VERSION ""

NS_ :

BS_:

BU_: PFAF_HS LVMPC_HS DCDC_HS AMP_HS VICM2_HS FICM_HS ARS_HS MCP_B_HS MCP_A_HS ICCM_OBD_HS SAS_HS ACCM_HS VLBS_HS EBCM_OBD_HS EDI_HS HPCC_HS VITM_OBD_HS PTAM_HS OBCM_HS VICM_HS HCP_HS FDCM_HS APPS_HS ICCM_HS EOCM_F_HS GPCM_HS FSCM_ITBC_HS SCM_HS ITBC_HS VCM_HS HMIM_HS FCP_HS VES_HS Dummy_HS MCP_C_HS RWS_HS ONSTAR_HS EPS_HS TestTool_HS MCP_HS BCP_HS ALC_HS AHL_AFL_HS SADS_HS EPB_HS FSCM_HS AFS_HS FCM_HS TCCM_HS RDCM_HS PTO_HS PCM_HS EBCM_HS ACC_HS BCM_HS TCM_HS ECM_HS

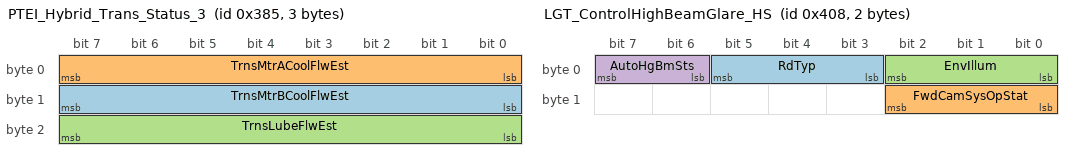
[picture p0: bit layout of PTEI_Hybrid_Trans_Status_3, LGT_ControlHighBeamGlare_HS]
BO_ 901 PTEI_Hybrid_Trans_Status_3: 3 TCM_HS
 SG_ TrnsMtrBCoolFlwEst : 15|8@0+ (0.05,0) [0|12.75] "l/min"  HCP_HS
 SG_ TrnsMtrACoolFlwEst : 7|8@0+ (0.05,0) [0|12.75] "l/min"  HCP_HS
 SG_ TrnsLubeFlwEst : 23|8@0+ (0.0625,0) [0|15.9375] "l/min"  HCP_HS

BO_ 1032 LGT_ControlHighBeamGlare_HS: 2 FCM_HS
 SG_ RdTyp : 5|3@0+ (1,0) [0|7] ""  AHL_AFL_HS
 SG_ FwdCamSysOpStat : 10|3@0+ (1,0) [0|7] ""  AHL_AFL_HS
 SG_ EnvIllum : 2|3@0+ (1,0) [0|7] ""  AHL_AFL_HS
 SG_ AutoHgBmSts : 7|2@0+ (1,0) [0|3] ""  AHL_AFL_HS

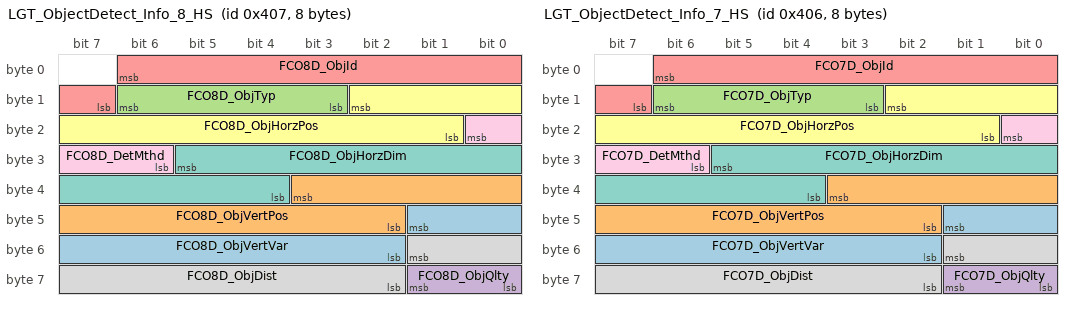
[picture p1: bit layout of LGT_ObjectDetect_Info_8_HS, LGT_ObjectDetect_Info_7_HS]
BO_ 1031 LGT_ObjectDetect_Info_8_HS: 8 FCM_HS
 SG_ FCO8D_ObjVertVar : 41|8@0- (0.05,0) [-6.4|6.35] "deg"  AHL_AFL_HS
 SG_ FCO8D_ObjVertPos : 35|10@0- (0.05,0) [-25.6|25.55] "deg"  AHL_AFL_HS
 SG_ FCO8D_ObjTyp : 14|4@0+ (1,0) [0|15] ""  AHL_AFL_HS
 SG_ FCO8D_ObjQlty : 57|2@0+ (1,0) [0|3] ""  AHL_AFL_HS
 SG_ FCO8D_ObjId : 6|8@0+ (1,0) [0|255] ""  AHL_AFL_HS
 SG_ FCO8D_ObjHorzPos : 10|10@0- (0.05,0) [-25.6|25.55] "deg"  AHL_AFL_HS
 SG_ FCO8D_ObjHorzDim : 29|10@0+ (0.01,0) [0|10.23] "deg"  AHL_AFL_HS
 SG_ FCO8D_ObjDist : 49|8@0+ (2,0) [0|510] "m"  AHL_AFL_HS
 SG_ FCO8D_DetMthd : 16|3@0+ (1,0) [0|7] ""  AHL_AFL_HS

BO_ 1030 LGT_ObjectDetect_Info_7_HS: 8 FCM_HS
 SG_ FCO7D_ObjVertVar : 41|8@0- (0.05,0) [-6.4|6.35] "deg"  AHL_AFL_HS
 SG_ FCO7D_ObjVertPos : 35|10@0- (0.05,0) [-25.6|25.55] "deg"  AHL_AFL_HS
 SG_ FCO7D_ObjTyp : 14|4@0+ (1,0) [0|15] ""  AHL_AFL_HS
 SG_ FCO7D_ObjQlty : 57|2@0+ (1,0) [0|3] ""  AHL_AFL_HS
 SG_ FCO7D_ObjId : 6|8@0+ (1,0) [0|255] ""  AHL_AFL_HS
 SG_ FCO7D_ObjHorzPos : 10|10@0- (0.05,0) [-25.6|25.55] "deg"  AHL_AFL_HS
 SG_ FCO7D_ObjHorzDim : 29|10@0+ (0.01,0) [0|10.23] "deg"  AHL_AFL_HS
 SG_ FCO7D_ObjDist : 49|8@0+ (2,0) [0|510] "m"  AHL_AFL_HS
 SG_ FCO7D_DetMthd : 16|3@0+ (1,0) [0|7] ""  AHL_AFL_HS

BO_ 479 PPEI_Propulsion_Gen_Stat_1_HS: 4 HCP_HS
 SG_ ASIRI_Indication16 : 24|1@0+ (1,0) [0|1] ""  BCM_HS
 SG_ ASIRI_Indication15 : 25|1@0+ (1,0) [0|1] ""  BCM_HS
 SG_ ASIRI_Indication14 : 26|1@0+ (1,0) [0|1] ""  BCM_HS
 SG_ ASIRI_Indication13 : 27|1@0+ (1,0) [0|1] ""  BCM_HS
 SG_ ASIRI_Indication12 : 28|1@0+ (1,0) [0|1] ""  BCM_HS
 SG_ ASIRI_Indication11 : 29|1@0+ (1,0) [0|1] ""  BCM_HS
 SG_ ASIRI_Indication10 : 30|1@0+ (1,0) [0|1] ""  BCM_HS
 SG_ ASIRI_Indication09 : 31|1@0+ (1,0) [0|1] ""  BCM_HS
 SG_ ASIRI_Indication08 : 16|1@0+ (1,0) [0|1] ""  BCM_HS
 SG_ ASIRI_Indication07 : 17|1@0+ (1,0) [0|1] ""  BCM_HS
 SG_ ASIRI_Indication06 : 18|1@0+ (1,0) [0|1] ""  BCM_HS
 SG_ ASIRI_Indication05 : 19|1@0+ (1,0) [0|1] ""  BCM_HS
 SG_ ASIRI_Indication04 : 20|1@0+ (1,0) [0|1] ""  BCM_HS
 SG_ ASIRI_Indication03 : 21|1@0+ (1,0) [0|1] ""  BCM_HS
 SG_ ASIRI_Indication02 : 22|1@0+ (1,0) [0|1] ""  BCM_HS
 SG_ ASIRI_Indication01 : 23|1@0+ (1,0) [0|1] ""  BCM_HS
 SG_ PTWrmgWtToShftIO : 5|1@0+ (1,0) [0|1] ""  BCM_HS
 SG_ PrplsnSysAtv : 7|1@0+ (1,0) [0|1] ""  EPB_HS,TCM_HS,ECM_HS,TCCM_HS,VICM_HS,ICCM_OBD_HS,ICCM_HS,FSCM_HS,ACCM_HS,EBCM_OBD_HS,EBCM_HS,OBCM_HS,VICM2_HS,VITM_OBD_HS
 SG_ PTShftLvrLckRqd : 6|1@0+ (1,0) [0|1] ""  BCM_HS

BO_ 211 PPEI_Hybrid_General_Status_3_HS: 2 HCP_HS
 SG_ ActAxleTrqV : 7|1@0+ (1,0) [0|1] ""  SADS_HS,ICCM_OBD_HS,ICCM_HS,TCM_HS,PCM_HS,ECM_HS,EBCM_OBD_HS,EBCM_HS,BCP_HS,EOCM_F_HS,VICM_HS,TCCM_HS,ACC_HS
 SG_ ActAxleTrq : 6|15@0+ (2,-22534) [-22534|43000] "Nm"  SADS_HS,ICCM_OBD_HS,ICCM_HS,EBCM_OBD_HS,EBCM_HS,TCM_HS,PCM_HS,ECM_HS,BCP_HS,EOCM_F_HS,TCCM_HS,VICM_HS,ACC_HS

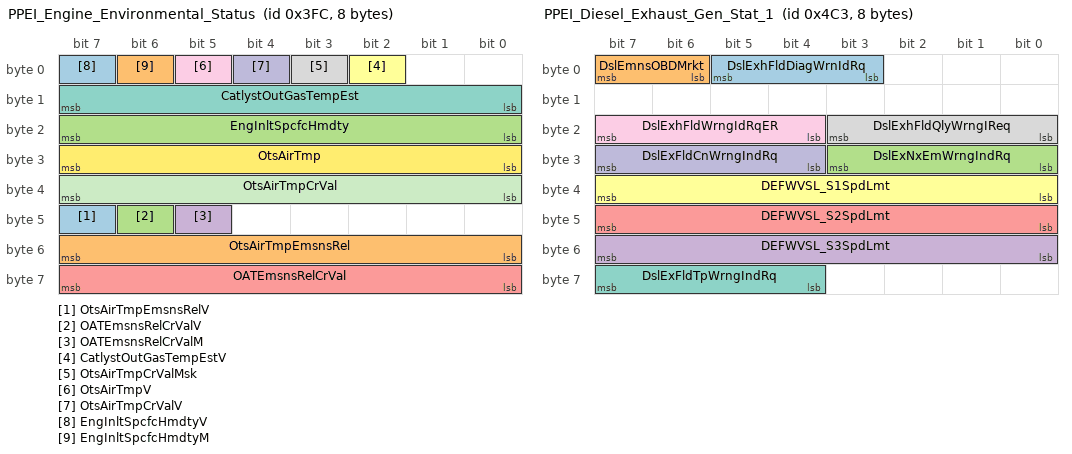
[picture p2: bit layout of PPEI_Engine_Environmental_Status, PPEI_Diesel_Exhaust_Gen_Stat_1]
BO_ 1020 PPEI_Engine_Environmental_Status: 8 ECM_HS
 SG_ OtsAirTmpEmsnsRelV : 47|1@0+ (1,0) [0|1] ""  VICM_HS
 SG_ OtsAirTmpEmsnsRel : 55|8@0+ (0.5,-40) [-40|87.5] "deg C"  VICM_HS
 SG_ OATEmsnsRelCrValV : 46|1@0+ (1,0) [0|1] ""  VICM_HS
 SG_ OATEmsnsRelCrValM : 45|1@0+ (1,0) [0|1] ""  VICM_HS
 SG_ OATEmsnsRelCrVal : 63|8@0+ (0.5,-40) [-40|87.5] "deg C"  VICM_HS
 SG_ CatlystOutGasTempEstV : 2|1@0+ (1,0) [0|1] ""  VICM_HS
 SG_ CatlystOutGasTempEst : 15|8@0+ (5,-40) [-40|1235] "deg C"  VICM_HS
 SG_ OtsAirTmpCrValMsk : 3|1@0+ (1,0) [0|1] ""  VICM_HS,BCM_HS
 SG_ OtsAirTmpV : 5|1@0+ (1,0) [0|1] ""  VICM_HS,BCM_HS
 SG_ OtsAirTmpCrValV : 4|1@0+ (1,0) [0|1] ""  VICM_HS,BCM_HS
 SG_ OtsAirTmpCrVal : 39|8@0+ (0.5,-40) [-40|87.5] "deg C"  VICM_HS,BCM_HS
 SG_ OtsAirTmp : 31|8@0+ (0.5,-40) [-40|87.5] "deg C"  VICM_HS,BCM_HS
 SG_ EngInltSpcfcHmdtyV : 7|1@0+ (1,0) [0|1] ""  VICM_HS,BCM_HS,EBCM_OBD_HS,EBCM_HS
 SG_ EngInltSpcfcHmdtyM : 6|1@0+ (1,0) [0|1] ""  VICM_HS,BCM_HS,EBCM_OBD_HS,EBCM_HS
 SG_ EngInltSpcfcHmdty : 23|8@0+ (0.0196078,0) [0|4.999989] "% water"  VICM_HS,BCM_HS,EBCM_OBD_HS,EBCM_HS

BO_ 1219 PPEI_Diesel_Exhaust_Gen_Stat_1: 8 ECM_HS
 SG_ DslExhFldDiagWrnIdRq : 5|3@0+ (1,0) [0|7] ""  BCM_HS
 SG_ DslEmnsOBDMrkt : 7|2@0+ (1,0) [0|3] ""  BCM_HS
 SG_ DslExNxEmWrngIndRq : 27|4@0+ (1,0) [0|15] ""  BCM_HS
 SG_ DEFWVSL_S3SpdLmt : 55|8@0+ (1,0) [0|255] "km / h"  BCM_HS
 SG_ DEFWVSL_S2SpdLmt : 47|8@0+ (1,0) [0|255] "km / h"  BCM_HS
 SG_ DEFWVSL_S1SpdLmt : 39|8@0+ (1,0) [0|255] "km / h"  BCM_HS
 SG_ DslExFldTpWrngIndRq : 63|4@0+ (1,0) [0|15] ""  BCM_HS
 SG_ DslExhFldQlyWrngIReq : 19|4@0+ (1,0) [0|15] ""  BCM_HS
 SG_ DslExhFldWrngIdRqER : 23|4@0+ (1,0) [0|15] ""  BCM_HS,FCP_HS,ONSTAR_HS
 SG_ DslExFldCnWrngIndRq : 31|4@0+ (1,0) [0|15] ""  BCM_HS

BO_ 372 Active_Rear_Steer_Fail_Indctn_HS: 1 ARS_HS
 SG_ ARSFlrIO : 0|1@0+ (1,0) [0|1] ""  BCM_HS

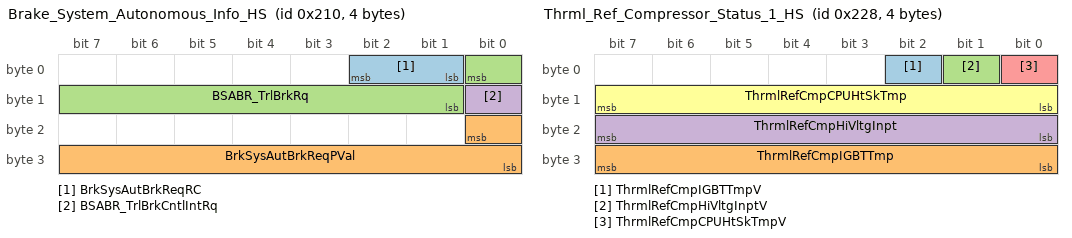
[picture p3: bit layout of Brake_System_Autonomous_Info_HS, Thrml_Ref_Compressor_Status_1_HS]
BO_ 528 Brake_System_Autonomous_Info_HS: 4 EBCM_HS
 SG_ BrkSysAutBrkReqRC : 2|2@0+ (1,0) [0|3] ""  FSCM_ITBC_HS
 SG_ BrkSysAutBrkReqPVal : 16|9@0+ (1,0) [0|511] ""  FSCM_ITBC_HS
 SG_ BSABR_TrlBrkRq : 0|8@0+ (0.392157,0) [0|100.000035] "%"  FSCM_ITBC_HS
 SG_ BSABR_TrlBrkCntlIntRq : 8|1@0+ (1,0) [0|1] ""  FSCM_ITBC_HS

BO_ 552 Thrml_Ref_Compressor_Status_1_HS: 4 ACCM_HS
 SG_ ThrmlRefCmpIGBTTmpV : 2|1@0+ (1,0) [0|1] ""  VICM_HS
 SG_ ThrmlRefCmpIGBTTmp : 31|8@0+ (1,-40) [-40|215] "deg C"  VICM_HS
 SG_ ThrmlRefCmpHiVltgInptV : 1|1@0+ (1,0) [0|1] ""  VICM_HS
 SG_ ThrmlRefCmpHiVltgInpt : 23|8@0+ (4,0) [0|1020] "V"  VICM_HS
 SG_ ThrmlRefCmpCPUHtSkTmpV : 0|1@0+ (1,0) [0|1] ""  VICM_HS
 SG_ ThrmlRefCmpCPUHtSkTmp : 15|8@0+ (1,-40) [-40|215] "deg C"  VICM_HS

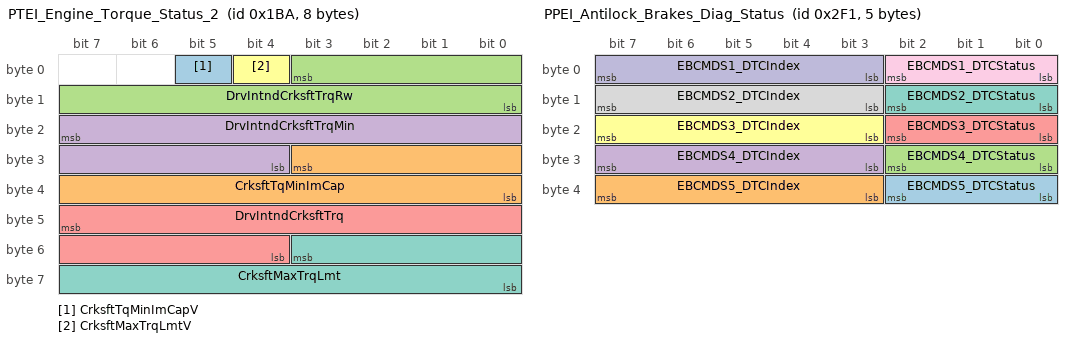
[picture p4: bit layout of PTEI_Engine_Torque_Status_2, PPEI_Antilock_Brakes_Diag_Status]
BO_ 442 PTEI_Engine_Torque_Status_2: 8 ECM_HS
 SG_ CrksftTqMinImCapV : 5|1@0+ (1,0) [0|1] ""  TCM_HS
 SG_ CrksftTqMinImCap : 27|12@0+ (0.5,-848) [-848|1199.5] "Nm"  TCM_HS
 SG_ DrvIntndCrksftTrqRw : 3|12@0+ (0.5,-848) [-848|1199.5] "Nm"  TCM_HS
 SG_ DrvIntndCrksftTrqMin : 23|12@0+ (0.5,-848) [-848|1199.5] "Nm"  TCM_HS
 SG_ DrvIntndCrksftTrq : 47|12@0+ (0.5,-848) [-848|1199.5] "Nm"  TCM_HS
 SG_ CrksftMaxTrqLmtV : 4|1@0+ (1,0) [0|1] ""  TCM_HS
 SG_ CrksftMaxTrqLmt : 51|12@0+ (0.5,-848) [-848|1199.5] "Nm"  TCM_HS

BO_ 753 PPEI_Antilock_Brakes_Diag_Status: 5 EBCM_HS
 SG_ EBCMDS5_DTCStatus : 34|3@0+ (1,0) [0|7] ""  ECM_HS
 SG_ EBCMDS5_DTCIndex : 39|5@0+ (1,0) [0|31] ""  ECM_HS
 SG_ EBCMDS4_DTCStatus : 26|3@0+ (1,0) [0|7] ""  ECM_HS
 SG_ EBCMDS4_DTCIndex : 31|5@0+ (1,0) [0|31] ""  ECM_HS
 SG_ EBCMDS3_DTCStatus : 18|3@0+ (1,0) [0|7] ""  ECM_HS
 SG_ EBCMDS3_DTCIndex : 23|5@0+ (1,0) [0|31] ""  ECM_HS
 SG_ EBCMDS2_DTCStatus : 10|3@0+ (1,0) [0|7] ""  ECM_HS
 SG_ EBCMDS2_DTCIndex : 15|5@0+ (1,0) [0|31] ""  ECM_HS
 SG_ EBCMDS1_DTCStatus : 2|3@0+ (1,0) [0|7] ""  ECM_HS
 SG_ EBCMDS1_DTCIndex : 7|5@0+ (1,0) [0|31] ""  ECM_HS

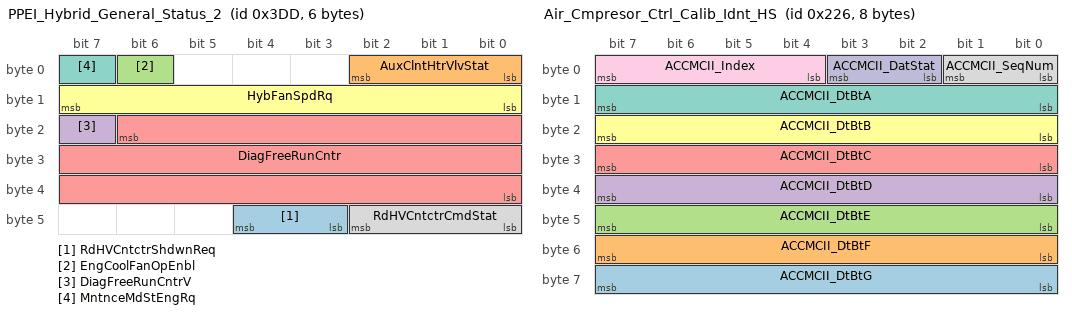
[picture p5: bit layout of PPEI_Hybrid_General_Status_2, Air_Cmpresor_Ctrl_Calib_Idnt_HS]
BO_ 989 PPEI_Hybrid_General_Status_2: 6 VICM_HS
 SG_ RdHVCntctrShdwnReq : 44|2@0+ (1,0) [0|3] ""  HCP_HS
 SG_ AuxClntHtrVlvStat : 2|3@0+ (1,0) [0|7] ""  PCM_HS,ECM_HS
 SG_ EngCoolFanOpEnbl : 6|1@0+ (1,0) [0|1] ""  PCM_HS,ECM_HS
 SG_ DiagFreeRunCntrV : 23|1@0+ (1,0) [0|1] ""  ECM_HS
 SG_ DiagFreeRunCntr : 22|23@0+ (1,0) [0|8388607] "min"  ECM_HS
 SG_ HybFanSpdRq : 15|8@0+ (0.392157,0) [0|100.000035] "%"  PCM_HS,ECM_HS
 SG_ MntnceMdStEngRq : 7|1@0+ (1,0) [0|1] ""  ECM_HS
 SG_ RdHVCntctrCmdStat : 42|3@0+ (1,0) [0|7] ""  HCP_HS

BO_ 550 Air_Cmpresor_Ctrl_Calib_Idnt_HS: 8 ACCM_HS
 SG_ ACCMCII_DtBtG : 63|8@0+ (1,0) [0|0] ""  VICM_HS
 SG_ ACCMCII_DtBtF : 55|8@0+ (1,0) [0|0] ""  VICM_HS
 SG_ ACCMCII_DtBtE : 47|8@0+ (1,0) [0|0] ""  VICM_HS
 SG_ ACCMCII_DtBtD : 39|8@0+ (1,0) [0|0] ""  VICM_HS
 SG_ ACCMCII_DtBtC : 31|8@0+ (1,0) [0|0] ""  VICM_HS
 SG_ ACCMCII_DtBtB : 23|8@0+ (1,0) [0|0] ""  VICM_HS
 SG_ ACCMCII_DtBtA : 15|8@0+ (1,0) [0|0] ""  VICM_HS
 SG_ ACCMCII_SeqNum : 1|2@0+ (1,0) [0|3] ""  VICM_HS
 SG_ ACCMCII_Index : 7|4@0+ (1,0) [0|15] ""  VICM_HS
 SG_ ACCMCII_DatStat : 3|2@0+ (1,0) [0|3] ""  VICM_HS

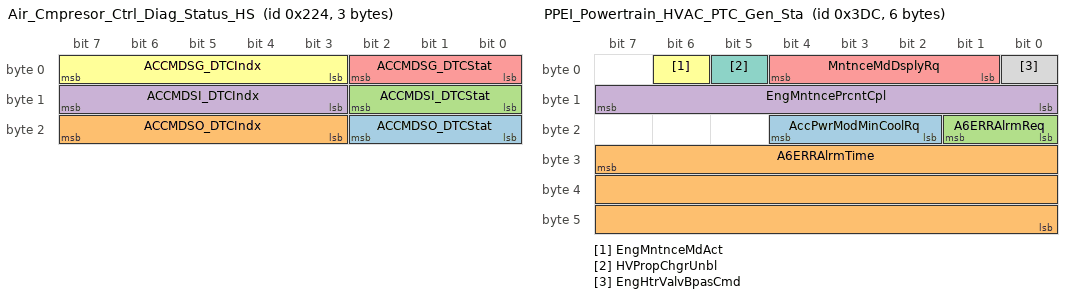
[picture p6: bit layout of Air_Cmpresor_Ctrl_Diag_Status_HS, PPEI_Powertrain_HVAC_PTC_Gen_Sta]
BO_ 548 Air_Cmpresor_Ctrl_Diag_Status_HS: 3 ACCM_HS
 SG_ ACCMDSO_DTCStat : 18|3@0+ (1,0) [0|7] ""  VICM_HS
 SG_ ACCMDSO_DTCIndx : 23|5@0+ (1,0) [0|31] ""  VICM_HS
 SG_ ACCMDSI_DTCStat : 10|3@0+ (1,0) [0|7] ""  VICM_HS
 SG_ ACCMDSI_DTCIndx : 15|5@0+ (1,0) [0|31] ""  VICM_HS
 SG_ ACCMDSG_DTCStat : 2|3@0+ (1,0) [0|7] ""  VICM_HS
 SG_ ACCMDSG_DTCIndx : 7|5@0+ (1,0) [0|31] ""  VICM_HS

BO_ 988 PPEI_Powertrain_HVAC_PTC_Gen_Sta: 6 ECM_HS
 SG_ AccPwrModMinCoolRq : 20|3@0+ (1,0) [0|7] ""  VICM_HS
 SG_ A6ERRAlrmTime : 31|24@0+ (1,0) [0|16777215] "min"  VICM_HS
 SG_ A6ERRAlrmReq : 17|2@0+ (1,0) [0|3] ""  VICM_HS
 SG_ EngMntncePrcntCpl : 15|8@0+ (0.392157,0) [0|100.000035] "%"  VICM_HS
 SG_ MntnceMdDsplyRq : 4|4@0+ (1,0) [0|15] ""  VICM_HS
 SG_ EngMntnceMdAct : 6|1@0+ (1,0) [0|1] ""  VICM_HS
 SG_ HVPropChgrUnbl : 5|1@0+ (1,0) [0|1] ""  HCP_HS,VICM_HS
 SG_ EngHtrValvBpasCmd : 0|1@0+ (1,0) [0|1] ""  VICM_HS

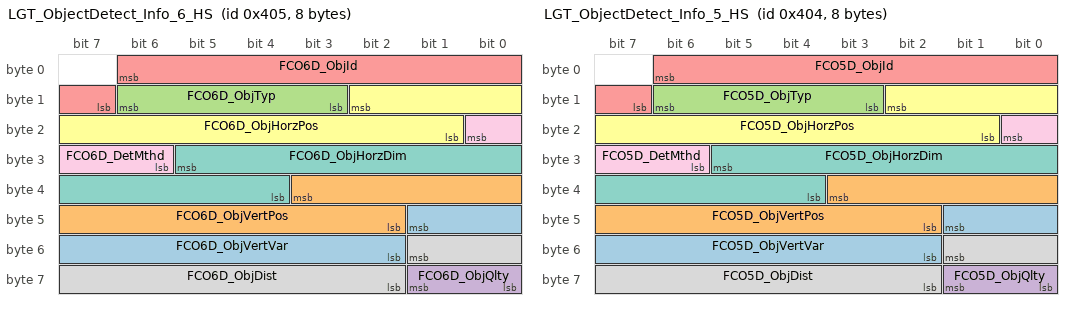
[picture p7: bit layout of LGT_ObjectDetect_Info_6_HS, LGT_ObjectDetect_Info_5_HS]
BO_ 1029 LGT_ObjectDetect_Info_6_HS: 8 FCM_HS
 SG_ FCO6D_ObjVertVar : 41|8@0- (0.05,0) [-6.4|6.35] "deg"  AHL_AFL_HS
 SG_ FCO6D_ObjVertPos : 35|10@0- (0.05,0) [-25.6|25.55] "deg"  AHL_AFL_HS
 SG_ FCO6D_ObjTyp : 14|4@0+ (1,0) [0|15] ""  AHL_AFL_HS
 SG_ FCO6D_ObjQlty : 57|2@0+ (1,0) [0|3] ""  AHL_AFL_HS
 SG_ FCO6D_ObjId : 6|8@0+ (1,0) [0|255] ""  AHL_AFL_HS
 SG_ FCO6D_ObjHorzPos : 10|10@0- (0.05,0) [-25.6|25.55] "deg"  AHL_AFL_HS
 SG_ FCO6D_ObjHorzDim : 29|10@0+ (0.01,0) [0|10.23] "deg"  AHL_AFL_HS
 SG_ FCO6D_ObjDist : 49|8@0+ (2,0) [0|510] "m"  AHL_AFL_HS
 SG_ FCO6D_DetMthd : 16|3@0+ (1,0) [0|7] ""  AHL_AFL_HS

BO_ 1028 LGT_ObjectDetect_Info_5_HS: 8 FCM_HS
 SG_ FCO5D_ObjVertVar : 41|8@0- (0.05,0) [-6.4|6.35] "deg"  AHL_AFL_HS
 SG_ FCO5D_ObjVertPos : 35|10@0- (0.05,0) [-25.6|25.55] "deg"  AHL_AFL_HS
 SG_ FCO5D_ObjTyp : 14|4@0+ (1,0) [0|15] ""  AHL_AFL_HS
 SG_ FCO5D_ObjQlty : 57|2@0+ (1,0) [0|3] ""  AHL_AFL_HS
 SG_ FCO5D_ObjId : 6|8@0+ (1,0) [0|255] ""  AHL_AFL_HS
 SG_ FCO5D_ObjHorzPos : 10|10@0- (0.05,0) [-25.6|25.55] "deg"  AHL_AFL_HS
 SG_ FCO5D_ObjHorzDim : 29|10@0+ (0.01,0) [0|10.23] ""  AHL_AFL_HS
 SG_ FCO5D_ObjDist : 49|8@0+ (2,0) [0|510] "m"  AHL_AFL_HS
 SG_ FCO5D_DetMthd : 16|3@0+ (1,0) [0|7] ""  AHL_AFL_HS

BO_ 500 PPEI_Drv_Pref_Mode_Switch_Status: 6 ECM_HS
 SG_ EnhDrvMdSwChUseAct : 40|1@0+ (1,0) [0|1] ""  EBCM_OBD_HS,EBCM_HS
 SG_ EnhDrvSelMdSwStat : 42|2@0+ (1,0) [0|3] ""  EBCM_OBD_HS,EBCM_HS
 SG_ DrvSelMd8Stat : 17|1@0+ (1,0) [0|1] ""  EBCM_OBD_HS,EBCM_HS,BCM_HS
 SG_ DrvSelMd8ReqDnd : 16|1@0+ (1,0) [0|1] ""  BCM_HS
 SG_ DrvSelMd7Stat : 19|1@0+ (1,0) [0|1] ""  EBCM_OBD_HS,EBCM_HS,BCM_HS
 SG_ DrvSelMd7ReqDnd : 18|1@0+ (1,0) [0|1] ""  BCM_HS
 SG_ DrvSelMd6Stat : 21|1@0+ (1,0) [0|1] ""  EBCM_OBD_HS,EBCM_HS,BCM_HS
 SG_ DrvSelMd6ReqDnd : 20|1@0+ (1,0) [0|1] ""  BCM_HS
 SG_ DrvSelMd5Stat : 23|1@0+ (1,0) [0|1] ""  EBCM_OBD_HS,EBCM_HS,BCM_HS
 SG_ DrvSelMd5ReqDnd : 22|1@0+ (1,0) [0|1] ""  BCM_HS
 SG_ DrvSelMd4Stat : 9|1@0+ (1,0) [0|1] ""  EBCM_OBD_HS,EBCM_HS,BCM_HS
 SG_ DrvSelMd4ReqDnd : 8|1@0+ (1,0) [0|1] ""  BCM_HS
 SG_ DrvSelMd3Stat : 11|1@0+ (1,0) [0|1] ""  EBCM_OBD_HS,EBCM_HS,BCM_HS
 SG_ DrvSelMd3ReqDnd : 10|1@0+ (1,0) [0|1] ""  BCM_HS
 SG_ DrvSelMd2Stat : 13|1@0+ (1,0) [0|1] ""  EBCM_OBD_HS,EBCM_HS,BCM_HS
 SG_ DrvSelMd2ReqDnd : 12|1@0+ (1,0) [0|1] ""  BCM_HS
 SG_ DSMSS_DrvSelMd0Pn : 47|1@0+ (1,0) [0|1] ""  EBCM_OBD_HS,EBCM_HS,BCM_HS
 SG_ DSMSS_DrvSelMd8Pn : 32|1@0+ (1,0) [0|1] ""  EBCM_OBD_HS,EBCM_HS,BCM_HS
 SG_ DSMSS_DrvSelMd7Pn : 33|1@0+ (1,0) [0|1] ""  EBCM_OBD_HS,EBCM_HS,BCM_HS
 SG_ DSMSS_DrvSelMd6Pn : 34|1@0+ (1,0) [0|1] ""  EBCM_OBD_HS,EBCM_HS,BCM_HS
 SG_ DSMSS_DrvSelMd5Pn : 35|1@0+ (1,0) [0|1] ""  EBCM_OBD_HS,EBCM_HS,BCM_HS
 SG_ DSMSS_DrvSelMd4Pn : 36|1@0+ (1,0) [0|1] ""  EBCM_OBD_HS,EBCM_HS,BCM_HS
 SG_ DSMSS_DrvSelMd3Pn : 37|1@0+ (1,0) [0|1] ""  EBCM_OBD_HS,EBCM_HS,BCM_HS
 SG_ DSMSS_DrvSelMd2Pn : 38|1@0+ (1,0) [0|1] ""  EBCM_OBD_HS,EBCM_HS,BCM_HS
 SG_ DSMSS_DrvSelMd1Pn : 39|1@0+ (1,0) [0|1] ""  EBCM_OBD_HS,EBCM_HS,BCM_HS
 SG_ DSMSS_DrvSelMd8Un : 24|1@0+ (1,0) [0|1] ""  EBCM_OBD_HS,EBCM_HS,BCM_HS
 SG_ DSMSS_DrvSelMd7Un : 25|1@0+ (1,0) [0|1] ""  EBCM_OBD_HS,EBCM_HS,BCM_HS
 SG_ DSMSS_DrvSelMd6Un : 26|1@0+ (1,0) [0|1] ""  EBCM_OBD_HS,EBCM_HS,BCM_HS
 SG_ DSMSS_DrvSelMd5Un : 27|1@0+ (1,0) [0|1] ""  EBCM_OBD_HS,EBCM_HS,BCM_HS
 SG_ DSMSS_DrvSelMd4Un : 28|1@0+ (1,0) [0|1] ""  EBCM_OBD_HS,EBCM_HS,BCM_HS
 SG_ DSMSS_DrvSelMd3Un : 29|1@0+ (1,0) [0|1] ""  EBCM_OBD_HS,EBCM_HS,BCM_HS
 SG_ DSMSS_DrvSelMd2Un : 30|1@0+ (1,0) [0|1] ""  EBCM_OBD_HS,EBCM_HS,BCM_HS
 SG_ DSMSS_DrvSelMd1Un : 31|1@0+ (1,0) [0|1] ""  EBCM_OBD_HS,EBCM_HS,BCM_HS
 SG_ DrvSelMd1ReqDnd : 14|1@0+ (1,0) [0|1] ""  VICM_HS,BCM_HS
 SG_ DrvSelMd1Stat : 15|1@0+ (1,0) [0|1] ""  EBCM_OBD_HS,EBCM_HS,BCM_HS

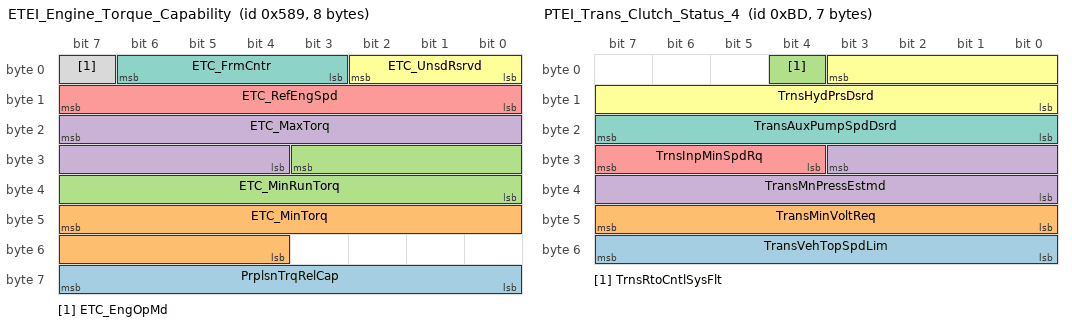
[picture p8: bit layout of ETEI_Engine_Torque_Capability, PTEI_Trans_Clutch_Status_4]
BO_ 1417 ETEI_Engine_Torque_Capability: 8 ECM_HS
 SG_ PrplsnTrqRelCap : 63|8@0+ (0.5,0) [0|127.5] "%"  TCM_HS
 SG_ ETC_MinTorq : 47|12@0+ (0.5,-848) [-848|1199.5] "Nm"  TCM_HS,HCP_HS,BCP_HS
 SG_ ETC_MinRunTorq : 27|12@0+ (0.5,-848) [-848|1199.5] "Nm"  TCM_HS,HCP_HS,BCP_HS
 SG_ ETC_MaxTorq : 23|12@0+ (0.5,-848) [-848|1199.5] "Nm"  TCM_HS,HCP_HS,BCP_HS
 SG_ ETC_RefEngSpd : 15|8@0+ (32,0) [0|8160] "rpm"  TCM_HS,HCP_HS,BCP_HS
 SG_ ETC_UnsdRsrvd : 2|3@0+ (1,0) [0|7] ""  TCM_HS,HCP_HS,BCP_HS
 SG_ ETC_FrmCntr : 6|4@0+ (1,0) [0|15] ""  TCM_HS,HCP_HS,BCP_HS
 SG_ ETC_EngOpMd : 7|1@0+ (1,0) [0|1] ""  TCM_HS,HCP_HS,BCP_HS

BO_ 407 PTEI_Trans_Ratio_Status: 2 TCM_HS
 SG_ TrnsOvrallActTorqRatioV : 7|1@0+ (1,0) [0|1] ""  PCM_HS,ECM_HS
 SG_ TrnsOvrallActTorqRatio : 6|15@0- (0.00390625,0) [-64|63.99609375] ""  PCM_HS,ECM_HS

BO_ 189 PTEI_Trans_Clutch_Status_4: 7 TCM_HS
 SG_ TransVehTopSpdLim : 55|8@0+ (2,0) [0|510] "km / h"  PCM_HS,ECM_HS
 SG_ TransMinVoltReq : 47|8@0+ (0.07843,0) [0|19.99965] "volts"  PCM_HS,ECM_HS
 SG_ TrnsRtoCntlSysFlt : 4|1@0+ (1,0) [0|1] "" Vector__XXX
 SG_ TransMnPressEstmd : 27|12@0+ (0.5,0) [0|2047.5] "kPa"  HCP_HS
 SG_ TrnsInpMinSpdRq : 31|4@0+ (1,0) [0|15] ""  HCP_HS
 SG_ TrnsHydPrsDsrd : 3|12@0+ (0.5,0) [0|2047.5] "kPa"  HCP_HS
 SG_ TransAuxPumpSpdDsrd : 23|8@0+ (0.392157,0) [0|100.000035] "%"  HCP_HS

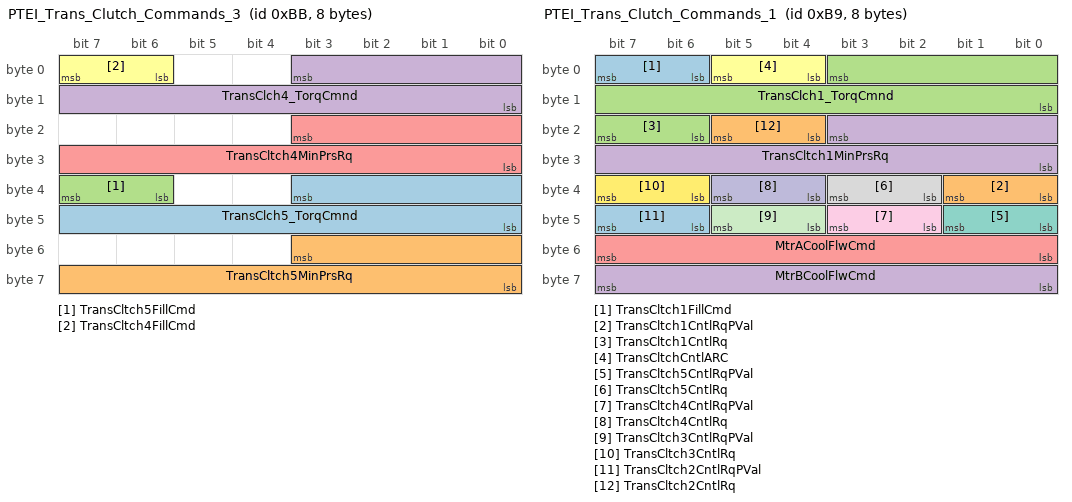
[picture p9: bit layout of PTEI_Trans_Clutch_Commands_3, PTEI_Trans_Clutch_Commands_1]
BO_ 187 PTEI_Trans_Clutch_Commands_3: 8 HCP_HS
 SG_ TransClch5_TorqCmnd : 35|12@0+ (0.5,-5) [-5|2042.5] "Nm"  TCM_HS
 SG_ TransCltch5MinPrsRq : 51|12@0+ (0.5,0) [0|2047.5] "kPa"  TCM_HS
 SG_ TransCltch5FillCmd : 39|2@0+ (1,0) [0|3] ""  TCM_HS
 SG_ TransClch4_TorqCmnd : 3|12@0+ (0.5,-5) [-5|2042.5] "Nm"  TCM_HS
 SG_ TransCltch4MinPrsRq : 19|12@0+ (0.5,0) [0|2047.5] "kPa"  TCM_HS
 SG_ TransCltch4FillCmd : 7|2@0+ (1,0) [0|3] ""  TCM_HS

BO_ 185 PTEI_Trans_Clutch_Commands_1: 8 HCP_HS
 SG_ TransCltch1FillCmd : 7|2@0+ (1,0) [0|3] ""  TCM_HS
 SG_ TransCltch1CntlRqPVal : 33|2@0+ (1,0) [0|3] ""  TCM_HS
 SG_ TransCltch1CntlRq : 23|2@0+ (1,0) [0|3] ""  TCM_HS
 SG_ MtrBCoolFlwCmd : 63|8@0+ (0.05,0) [0|12.75] "l/min"  TCM_HS
 SG_ MtrACoolFlwCmd : 55|8@0+ (0.05,0) [0|12.75] "l/min"  TCM_HS
 SG_ TransCltchCntlARC : 5|2@0+ (1,0) [0|3] ""  TCM_HS
 SG_ TransCltch5CntlRqPVal : 41|2@0+ (1,0) [0|3] ""  TCM_HS
 SG_ TransCltch5CntlRq : 35|2@0+ (1,0) [0|3] ""  TCM_HS
 SG_ TransCltch4CntlRqPVal : 43|2@0+ (1,0) [0|3] ""  TCM_HS
 SG_ TransCltch4CntlRq : 37|2@0+ (1,0) [0|3] ""  TCM_HS
 SG_ TransCltch3CntlRqPVal : 45|2@0+ (1,0) [0|3] ""  TCM_HS
 SG_ TransCltch3CntlRq : 39|2@0+ (1,0) [0|3] ""  TCM_HS
 SG_ TransCltch2CntlRqPVal : 47|2@0+ (1,0) [0|3] ""  TCM_HS
 SG_ TransCltch2CntlRq : 21|2@0+ (1,0) [0|3] ""  TCM_HS
 SG_ TransClch1_TorqCmnd : 3|12@0+ (0.5,-5) [-5|2042.5] "Nm"  TCM_HS
 SG_ TransCltch1MinPrsRq : 19|12@0+ (0.5,0) [0|2047.5] "kPa"  TCM_HS

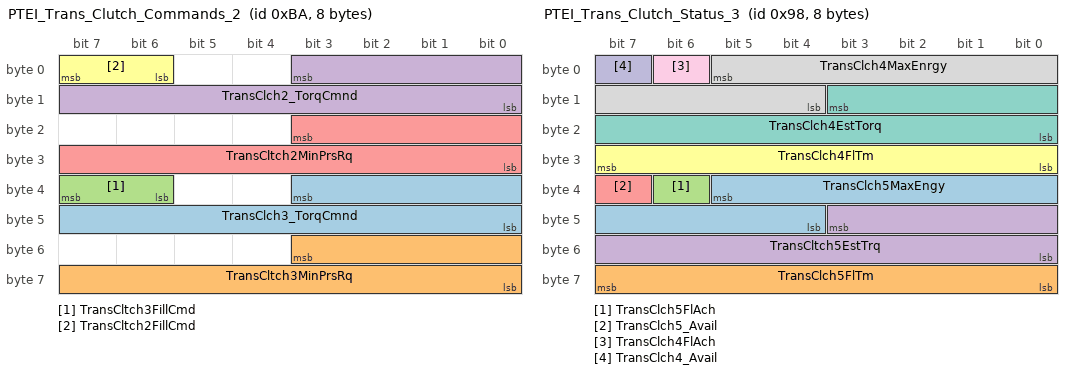
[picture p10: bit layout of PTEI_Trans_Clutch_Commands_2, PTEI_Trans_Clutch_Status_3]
BO_ 186 PTEI_Trans_Clutch_Commands_2: 8 HCP_HS
 SG_ TransClch3_TorqCmnd : 35|12@0+ (0.5,-5) [-5|2042.5] "Nm"  TCM_HS
 SG_ TransCltch3MinPrsRq : 51|12@0+ (0.5,0) [0|2047.5] "kPa"  TCM_HS
 SG_ TransCltch3FillCmd : 39|2@0+ (1,0) [0|3] ""  TCM_HS
 SG_ TransClch2_TorqCmnd : 3|12@0+ (0.5,-5) [-5|2042.5] "Nm"  TCM_HS
 SG_ TransCltch2MinPrsRq : 19|12@0+ (0.5,0) [0|2047.5] "kPa"  TCM_HS
 SG_ TransCltch2FillCmd : 7|2@0+ (1,0) [0|3] ""  TCM_HS

BO_ 152 PTEI_Trans_Clutch_Status_3: 8 TCM_HS
 SG_ TransClch5MaxEngy : 37|10@0+ (50,0) [0|51150] "J"  HCP_HS
 SG_ TransClch5FlTm : 63|8@0+ (0.0125,0) [0|3.1875] "s"  HCP_HS
 SG_ TransClch5FlAch : 38|1@0+ (1,0) [0|1] ""  HCP_HS
 SG_ TransCltch5EstTrq : 43|12@0+ (0.5,-5) [-5|2042.5] "Nm"  HCP_HS
 SG_ TransClch5_Avail : 39|1@0+ (1,0) [0|1] ""  HCP_HS
 SG_ TransClch4FlTm : 31|8@0+ (0.0125,0) [0|3.1875] "s"  HCP_HS
 SG_ TransClch4EstTorq : 11|12@0+ (0.5,-5) [-5|2042.5] "Nm"  HCP_HS
 SG_ TransClch4MaxEnrgy : 5|10@0+ (50,0) [0|51150] "J"  HCP_HS
 SG_ TransClch4FlAch : 6|1@0+ (1,0) [0|1] ""  HCP_HS
 SG_ TransClch4_Avail : 7|1@0+ (1,0) [0|1] ""  HCP_HS

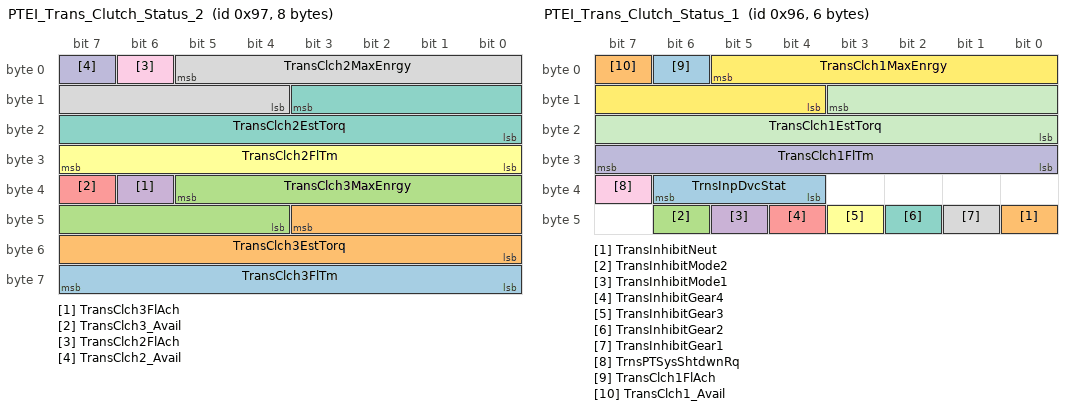
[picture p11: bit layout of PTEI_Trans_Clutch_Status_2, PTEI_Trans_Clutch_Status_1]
BO_ 151 PTEI_Trans_Clutch_Status_2: 8 TCM_HS
 SG_ TransClch3FlTm : 63|8@0+ (0.0125,0) [0|3.1875] "s"  HCP_HS
 SG_ TransClch3EstTorq : 43|12@0+ (0.5,-5) [-5|2042.5] "Nm"  HCP_HS
 SG_ TransClch3MaxEnrgy : 37|10@0+ (50,0) [0|51150] "J"  HCP_HS
 SG_ TransClch3FlAch : 38|1@0+ (1,0) [0|1] ""  HCP_HS
 SG_ TransClch3_Avail : 39|1@0+ (1,0) [0|1] ""  HCP_HS
 SG_ TransClch2FlTm : 31|8@0+ (0.0125,0) [0|3.1875] "s"  HCP_HS
 SG_ TransClch2EstTorq : 11|12@0+ (0.5,-5) [-5|2042.5] "Nm"  HCP_HS
 SG_ TransClch2MaxEnrgy : 5|10@0+ (50,0) [0|51150] "J"  HCP_HS
 SG_ TransClch2FlAch : 6|1@0+ (1,0) [0|1] ""  HCP_HS
 SG_ TransClch2_Avail : 7|1@0+ (1,0) [0|1] ""  HCP_HS

BO_ 150 PTEI_Trans_Clutch_Status_1: 6 TCM_HS
 SG_ TrnsInpDvcStat : 38|3@0+ (1,0) [0|7] ""  HCP_HS
 SG_ TransInhibitNeut : 40|1@0+ (1,0) [0|1] ""  HCP_HS
 SG_ TransInhibitMode2 : 46|1@0+ (1,0) [0|1] ""  HCP_HS
 SG_ TransInhibitMode1 : 45|1@0+ (1,0) [0|1] ""  HCP_HS
 SG_ TransInhibitGear4 : 44|1@0+ (1,0) [0|1] ""  HCP_HS
 SG_ TransInhibitGear3 : 43|1@0+ (1,0) [0|1] ""  HCP_HS
 SG_ TransInhibitGear2 : 42|1@0+ (1,0) [0|1] ""  HCP_HS
 SG_ TransInhibitGear1 : 41|1@0+ (1,0) [0|1] ""  HCP_HS
 SG_ TrnsPTSysShtdwnRq : 39|1@0+ (1,0) [0|1] ""  HCP_HS
 SG_ TransClch1FlTm : 31|8@0+ (0.0125,0) [0|3.1875] "s"  HCP_HS
 SG_ TransClch1EstTorq : 11|12@0+ (0.5,-5) [-5|2042.5] "Nm"  HCP_HS
 SG_ TransClch1MaxEnrgy : 5|10@0+ (50,0) [0|51150] "J"  HCP_HS
 SG_ TransClch1FlAch : 6|1@0+ (1,0) [0|1] ""  HCP_HS
 SG_ TransClch1_Avail : 7|1@0+ (1,0) [0|1] ""  HCP_HS

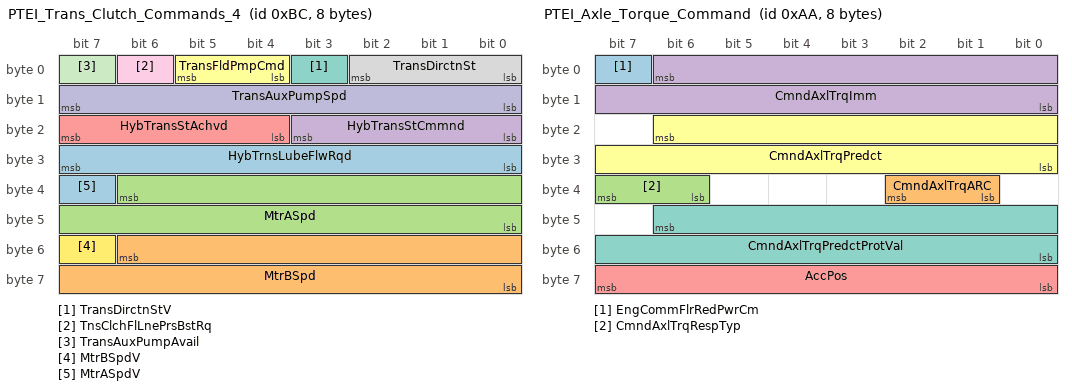
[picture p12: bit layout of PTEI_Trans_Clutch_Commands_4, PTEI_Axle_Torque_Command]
BO_ 188 PTEI_Trans_Clutch_Commands_4: 8 HCP_HS
 SG_ HybTrnsLubeFlwRqd : 31|8@0+ (0.0625,0) [0|15.9375] "l/min"  TCM_HS
 SG_ MtrBSpd : 54|15@0- (1,0) [-16384|16383] "rpm"  PFAF_HS,TCM_HS
 SG_ MtrASpd : 38|15@0- (1,0) [-16384|16383] "rpm"  TCM_HS
 SG_ HybTransStCmmnd : 19|4@0+ (1,0) [0|15] ""  TCM_HS
 SG_ HybTransStAchvd : 23|4@0+ (1,0) [0|15] ""  TCM_HS
 SG_ TransFldPmpCmd : 5|2@0+ (1,0) [0|3] ""  TCM_HS
 SG_ TransDirctnStV : 3|1@0+ (1,0) [0|1] ""  TCM_HS
 SG_ TransDirctnSt : 2|3@0+ (1,0) [0|7] ""  TCM_HS
 SG_ TnsClchFlLnePrsBstRq : 6|1@0+ (1,0) [0|1] ""  TCM_HS
 SG_ TransAuxPumpSpd : 15|8@0+ (0.392157,0) [0|100.000035] "%"  TCM_HS
 SG_ TransAuxPumpAvail : 7|1@0+ (1,0) [0|1] ""  TCM_HS
 SG_ MtrBSpdV : 55|1@0+ (1,0) [0|1] ""  PFAF_HS,TCM_HS
 SG_ MtrASpdV : 39|1@0+ (1,0) [0|1] ""  TCM_HS

BO_ 170 PTEI_Axle_Torque_Command: 8 ECM_HS
 SG_ EngCommFlrRedPwrCm : 7|1@0+ (1,0) [0|1] ""  HCP_HS
 SG_ CmndAxlTrqARC : 34|2@0+ (1,0) [0|3] ""  HCP_HS,EBCM_OBD_HS,EBCM_HS
 SG_ CmndAxlTrqRespTyp : 39|2@0+ (1,0) [0|3] ""  HCP_HS
 SG_ CmndAxlTrqImm : 6|15@0+ (2,-22534) [-22534|43000] "Nm"  HCP_HS
 SG_ AccPos : 63|8@0+ (0.392157,0) [0|100.000035] "%"  HCP_HS,TCM_HS
 SG_ CmndAxlTrqPredct : 22|15@0+ (2,-22534) [-22534|43000] "Nm"  EBCM_OBD_HS,EBCM_HS,HCP_HS
 SG_ CmndAxlTrqPredctProtVal : 46|15@0+ (1,0) [0|32767] ""  EBCM_OBD_HS,EBCM_HS,HCP_HS

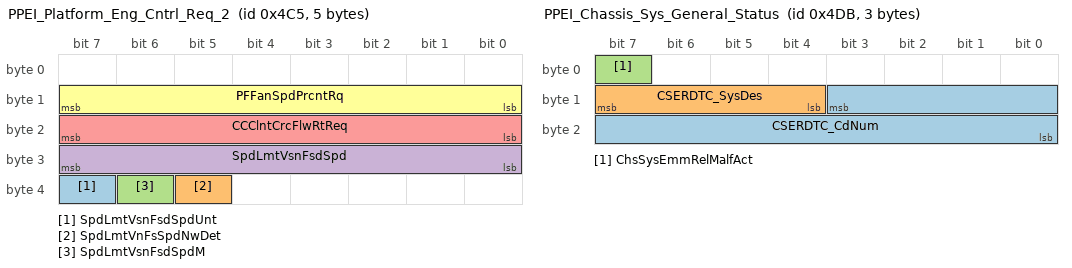
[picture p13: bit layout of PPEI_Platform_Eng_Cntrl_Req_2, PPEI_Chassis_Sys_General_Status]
BO_ 1221 PPEI_Platform_Eng_Cntrl_Req_2: 5 BCM_HS
 SG_ SpdLmtVsnFsdSpdUnt : 39|1@0+ (1,0) [0|1] ""  ECM_HS
 SG_ SpdLmtVnFsSpdNwDet : 37|1@0+ (1,0) [0|1] ""  ECM_HS
 SG_ SpdLmtVsnFsdSpdM : 38|1@0+ (1,0) [0|1] ""  ECM_HS
 SG_ SpdLmtVsnFsdSpd : 31|8@0+ (1,0) [0|255] ""  ECM_HS
 SG_ CCClntCrcFlwRtReq : 23|8@0+ (0.392157,0) [0|100.000035] "%"  VICM2_HS,PCM_HS,ECM_HS
 SG_ PFFanSpdPrcntRq : 15|8@0+ (0.392157,0) [0|100.000035] "%"  PCM_HS,ECM_HS

BO_ 1243 PPEI_Chassis_Sys_General_Status: 3 FSCM_HS
 SG_ CSERDTC_CdNum : 11|12@0+ (1,0) [0|4095] ""  ECM_HS
 SG_ CSERDTC_SysDes : 15|4@0+ (1,0) [0|15] ""  ECM_HS
 SG_ ChsSysEmmRelMalfAct : 7|1@0+ (1,0) [0|1] ""  ECM_HS

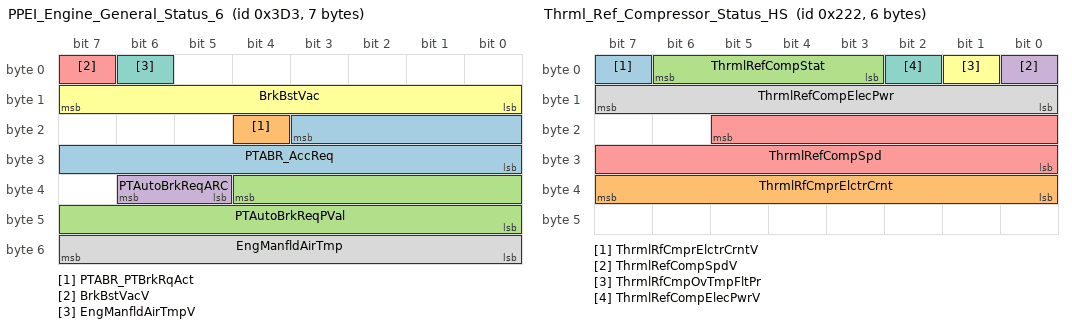
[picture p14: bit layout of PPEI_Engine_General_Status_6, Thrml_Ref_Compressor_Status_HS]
BO_ 979 PPEI_Engine_General_Status_6: 7 ECM_HS
 SG_ PTABR_AccReq : 19|12@0- (0.01,0) [-20.48|20.47] "m/s^2"  TCM_HS,EBCM_OBD_HS,EBCM_HS
 SG_ PTABR_PTBrkRqAct : 20|1@0+ (1,0) [0|1] ""  TCM_HS,EBCM_OBD_HS,EBCM_HS
 SG_ PTAutoBrkReqPVal : 36|13@0+ (1,0) [0|8191] ""  EBCM_OBD_HS,EBCM_HS
 SG_ PTAutoBrkReqARC : 38|2@0+ (1,0) [0|3] ""  EBCM_OBD_HS,EBCM_HS
 SG_ BrkBstVacV : 7|1@0+ (1,0) [0|1] ""  EBCM_OBD_HS,EBCM_HS
 SG_ BrkBstVac : 15|8@0+ (0.5,0) [0|127.5] "kPa"  EBCM_OBD_HS,EBCM_HS
 SG_ EngManfldAirTmpV : 6|1@0+ (1,0) [0|1] ""  BCM_HS
 SG_ EngManfldAirTmp : 55|8@0+ (1,-40) [-40|215] "deg C"  BCM_HS

BO_ 546 Thrml_Ref_Compressor_Status_HS: 6 ACCM_HS
 SG_ ThrmlRfCmprElctrCrntV : 7|1@0+ (1,0) [0|1] ""  VICM_HS
 SG_ ThrmlRfCmprElctrCrnt : 39|8@0+ (0.2,0) [0|51] "A"  VICM_HS
 SG_ ThrmlRefCompStat : 6|4@0+ (1,0) [0|15] ""  VICM_HS
 SG_ ThrmlRefCompSpdV : 0|1@0+ (1,0) [0|1] ""  ECM_HS,VICM_HS
 SG_ ThrmlRefCompSpd : 21|14@0+ (1,0) [0|16383] "rpm"  ECM_HS,VICM_HS
 SG_ ThrmlRfCmpOvTmpFltPr : 1|1@0+ (1,0) [0|1] ""  VICM_HS
 SG_ ThrmlRefCompElecPwrV : 2|1@0+ (1,0) [0|1] ""  VICM_HS
 SG_ ThrmlRefCompElecPwr : 15|8@0+ (0.04,0) [0|10.2] "kW"  VICM_HS

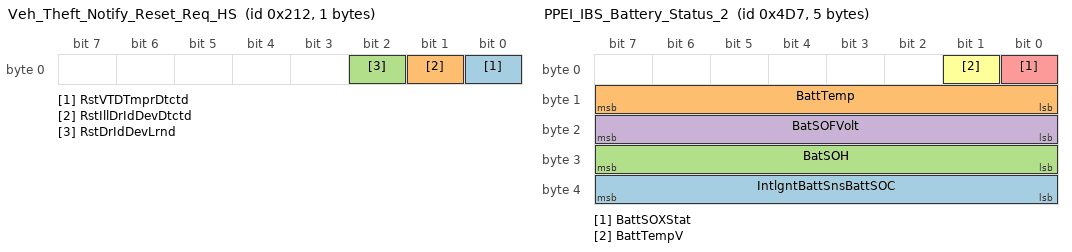
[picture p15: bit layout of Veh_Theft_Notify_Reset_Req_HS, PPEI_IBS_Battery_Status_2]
BO_ 530 Veh_Theft_Notify_Reset_Req_HS: 1 VLBS_HS
 SG_ RstVTDTmprDtctd : 0|1@0+ (1,0) [0|1] ""  BCM_HS
 SG_ RstIllDrIdDevDtctd : 1|1@0+ (1,0) [0|1] ""  BCM_HS
 SG_ RstDrIdDevLrnd : 2|1@0+ (1,0) [0|1] ""  BCM_HS

BO_ 1239 PPEI_IBS_Battery_Status_2: 5 BCM_HS
 SG_ IntlgntBattSnsBattSOC : 39|8@0+ (0.392157,0) [0|100.000035] "%"  ECM_HS
 SG_ BattTemp : 15|8@0+ (1,-40) [-40|215] "deg C"  ECM_HS
 SG_ BatSOH : 31|8@0+ (0.392157,0) [0|100.000035] "%"  ECM_HS
 SG_ BatSOFVolt : 23|8@0+ (0.05,0) [0|12.75] "volts"  ECM_HS
 SG_ BattSOXStat : 0|1@0+ (1,0) [0|1] ""  ECM_HS
 SG_ BattTempV : 1|1@0+ (1,0) [0|1] ""  ECM_HS

BO_ 1610 USDT_Resp_From_SAS_HS: 8 SAS_HS
 SG_ DgnInf : 7|64@0+ (1,0) [0|1.844674407371E+019] ""  FCP_HS,ONSTAR_HS,TestTool_HS

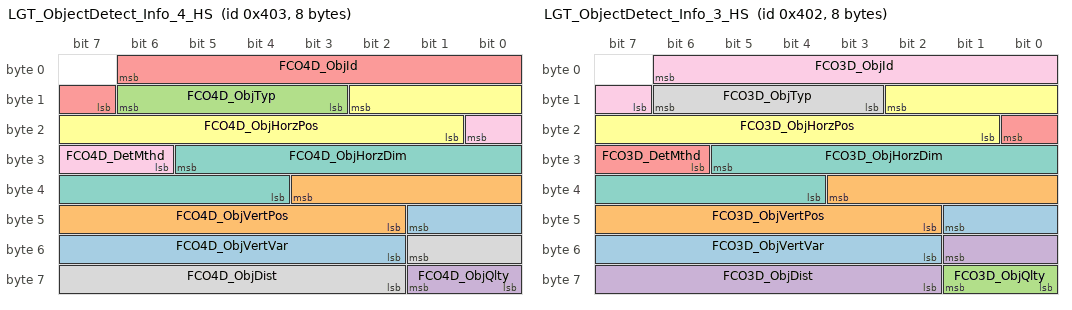
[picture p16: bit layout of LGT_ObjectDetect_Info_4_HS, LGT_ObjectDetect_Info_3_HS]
BO_ 1027 LGT_ObjectDetect_Info_4_HS: 8 FCM_HS
 SG_ FCO4D_ObjVertVar : 41|8@0- (0.05,0) [-6.4|6.35] "deg"  AHL_AFL_HS
 SG_ FCO4D_ObjVertPos : 35|10@0- (0.05,0) [-25.6|25.55] ""  AHL_AFL_HS
 SG_ FCO4D_ObjTyp : 14|4@0+ (1,0) [0|15] ""  AHL_AFL_HS
 SG_ FCO4D_ObjQlty : 57|2@0+ (1,0) [0|3] ""  AHL_AFL_HS
 SG_ FCO4D_ObjId : 6|8@0+ (1,0) [0|255] ""  AHL_AFL_HS
 SG_ FCO4D_ObjHorzPos : 10|10@0- (0.05,0) [-25.6|25.55] ""  AHL_AFL_HS
 SG_ FCO4D_ObjHorzDim : 29|10@0+ (0.01,0) [0|10.23] "deg"  AHL_AFL_HS
 SG_ FCO4D_ObjDist : 49|8@0+ (2,0) [0|510] "m"  AHL_AFL_HS
 SG_ FCO4D_DetMthd : 16|3@0+ (1,0) [0|7] ""  AHL_AFL_HS

BO_ 1026 LGT_ObjectDetect_Info_3_HS: 8 FCM_HS
 SG_ FCO3D_ObjVertVar : 41|8@0- (0.05,0) [-6.4|6.35] "deg"  AHL_AFL_HS
 SG_ FCO3D_ObjVertPos : 35|10@0- (0.05,0) [-25.6|25.55] "deg"  AHL_AFL_HS
 SG_ FCO3D_ObjQlty : 57|2@0+ (1,0) [0|3] ""  AHL_AFL_HS
 SG_ FCO3D_ObjDist : 49|8@0+ (2,0) [0|510] "m"  AHL_AFL_HS
 SG_ FCO3D_DetMthd : 16|3@0+ (1,0) [0|7] ""  AHL_AFL_HS
 SG_ FCO3D_ObjHorzPos : 10|10@0- (0.05,0) [-25.6|25.55] "deg"  AHL_AFL_HS
 SG_ FCO3D_ObjHorzDim : 29|10@0+ (0.01,0) [0|10.23] "deg"  AHL_AFL_HS
 SG_ FCO3D_ObjTyp : 14|4@0+ (1,0) [0|15] ""  AHL_AFL_HS
 SG_ FCO3D_ObjId : 6|8@0+ (1,0) [0|255] ""  AHL_AFL_HS

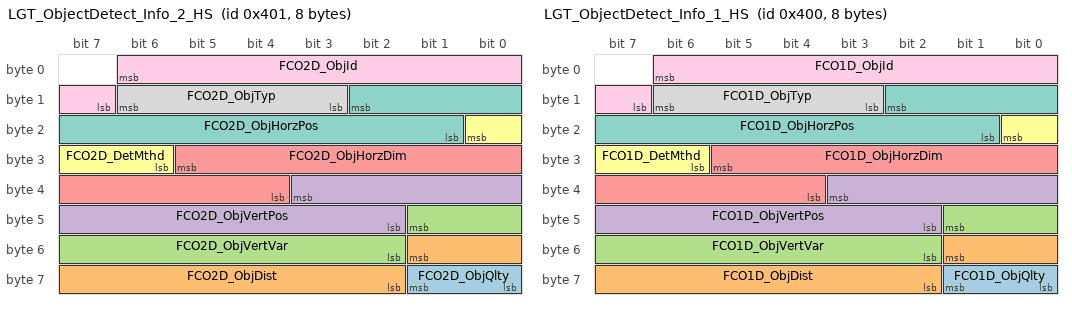
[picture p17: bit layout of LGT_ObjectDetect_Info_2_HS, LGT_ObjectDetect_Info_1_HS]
BO_ 1025 LGT_ObjectDetect_Info_2_HS: 8 FCM_HS
 SG_ FCO2D_ObjQlty : 57|2@0+ (1,0) [0|3] ""  AHL_AFL_HS
 SG_ FCO2D_ObjDist : 49|8@0+ (2,0) [0|510] "m"  AHL_AFL_HS
 SG_ FCO2D_ObjVertVar : 41|8@0- (0.05,0) [-6.4|6.35] "deg"  AHL_AFL_HS
 SG_ FCO2D_ObjVertPos : 35|10@0- (0.05,0) [-25.6|25.55] "deg"  AHL_AFL_HS
 SG_ FCO2D_ObjHorzDim : 29|10@0+ (0.01,0) [0|10.23] "deg"  AHL_AFL_HS
 SG_ FCO2D_DetMthd : 16|3@0+ (1,0) [0|7] ""  AHL_AFL_HS
 SG_ FCO2D_ObjHorzPos : 10|10@0- (0.05,0) [-25.6|25.55] "deg"  AHL_AFL_HS
 SG_ FCO2D_ObjTyp : 14|4@0+ (1,0) [0|15] ""  AHL_AFL_HS
 SG_ FCO2D_ObjId : 6|8@0+ (1,0) [0|255] ""  AHL_AFL_HS

BO_ 1024 LGT_ObjectDetect_Info_1_HS: 8 FCM_HS
 SG_ FCO1D_ObjQlty : 57|2@0+ (1,0) [0|3] ""  AHL_AFL_HS
 SG_ FCO1D_ObjDist : 49|8@0+ (2,0) [0|510] "m"  AHL_AFL_HS
 SG_ FCO1D_ObjVertVar : 41|8@0- (0.05,0) [-6.4|6.35] "deg"  AHL_AFL_HS
 SG_ FCO1D_ObjVertPos : 35|10@0- (0.05,0) [-25.6|25.55] "deg"  AHL_AFL_HS
 SG_ FCO1D_ObjHorzDim : 29|10@0+ (0.01,0) [0|10.23] "deg"  AHL_AFL_HS
 SG_ FCO1D_DetMthd : 16|3@0+ (1,0) [0|7] ""  AHL_AFL_HS
 SG_ FCO1D_ObjHorzPos : 10|10@0- (0.05,0) [-25.6|25.55] "deg"  AHL_AFL_HS
 SG_ FCO1D_ObjTyp : 14|4@0+ (1,0) [0|15] ""  AHL_AFL_HS
 SG_ FCO1D_ObjId : 6|8@0+ (1,0) [0|255] ""  AHL_AFL_HS

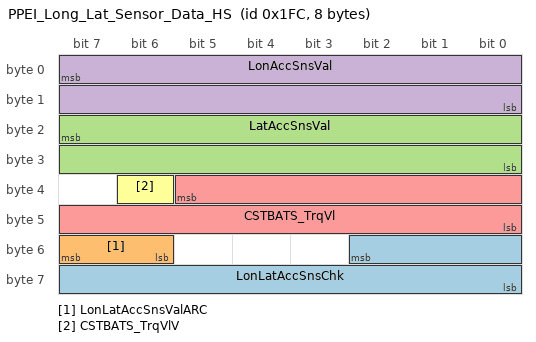
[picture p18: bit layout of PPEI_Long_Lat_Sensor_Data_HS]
BO_ 508 PPEI_Long_Lat_Sensor_Data_HS: 8 EBCM_HS
 SG_ LonLatAccSnsChk : 50|11@0+ (1,0) [0|2047] ""  ICCM_OBD_HS,ICCM_HS,TCM_HS
 SG_ LonLatAccSnsValARC : 55|2@0+ (1,0) [0|3] ""  ICCM_OBD_HS,ICCM_HS,TCM_HS
 SG_ LatAccSnsVal : 23|16@0- (0.00012207,0) [-3.99998976|3.99986769] "g's"  ICCM_OBD_HS,ICCM_HS,TCM_HS
 SG_ LonAccSnsVal : 7|16@0- (0.00012207,0) [-3.99998976|3.99986769] "g's"  ICCM_OBD_HS,ICCM_HS,TCM_HS
 SG_ CSTBATS_TrqVl : 37|14@0+ (2,0) [0|32766] "Nm"  ICCM_OBD_HS,ICCM_HS,TCM_HS
 SG_ CSTBATS_TrqVlV : 38|1@0+ (1,0) [0|1] ""  ICCM_OBD_HS,ICCM_HS,TCM_HS

BO_ 422 PTEI_Hybrid_Trans_Status_2: 1 TCM_HS
 SG_ TrStPTGrdBrkDsMdOvr : 5|2@0+ (1,0) [0|3] ""  PCM_HS,ECM_HS
 SG_ TrnsHybEngSrtStpOvrd : 7|2@0+ (1,0) [0|3] ""  BCP_HS

BO_TX_BU_ 479 : BCP_HS,ECM_HS,HCP_HS;
BO_TX_BU_ 211 : HCP_HS,PCM_HS,ECM_HS;
BO_TX_BU_ 1020 : PCM_HS,ECM_HS;
BO_TX_BU_ 528 : EBCM_OBD_HS,EBCM_HS;
BO_TX_BU_ 442 : PCM_HS,ECM_HS;
BO_TX_BU_ 753 : EBCM_OBD_HS,EBCM_HS;
BO_TX_BU_ 988 : PCM_HS,ECM_HS;
BO_TX_BU_ 500 : PCM_HS,ECM_HS;
BO_TX_BU_ 1417 : PCM_HS,ECM_HS;
BO_TX_BU_ 170 : PCM_HS,ECM_HS;
BO_TX_BU_ 1243 : ICCM_OBD_HS,ICCM_HS,FSCM_ITBC_HS,FSCM_HS;
BO_TX_BU_ 508 : EBCM_OBD_HS,EBCM_HS;
CM_ SG_ 979 BrkBstVac "0 kPA represents the sensor reading atmospheric pressure";
CM_ SG_ 1239 BatSOH "State of Health = the aging state of the Battery";
BA_DEF_ SG_  "VNSigSLHS_VNReq" ENUM  "No","Yes";
BA_DEF_ SG_  "VNSigSLHSSharedDiagnostic" ENUM  "No","Yes";
BA_DEF_ SG_  "SignalType" STRING ;
BA_DEF_ SG_  "PacketOrder" INT 0 65535;
BA_DEF_ SG_  "SignalLongName" STRING ;
BA_DEF_ SG_  "GenSigStartValue" INT 0 65535;
BA_DEF_ SG_  "VNSigAllNodes" ENUM  "No","Yes";
BA_DEF_ SG_  "GenSigDeltaValue" INT 0 0;
BA_DEF_ SG_  "GenSigSendType" ENUM  "not used","not used","not used","not used","not used","not used","not used","NoSigSendType","not used","not used","OnAnyChange","OnChangeIfActive","OnDelta";
BA_DEF_ SG_  "GenSigSendOnInit" ENUM  "Not Initialized","Application","Handler";
BA_DEF_ BO_  "AppGenMsgCycleTime" INT 0 0;
BA_DEF_ BO_  "GenMsgILSupport" ENUM  "No","Yes";
BA_DEF_ BO_  "TpApplType" STRING ;
BA_DEF_ BO_  "Prio" INT 0 7;
BA_DEF_ BO_  "MessageSubnet" ENUM  "LS","MS","HS","CE","PE","HV","FO";
BA_DEF_ BO_  "DiagState" ENUM  "No","Yes";
BA_DEF_ BO_  "GenMsgDelayTime" INT 0 100000;
BA_DEF_ BO_  "GenMsgCycleTime" INT 0 100000;
BA_DEF_ BO_  "GenMsgSendType" ENUM  "cyclicX","spontanX","cyclicIfActiveX","spontanWithDelay","cyclicAndSpontanX","cyclicAndSpontanWithDelay","spontanWithRepitition","cyclicIfActiveAndSpontanWD";
BA_DEF_ BO_  "DiagResponse" ENUM  "No","Yes";
BA_DEF_ BO_  "DiagRequest" ENUM  "No","Yes";
BA_DEF_ BO_  "NmMessage" ENUM  "No","Yes";
BA_DEF_REL_ BU_SG_REL_  "GenSigSuprvRespComment" STRING ;
BA_DEF_REL_ BU_SG_REL_  "GenSigVBitResp" ENUM  "No","Yes";
BA_DEF_REL_ BU_SG_REL_  "GenSigVBitRespComment" STRING ;
BA_DEF_REL_ BU_SG_REL_  "GenSigVDAFailComment" STRING ;
BA_DEF_REL_ BU_SG_REL_  "GenSigVDAFailResp" ENUM  "No","Yes";
BA_DEF_REL_ BU_SG_REL_  "GenSigRxStartValue" STRING ;
BA_DEF_REL_ BU_SG_REL_  "GenSigSuprvRespSubValue" INT 0 65535;
BA_DEF_REL_ BU_SG_REL_  "GenSigSuprvResp" ENUM  "None","Notify App","Substitute Default";
BA_DEF_REL_ BU_SG_REL_  "GenSigTimeoutMsg" HEX -2147483648 268435455;
BA_DEF_REL_ BU_SG_REL_  "GenSigTimeoutTime" INT 0 15000;
BA_DEF_DEF_  "VNSigSLHS_VNReq" "No";
BA_DEF_DEF_  "VNSigSLHSSharedDiagnostic" "No";
BA_DEF_DEF_  "SignalType" "";
BA_DEF_DEF_  "PacketOrder" 0;
BA_DEF_DEF_  "SignalLongName" "";
BA_DEF_DEF_  "GenSigStartValue" 0;
BA_DEF_DEF_  "VNSigAllNodes" "No";
BA_DEF_DEF_  "GenSigDeltaValue" 0;
BA_DEF_DEF_  "GenSigSendType" "NoSigSendType";
BA_DEF_DEF_  "GenSigSendOnInit" "Not Initialized";
BA_DEF_DEF_  "AppGenMsgCycleTime" 0;
BA_DEF_DEF_  "GenMsgILSupport" "Yes";
BA_DEF_DEF_  "TpApplType" "";
BA_DEF_DEF_  "Prio" 4;
BA_DEF_DEF_  "MessageSubnet" "FO";
BA_DEF_DEF_  "DiagState" "No";
BA_DEF_DEF_  "GenMsgDelayTime" 0;
BA_DEF_DEF_  "GenMsgCycleTime" 0;
BA_DEF_DEF_  "GenMsgSendType" "spontanX";
BA_DEF_DEF_  "DiagResponse" "No";
BA_DEF_DEF_  "DiagRequest" "No";
BA_DEF_DEF_  "NmMessage" "No";
BA_DEF_DEF_REL_ "GenSigSuprvRespComment" "";
BA_DEF_DEF_REL_ "GenSigVBitResp" "No";
BA_DEF_DEF_REL_ "GenSigVBitRespComment" "";
BA_DEF_DEF_REL_ "GenSigVDAFailComment" "";
BA_DEF_DEF_REL_ "GenSigVDAFailResp" "No";
BA_DEF_DEF_REL_ "GenSigRxStartValue" "";
BA_DEF_DEF_REL_ "GenSigSuprvRespSubValue" 0;
BA_DEF_DEF_REL_ "GenSigSuprvResp" "None";
BA_DEF_DEF_REL_ "GenSigTimeoutMsg" 0;
BA_DEF_DEF_REL_ "GenSigTimeoutTime" 0;
BA_ "Prio" BO_ 901 0;
BA_ "MessageSubnet" BO_ 901 2;
BA_ "GenMsgCycleTime" BO_ 901 100;
BA_ "GenMsgSendType" BO_ 901 0;
BA_ "Prio" BO_ 1032 0;
BA_ "MessageSubnet" BO_ 1032 2;
BA_ "GenMsgCycleTime" BO_ 1032 100;
BA_ "GenMsgSendType" BO_ 1032 0;
BA_ "Prio" BO_ 1031 0;
BA_ "MessageSubnet" BO_ 1031 2;
BA_ "GenMsgCycleTime" BO_ 1031 100;
BA_ "GenMsgSendType" BO_ 1031 0;
BA_ "Prio" BO_ 1030 0;
BA_ "MessageSubnet" BO_ 1030 2;
BA_ "GenMsgCycleTime" BO_ 1030 100;
BA_ "GenMsgSendType" BO_ 1030 0;
BA_ "Prio" BO_ 479 0;
BA_ "MessageSubnet" BO_ 479 2;
BA_ "GenMsgCycleTime" BO_ 479 25;
BA_ "GenMsgSendType" BO_ 479 0;
BA_ "Prio" BO_ 211 0;
BA_ "MessageSubnet" BO_ 211 2;
BA_ "GenMsgCycleTime" BO_ 211 12;
BA_ "GenMsgSendType" BO_ 211 0;
BA_ "Prio" BO_ 1020 0;
BA_ "MessageSubnet" BO_ 1020 2;
BA_ "GenMsgCycleTime" BO_ 1020 250;
BA_ "GenMsgSendType" BO_ 1020 0;
BA_ "Prio" BO_ 1219 0;
BA_ "MessageSubnet" BO_ 1219 2;
BA_ "GenMsgCycleTime" BO_ 1219 1000;
BA_ "GenMsgSendType" BO_ 1219 0;
BA_ "Prio" BO_ 372 0;
BA_ "MessageSubnet" BO_ 372 2;
BA_ "GenMsgCycleTime" BO_ 372 100;
BA_ "GenMsgSendType" BO_ 372 0;
BA_ "Prio" BO_ 528 0;
BA_ "MessageSubnet" BO_ 528 2;
BA_ "GenMsgCycleTime" BO_ 528 50;
BA_ "GenMsgSendType" BO_ 528 0;
BA_ "Prio" BO_ 552 0;
BA_ "MessageSubnet" BO_ 552 2;
BA_ "GenMsgCycleTime" BO_ 552 100;
BA_ "GenMsgSendType" BO_ 552 0;
BA_ "Prio" BO_ 442 0;
BA_ "MessageSubnet" BO_ 442 2;
BA_ "GenMsgCycleTime" BO_ 442 25;
BA_ "GenMsgSendType" BO_ 442 0;
BA_ "Prio" BO_ 753 0;
BA_ "MessageSubnet" BO_ 753 2;
BA_ "GenMsgCycleTime" BO_ 753 100;
BA_ "GenMsgSendType" BO_ 753 0;
BA_ "Prio" BO_ 989 0;
BA_ "MessageSubnet" BO_ 989 2;
BA_ "GenMsgCycleTime" BO_ 989 100;
BA_ "GenMsgSendType" BO_ 989 0;
BA_ "Prio" BO_ 550 0;
BA_ "MessageSubnet" BO_ 550 2;
BA_ "GenMsgCycleTime" BO_ 550 500;
BA_ "GenMsgSendType" BO_ 550 0;
BA_ "Prio" BO_ 548 0;
BA_ "MessageSubnet" BO_ 548 2;
BA_ "GenMsgCycleTime" BO_ 548 100;
BA_ "GenMsgSendType" BO_ 548 0;
BA_ "Prio" BO_ 988 0;
BA_ "MessageSubnet" BO_ 988 2;
BA_ "GenMsgCycleTime" BO_ 988 100;
BA_ "GenMsgSendType" BO_ 988 0;
BA_ "Prio" BO_ 1029 0;
BA_ "MessageSubnet" BO_ 1029 2;
BA_ "GenMsgCycleTime" BO_ 1029 100;
BA_ "GenMsgSendType" BO_ 1029 0;
BA_ "Prio" BO_ 1028 0;
BA_ "MessageSubnet" BO_ 1028 2;
BA_ "GenMsgCycleTime" BO_ 1028 100;
BA_ "GenMsgSendType" BO_ 1028 0;
BA_ "Prio" BO_ 500 0;
BA_ "MessageSubnet" BO_ 500 2;
BA_ "GenMsgCycleTime" BO_ 500 25;
BA_ "GenMsgSendType" BO_ 500 0;
BA_ "Prio" BO_ 1417 0;
BA_ "MessageSubnet" BO_ 1417 2;
BA_ "GenMsgCycleTime" BO_ 1417 500;
BA_ "GenMsgSendType" BO_ 1417 0;
BA_ "Prio" BO_ 407 0;
BA_ "MessageSubnet" BO_ 407 2;
BA_ "GenMsgCycleTime" BO_ 407 25;
BA_ "GenMsgSendType" BO_ 407 0;
BA_ "Prio" BO_ 189 0;
BA_ "MessageSubnet" BO_ 189 2;
BA_ "GenMsgCycleTime" BO_ 189 25;
BA_ "GenMsgSendType" BO_ 189 0;
BA_ "Prio" BO_ 187 0;
BA_ "MessageSubnet" BO_ 187 2;
BA_ "GenMsgCycleTime" BO_ 187 25;
BA_ "GenMsgSendType" BO_ 187 0;
BA_ "Prio" BO_ 185 0;
BA_ "MessageSubnet" BO_ 185 2;
BA_ "GenMsgCycleTime" BO_ 185 25;
BA_ "GenMsgSendType" BO_ 185 0;
BA_ "Prio" BO_ 186 0;
BA_ "MessageSubnet" BO_ 186 2;
BA_ "GenMsgCycleTime" BO_ 186 25;
BA_ "GenMsgSendType" BO_ 186 0;
BA_ "Prio" BO_ 152 0;
BA_ "MessageSubnet" BO_ 152 2;
BA_ "GenMsgCycleTime" BO_ 152 12;
BA_ "GenMsgSendType" BO_ 152 0;
BA_ "Prio" BO_ 151 0;
BA_ "MessageSubnet" BO_ 151 2;
BA_ "GenMsgCycleTime" BO_ 151 12;
BA_ "GenMsgSendType" BO_ 151 0;
BA_ "Prio" BO_ 150 0;
BA_ "MessageSubnet" BO_ 150 2;
BA_ "GenMsgCycleTime" BO_ 150 12;
BA_ "GenMsgSendType" BO_ 150 0;
BA_ "Prio" BO_ 188 0;
BA_ "MessageSubnet" BO_ 188 2;
BA_ "GenMsgCycleTime" BO_ 188 12;
BA_ "GenMsgSendType" BO_ 188 0;
BA_ "Prio" BO_ 170 0;
BA_ "MessageSubnet" BO_ 170 2;
BA_ "GenMsgCycleTime" BO_ 170 12;
BA_ "GenMsgSendType" BO_ 170 0;
BA_ "Prio" BO_ 1221 0;
BA_ "MessageSubnet" BO_ 1221 2;
BA_ "GenMsgCycleTime" BO_ 1221 500;
BA_ "GenMsgSendType" BO_ 1221 0;
BA_ "Prio" BO_ 1243 0;
BA_ "MessageSubnet" BO_ 1243 2;
BA_ "GenMsgCycleTime" BO_ 1243 500;
BA_ "GenMsgSendType" BO_ 1243 0;
BA_ "Prio" BO_ 979 0;
BA_ "MessageSubnet" BO_ 979 2;
BA_ "GenMsgCycleTime" BO_ 979 100;
BA_ "GenMsgSendType" BO_ 979 0;
BA_ "Prio" BO_ 546 0;
BA_ "MessageSubnet" BO_ 546 2;
BA_ "GenMsgCycleTime" BO_ 546 100;
BA_ "GenMsgSendType" BO_ 546 0;
BA_ "Prio" BO_ 530 0;
BA_ "MessageSubnet" BO_ 530 2;
BA_ "GenMsgCycleTime" BO_ 530 1000;
BA_ "GenMsgSendType" BO_ 530 0;
BA_ "Prio" BO_ 1239 0;
BA_ "MessageSubnet" BO_ 1239 2;
BA_ "GenMsgCycleTime" BO_ 1239 500;
BA_ "GenMsgSendType" BO_ 1239 0;
BA_ "Prio" BO_ 1610 0;
BA_ "MessageSubnet" BO_ 1610 2;
BA_ "DiagResponse" BO_ 1610 1;
BA_ "Prio" BO_ 1027 0;
BA_ "MessageSubnet" BO_ 1027 2;
BA_ "GenMsgCycleTime" BO_ 1027 100;
BA_ "GenMsgSendType" BO_ 1027 0;
BA_ "Prio" BO_ 1026 0;
BA_ "MessageSubnet" BO_ 1026 2;
BA_ "GenMsgCycleTime" BO_ 1026 100;
BA_ "GenMsgSendType" BO_ 1026 0;
BA_ "Prio" BO_ 1025 0;
BA_ "MessageSubnet" BO_ 1025 2;
BA_ "GenMsgCycleTime" BO_ 1025 100;
BA_ "GenMsgSendType" BO_ 1025 0;
BA_ "Prio" BO_ 1024 0;
BA_ "MessageSubnet" BO_ 1024 2;
BA_ "GenMsgCycleTime" BO_ 1024 100;
BA_ "GenMsgSendType" BO_ 1024 0;
BA_ "Prio" BO_ 508 0;
BA_ "MessageSubnet" BO_ 508 2;
BA_ "GenMsgCycleTime" BO_ 508 50;
BA_ "GenMsgSendType" BO_ 508 0;
BA_ "Prio" BO_ 422 0;
BA_ "MessageSubnet" BO_ 422 2;
BA_ "GenMsgCycleTime" BO_ 422 25;
BA_ "GenMsgSendType" BO_ 422 0;
BA_ "SignalType" SG_ 901 TrnsMtrBCoolFlwEst "UNM";
BA_ "SignalLongName" SG_ 901 TrnsMtrBCoolFlwEst "Transmission Motor B Cooling Flow Estimated";
BA_ "VNSigAllNodes" SG_ 901 TrnsMtrBCoolFlwEst 1;
BA_ "SignalType" SG_ 901 TrnsMtrACoolFlwEst "UNM";
BA_ "SignalLongName" SG_ 901 TrnsMtrACoolFlwEst "Transmission Motor A Cooling Flow Estimated";
BA_ "VNSigAllNodes" SG_ 901 TrnsMtrACoolFlwEst 1;
BA_ "SignalType" SG_ 901 TrnsLubeFlwEst "UNM";
BA_ "SignalLongName" SG_ 901 TrnsLubeFlwEst "Transmission Lube Flow Estimated";
BA_ "VNSigAllNodes" SG_ 901 TrnsLubeFlwEst 1;
BA_ "SignalType" SG_ 1032 RdTyp "ENM";
BA_ "SignalLongName" SG_ 1032 RdTyp "Road Type";
BA_ "VNSigAllNodes" SG_ 1032 RdTyp 1;
BA_ "SignalType" SG_ 1032 FwdCamSysOpStat "ENM";
BA_ "SignalLongName" SG_ 1032 FwdCamSysOpStat "Forward Camera System Operating Status";
BA_ "VNSigAllNodes" SG_ 1032 FwdCamSysOpStat 1;
BA_ "SignalType" SG_ 1032 EnvIllum "ENM";
BA_ "SignalLongName" SG_ 1032 EnvIllum "Environment Illumination";
BA_ "VNSigAllNodes" SG_ 1032 EnvIllum 1;
BA_ "SignalType" SG_ 1032 AutoHgBmSts "ENM";
BA_ "SignalLongName" SG_ 1032 AutoHgBmSts "Automatic High Beam Status";
BA_ "VNSigAllNodes" SG_ 1032 AutoHgBmSts 1;
BA_ "SignalType" SG_ 1031 FCO8D_ObjVertVar "SNM";
BA_ "PacketOrder" SG_ 1031 FCO8D_ObjVertVar 8;
BA_ "SignalLongName" SG_ 1031 FCO8D_ObjVertVar "Forward Camera Object 8 Detected : Object Vertical Variance";
BA_ "VNSigAllNodes" SG_ 1031 FCO8D_ObjVertVar 1;
BA_ "SignalType" SG_ 1031 FCO8D_ObjVertPos "SNM";
BA_ "PacketOrder" SG_ 1031 FCO8D_ObjVertPos 7;
BA_ "SignalLongName" SG_ 1031 FCO8D_ObjVertPos "Forward Camera Object 8 Detected : Object Vertical Position";
BA_ "VNSigAllNodes" SG_ 1031 FCO8D_ObjVertPos 1;
BA_ "SignalType" SG_ 1031 FCO8D_ObjTyp "ENM";
BA_ "PacketOrder" SG_ 1031 FCO8D_ObjTyp 3;
BA_ "SignalLongName" SG_ 1031 FCO8D_ObjTyp "Forward Camera Object 8 Detected : Object Type";
BA_ "VNSigAllNodes" SG_ 1031 FCO8D_ObjTyp 1;
BA_ "PacketOrder" SG_ 1031 FCO8D_ObjQlty 1;
BA_ "SignalType" SG_ 1031 FCO8D_ObjQlty "ENM";
BA_ "SignalLongName" SG_ 1031 FCO8D_ObjQlty "Forward Camera Object 8 Detected : Object Quality";
BA_ "VNSigAllNodes" SG_ 1031 FCO8D_ObjQlty 1;
BA_ "SignalType" SG_ 1031 FCO8D_ObjId "UNM";
BA_ "PacketOrder" SG_ 1031 FCO8D_ObjId 2;
BA_ "SignalLongName" SG_ 1031 FCO8D_ObjId "Forward Camera Object 8 Detected : Object ID";
BA_ "VNSigAllNodes" SG_ 1031 FCO8D_ObjId 1;
BA_ "SignalType" SG_ 1031 FCO8D_ObjHorzPos "SNM";
BA_ "PacketOrder" SG_ 1031 FCO8D_ObjHorzPos 4;
BA_ "SignalLongName" SG_ 1031 FCO8D_ObjHorzPos "Forward Camera Object 8 Detected : Object Horizontal Position";
BA_ "VNSigAllNodes" SG_ 1031 FCO8D_ObjHorzPos 1;
BA_ "SignalType" SG_ 1031 FCO8D_ObjHorzDim "UNM";
BA_ "PacketOrder" SG_ 1031 FCO8D_ObjHorzDim 6;
BA_ "SignalLongName" SG_ 1031 FCO8D_ObjHorzDim "Forward Camera Object 8 Detected : Object Horizontal Dimension";
BA_ "VNSigAllNodes" SG_ 1031 FCO8D_ObjHorzDim 1;
BA_ "SignalType" SG_ 1031 FCO8D_ObjDist "UNM";
BA_ "PacketOrder" SG_ 1031 FCO8D_ObjDist 9;
BA_ "SignalLongName" SG_ 1031 FCO8D_ObjDist "Forward Camera Object 8 Detected : Object Distance";
BA_ "VNSigAllNodes" SG_ 1031 FCO8D_ObjDist 1;
BA_ "SignalType" SG_ 1031 FCO8D_DetMthd "ENM";
BA_ "PacketOrder" SG_ 1031 FCO8D_DetMthd 5;
BA_ "SignalLongName" SG_ 1031 FCO8D_DetMthd "Forward Camera Object 8 Detected : Detection Method";
BA_ "VNSigAllNodes" SG_ 1031 FCO8D_DetMthd 1;
BA_ "SignalType" SG_ 1030 FCO7D_ObjVertVar "SNM";
BA_ "PacketOrder" SG_ 1030 FCO7D_ObjVertVar 8;
BA_ "SignalLongName" SG_ 1030 FCO7D_ObjVertVar "Forward Camera Object 7 Detected : Object Vertical Variance";
BA_ "VNSigAllNodes" SG_ 1030 FCO7D_ObjVertVar 1;
BA_ "SignalType" SG_ 1030 FCO7D_ObjVertPos "SNM";
BA_ "PacketOrder" SG_ 1030 FCO7D_ObjVertPos 7;
BA_ "SignalLongName" SG_ 1030 FCO7D_ObjVertPos "Forward Camera Object 7 Detected : Object Vertical Position";
BA_ "VNSigAllNodes" SG_ 1030 FCO7D_ObjVertPos 1;
BA_ "SignalType" SG_ 1030 FCO7D_ObjTyp "ENM";
BA_ "PacketOrder" SG_ 1030 FCO7D_ObjTyp 3;
BA_ "SignalLongName" SG_ 1030 FCO7D_ObjTyp "Forward Camera Object 7 Detected : Object Type";
BA_ "VNSigAllNodes" SG_ 1030 FCO7D_ObjTyp 1;
BA_ "PacketOrder" SG_ 1030 FCO7D_ObjQlty 1;
BA_ "SignalType" SG_ 1030 FCO7D_ObjQlty "ENM";
BA_ "SignalLongName" SG_ 1030 FCO7D_ObjQlty "Forward Camera Object 7 Detected : Object Quality";
BA_ "VNSigAllNodes" SG_ 1030 FCO7D_ObjQlty 1;
BA_ "SignalType" SG_ 1030 FCO7D_ObjId "UNM";
BA_ "PacketOrder" SG_ 1030 FCO7D_ObjId 2;
BA_ "SignalLongName" SG_ 1030 FCO7D_ObjId "Forward Camera Object 7 Detected : Object ID";
BA_ "VNSigAllNodes" SG_ 1030 FCO7D_ObjId 1;
BA_ "SignalType" SG_ 1030 FCO7D_ObjHorzPos "SNM";
BA_ "PacketOrder" SG_ 1030 FCO7D_ObjHorzPos 4;
BA_ "SignalLongName" SG_ 1030 FCO7D_ObjHorzPos "Forward Camera Object 7 Detected : Object Horizontal Position";
BA_ "VNSigAllNodes" SG_ 1030 FCO7D_ObjHorzPos 1;
BA_ "SignalType" SG_ 1030 FCO7D_ObjHorzDim "UNM";
BA_ "PacketOrder" SG_ 1030 FCO7D_ObjHorzDim 6;
BA_ "SignalLongName" SG_ 1030 FCO7D_ObjHorzDim "Forward Camera Object 7 Detected : Object Horizontal Dimension";
BA_ "VNSigAllNodes" SG_ 1030 FCO7D_ObjHorzDim 1;
BA_ "SignalType" SG_ 1030 FCO7D_ObjDist "UNM";
BA_ "PacketOrder" SG_ 1030 FCO7D_ObjDist 9;
BA_ "SignalLongName" SG_ 1030 FCO7D_ObjDist "Forward Camera Object 7 Detected : Object Distance";
BA_ "VNSigAllNodes" SG_ 1030 FCO7D_ObjDist 1;
BA_ "SignalType" SG_ 1030 FCO7D_DetMthd "ENM";
BA_ "PacketOrder" SG_ 1030 FCO7D_DetMthd 5;
BA_ "SignalLongName" SG_ 1030 FCO7D_DetMthd "Forward Camera Object 7 Detected : Detection Method";
BA_ "VNSigAllNodes" SG_ 1030 FCO7D_DetMthd 1;
BA_ "SignalType" SG_ 479 ASIRI_Indication16 "BLN";
BA_ "PacketOrder" SG_ 479 ASIRI_Indication16 16;
BA_ "SignalLongName" SG_ 479 ASIRI_Indication16 "Auto Stop Inhibit Reason Indication : Indication 16";
BA_ "VNSigAllNodes" SG_ 479 ASIRI_Indication16 1;
BA_ "SignalType" SG_ 479 ASIRI_Indication15 "BLN";
BA_ "PacketOrder" SG_ 479 ASIRI_Indication15 15;
BA_ "SignalLongName" SG_ 479 ASIRI_Indication15 "Auto Stop Inhibit Reason Indication : Indication 15";
BA_ "VNSigAllNodes" SG_ 479 ASIRI_Indication15 1;
BA_ "SignalType" SG_ 479 ASIRI_Indication14 "BLN";
BA_ "PacketOrder" SG_ 479 ASIRI_Indication14 14;
BA_ "SignalLongName" SG_ 479 ASIRI_Indication14 "Auto Stop Inhibit Reason Indication : Indication 14";
BA_ "VNSigAllNodes" SG_ 479 ASIRI_Indication14 1;
BA_ "SignalType" SG_ 479 ASIRI_Indication13 "BLN";
BA_ "PacketOrder" SG_ 479 ASIRI_Indication13 13;
BA_ "SignalLongName" SG_ 479 ASIRI_Indication13 "Auto Stop Inhibit Reason Indication : Indication 13";
BA_ "VNSigAllNodes" SG_ 479 ASIRI_Indication13 1;
BA_ "SignalType" SG_ 479 ASIRI_Indication12 "BLN";
BA_ "PacketOrder" SG_ 479 ASIRI_Indication12 12;
BA_ "SignalLongName" SG_ 479 ASIRI_Indication12 "Auto Stop Inhibit Reason Indication : Indication 12";
BA_ "VNSigAllNodes" SG_ 479 ASIRI_Indication12 1;
BA_ "SignalType" SG_ 479 ASIRI_Indication11 "BLN";
BA_ "PacketOrder" SG_ 479 ASIRI_Indication11 11;
BA_ "SignalLongName" SG_ 479 ASIRI_Indication11 "Auto Stop Inhibit Reason Indication : Indication 11";
BA_ "VNSigAllNodes" SG_ 479 ASIRI_Indication11 1;
BA_ "SignalType" SG_ 479 ASIRI_Indication10 "BLN";
BA_ "PacketOrder" SG_ 479 ASIRI_Indication10 10;
BA_ "SignalLongName" SG_ 479 ASIRI_Indication10 "Auto Stop Inhibit Reason Indication : Indication 10";
BA_ "VNSigAllNodes" SG_ 479 ASIRI_Indication10 1;
BA_ "SignalType" SG_ 479 ASIRI_Indication09 "BLN";
BA_ "PacketOrder" SG_ 479 ASIRI_Indication09 9;
BA_ "SignalLongName" SG_ 479 ASIRI_Indication09 "Auto Stop Inhibit Reason Indication : Indication 9";
BA_ "VNSigAllNodes" SG_ 479 ASIRI_Indication09 1;
BA_ "SignalType" SG_ 479 ASIRI_Indication08 "BLN";
BA_ "PacketOrder" SG_ 479 ASIRI_Indication08 8;
BA_ "SignalLongName" SG_ 479 ASIRI_Indication08 "Auto Stop Inhibit Reason Indication : Indication 8";
BA_ "VNSigAllNodes" SG_ 479 ASIRI_Indication08 1;
BA_ "SignalType" SG_ 479 ASIRI_Indication07 "BLN";
BA_ "PacketOrder" SG_ 479 ASIRI_Indication07 7;
BA_ "SignalLongName" SG_ 479 ASIRI_Indication07 "Auto Stop Inhibit Reason Indication : Indication 7";
BA_ "VNSigAllNodes" SG_ 479 ASIRI_Indication07 1;
BA_ "SignalType" SG_ 479 ASIRI_Indication06 "BLN";
BA_ "SignalLongName" SG_ 479 ASIRI_Indication06 "Auto Stop Inhibit Reason Indication : Indication 6";
BA_ "VNSigAllNodes" SG_ 479 ASIRI_Indication06 1;
BA_ "SignalType" SG_ 479 ASIRI_Indication05 "BLN";
BA_ "PacketOrder" SG_ 479 ASIRI_Indication05 5;
BA_ "SignalLongName" SG_ 479 ASIRI_Indication05 "Auto Stop Inhibit Reason Indication : Indication 5";
BA_ "VNSigAllNodes" SG_ 479 ASIRI_Indication05 1;
BA_ "SignalType" SG_ 479 ASIRI_Indication04 "BLN";
BA_ "PacketOrder" SG_ 479 ASIRI_Indication04 4;
BA_ "SignalLongName" SG_ 479 ASIRI_Indication04 "Auto Stop Inhibit Reason Indication : Indication 4";
BA_ "VNSigAllNodes" SG_ 479 ASIRI_Indication04 1;
BA_ "SignalType" SG_ 479 ASIRI_Indication03 "BLN";
BA_ "PacketOrder" SG_ 479 ASIRI_Indication03 3;
BA_ "SignalLongName" SG_ 479 ASIRI_Indication03 "Auto Stop Inhibit Reason Indication : Indication 3";
BA_ "VNSigAllNodes" SG_ 479 ASIRI_Indication03 1;
BA_ "SignalType" SG_ 479 ASIRI_Indication02 "BLN";
BA_ "PacketOrder" SG_ 479 ASIRI_Indication02 2;
BA_ "SignalLongName" SG_ 479 ASIRI_Indication02 "Auto Stop Inhibit Reason Indication : Indication 2";
BA_ "VNSigAllNodes" SG_ 479 ASIRI_Indication02 1;
BA_ "SignalType" SG_ 479 ASIRI_Indication01 "BLN";
BA_ "PacketOrder" SG_ 479 ASIRI_Indication01 1;
BA_ "SignalLongName" SG_ 479 ASIRI_Indication01 "Auto Stop Inhibit Reason Indication : Indication 1";
BA_ "VNSigAllNodes" SG_ 479 ASIRI_Indication01 1;
BA_ "SignalType" SG_ 479 PTWrmgWtToShftIO "BLN";
BA_ "SignalLongName" SG_ 479 PTWrmgWtToShftIO "Powertrain Warming Wait To Shift Indication On";
BA_ "VNSigAllNodes" SG_ 479 PTWrmgWtToShftIO 1;
BA_ "SignalType" SG_ 479 PrplsnSysAtv "BLN";
BA_ "SignalLongName" SG_ 479 PrplsnSysAtv "Propulsion System Active";
BA_ "VNSigAllNodes" SG_ 479 PrplsnSysAtv 1;
BA_ "SignalType" SG_ 479 PTShftLvrLckRqd "BLN";
BA_ "SignalLongName" SG_ 479 PTShftLvrLckRqd "Powertrain Shift Lever Lock Requested";
BA_ "VNSigAllNodes" SG_ 479 PTShftLvrLckRqd 1;
BA_ "SignalType" SG_ 211 ActAxleTrqV "ENM";
BA_ "SignalLongName" SG_ 211 ActAxleTrqV "Actual Axle Torque Validity";
BA_ "VNSigAllNodes" SG_ 211 ActAxleTrqV 1;
BA_ "SignalType" SG_ 211 ActAxleTrq "UNM";
BA_ "SignalLongName" SG_ 211 ActAxleTrq "Actual Axle Torque";
BA_ "VNSigAllNodes" SG_ 211 ActAxleTrq 1;
BA_ "SignalType" SG_ 1020 OtsAirTmpEmsnsRelV "ENM";
BA_ "SignalLongName" SG_ 1020 OtsAirTmpEmsnsRelV "Outside Air Temperature Emissions Related Validity";
BA_ "VNSigAllNodes" SG_ 1020 OtsAirTmpEmsnsRelV 1;
BA_ "SignalType" SG_ 1020 OtsAirTmpEmsnsRel "UNM";
BA_ "SignalLongName" SG_ 1020 OtsAirTmpEmsnsRel "Outside Air Temperature Emissions Related";
BA_ "VNSigAllNodes" SG_ 1020 OtsAirTmpEmsnsRel 1;
BA_ "SignalType" SG_ 1020 OATEmsnsRelCrValV "ENM";
BA_ "SignalLongName" SG_ 1020 OATEmsnsRelCrValV "Outside Air Temperature Emissions Related Corrected Value Validity";
BA_ "VNSigAllNodes" SG_ 1020 OATEmsnsRelCrValV 1;
BA_ "SignalType" SG_ 1020 OATEmsnsRelCrValM "ENM";
BA_ "SignalLongName" SG_ 1020 OATEmsnsRelCrValM "Outside Air Temperature Emissions Related Corrected Value Mask";
BA_ "VNSigAllNodes" SG_ 1020 OATEmsnsRelCrValM 1;
BA_ "SignalType" SG_ 1020 OATEmsnsRelCrVal "UNM";
BA_ "SignalLongName" SG_ 1020 OATEmsnsRelCrVal "Outside Air Temperature Emissions Related Corrected Value";
BA_ "VNSigAllNodes" SG_ 1020 OATEmsnsRelCrVal 1;
BA_ "SignalType" SG_ 1020 CatlystOutGasTempEstV "ENM";
BA_ "SignalLongName" SG_ 1020 CatlystOutGasTempEstV "Catalyst Outlet Gas Temperature Estimate Validity";
BA_ "VNSigAllNodes" SG_ 1020 CatlystOutGasTempEstV 1;
BA_ "SignalType" SG_ 1020 CatlystOutGasTempEst "UNM";
BA_ "SignalLongName" SG_ 1020 CatlystOutGasTempEst "Catalyst Outlet Gas Temperature Estimate";
BA_ "VNSigAllNodes" SG_ 1020 CatlystOutGasTempEst 1;
BA_ "SignalType" SG_ 1020 OtsAirTmpCrValMsk "ENM";
BA_ "SignalLongName" SG_ 1020 OtsAirTmpCrValMsk "Outside Air Temperature Corrected Value Mask";
BA_ "VNSigAllNodes" SG_ 1020 OtsAirTmpCrValMsk 1;
BA_ "SignalType" SG_ 1020 OtsAirTmpV "ENM";
BA_ "SignalLongName" SG_ 1020 OtsAirTmpV "Outside Air Temperature Validity";
BA_ "VNSigAllNodes" SG_ 1020 OtsAirTmpV 1;
BA_ "SignalType" SG_ 1020 OtsAirTmpCrValV "ENM";
BA_ "SignalLongName" SG_ 1020 OtsAirTmpCrValV "Outside Air Temperature Corrected Value Validity";
BA_ "VNSigAllNodes" SG_ 1020 OtsAirTmpCrValV 1;
BA_ "SignalType" SG_ 1020 OtsAirTmpCrVal "UNM";
BA_ "SignalLongName" SG_ 1020 OtsAirTmpCrVal "Outside Air Temperature Corrected Value";
BA_ "VNSigAllNodes" SG_ 1020 OtsAirTmpCrVal 1;
BA_ "SignalType" SG_ 1020 OtsAirTmp "UNM";
BA_ "SignalLongName" SG_ 1020 OtsAirTmp "Outside Air Temperature";
BA_ "VNSigAllNodes" SG_ 1020 OtsAirTmp 1;
BA_ "SignalType" SG_ 1020 EngInltSpcfcHmdtyV "ENM";
BA_ "SignalLongName" SG_ 1020 EngInltSpcfcHmdtyV "Engine Inlet Specific Humidity Validity";
BA_ "VNSigAllNodes" SG_ 1020 EngInltSpcfcHmdtyV 1;
BA_ "SignalType" SG_ 1020 EngInltSpcfcHmdtyM "ENM";
BA_ "SignalLongName" SG_ 1020 EngInltSpcfcHmdtyM "Engine Inlet Specific Humidity Mask";
BA_ "VNSigAllNodes" SG_ 1020 EngInltSpcfcHmdtyM 1;
BA_ "SignalType" SG_ 1020 EngInltSpcfcHmdty "UNM";
BA_ "SignalLongName" SG_ 1020 EngInltSpcfcHmdty "Engine Inlet Specific Humidity";
BA_ "VNSigAllNodes" SG_ 1020 EngInltSpcfcHmdty 1;
BA_ "SignalType" SG_ 1219 DslExhFldDiagWrnIdRq "ENM";
BA_ "SignalLongName" SG_ 1219 DslExhFldDiagWrnIdRq "Diesel Exhaust Fluid System Diagnostic Warning Indication Request";
BA_ "VNSigAllNodes" SG_ 1219 DslExhFldDiagWrnIdRq 1;
BA_ "SignalType" SG_ 1219 DslEmnsOBDMrkt "ENM";
BA_ "SignalLongName" SG_ 1219 DslEmnsOBDMrkt "Diesel Emissions OBD Market";
BA_ "VNSigAllNodes" SG_ 1219 DslEmnsOBDMrkt 1;
BA_ "SignalType" SG_ 1219 DslExNxEmWrngIndRq "ENM";
BA_ "SignalLongName" SG_ 1219 DslExNxEmWrngIndRq "Diesel Exhaust NOx Emissions Too High Warning Indication Request";
BA_ "VNSigAllNodes" SG_ 1219 DslExNxEmWrngIndRq 1;
BA_ "SignalType" SG_ 1219 DEFWVSL_S3SpdLmt "UNM";
BA_ "PacketOrder" SG_ 1219 DEFWVSL_S3SpdLmt 3;
BA_ "SignalLongName" SG_ 1219 DEFWVSL_S3SpdLmt "Diesel Exhaust Fluid Warning Vehicle Speed Limit : Stage 3 Vehicle Speed Limit";
BA_ "VNSigAllNodes" SG_ 1219 DEFWVSL_S3SpdLmt 1;
BA_ "SignalType" SG_ 1219 DEFWVSL_S2SpdLmt "UNM";
BA_ "PacketOrder" SG_ 1219 DEFWVSL_S2SpdLmt 2;
BA_ "SignalLongName" SG_ 1219 DEFWVSL_S2SpdLmt "Diesel Exhaust Fluid Warning Vehicle Speed Limit : Stage 2 Vehicle Speed Limit";
BA_ "VNSigAllNodes" SG_ 1219 DEFWVSL_S2SpdLmt 1;
BA_ "SignalType" SG_ 1219 DEFWVSL_S1SpdLmt "UNM";
BA_ "PacketOrder" SG_ 1219 DEFWVSL_S1SpdLmt 1;
BA_ "SignalLongName" SG_ 1219 DEFWVSL_S1SpdLmt "Diesel Exhaust Fluid Warning Vehicle Speed Limit : Stage 1 Vehicle Speed Limit";
BA_ "VNSigAllNodes" SG_ 1219 DEFWVSL_S1SpdLmt 1;
BA_ "SignalType" SG_ 1219 DslExFldTpWrngIndRq "ENM";
BA_ "SignalLongName" SG_ 1219 DslExFldTpWrngIndRq "Diesel Exhaust Fluid Tampering Warning Indication Request";
BA_ "VNSigAllNodes" SG_ 1219 DslExFldTpWrngIndRq 1;
BA_ "SignalType" SG_ 1219 DslExhFldQlyWrngIReq "ENM";
BA_ "SignalLongName" SG_ 1219 DslExhFldQlyWrngIReq "Diesel Exhaust Fluid Quality Warning Indication Request";
BA_ "VNSigAllNodes" SG_ 1219 DslExhFldQlyWrngIReq 1;
BA_ "SignalType" SG_ 1219 DslExhFldWrngIdRqER "ENM";
BA_ "SignalLongName" SG_ 1219 DslExhFldWrngIdRqER "Diesel Exhaust Fluid Level Warning Indication Request Extended Range";
BA_ "VNSigAllNodes" SG_ 1219 DslExhFldWrngIdRqER 1;
BA_ "SignalType" SG_ 1219 DslExFldCnWrngIndRq "ENM";
BA_ "SignalLongName" SG_ 1219 DslExFldCnWrngIndRq "Diesel Exhaust Fluid Consumption Monitoring Warning Indication Request";
BA_ "VNSigAllNodes" SG_ 1219 DslExFldCnWrngIndRq 1;
BA_ "SignalType" SG_ 372 ARSFlrIO "BLN";
BA_ "SignalLongName" SG_ 372 ARSFlrIO "Active Rear Steer Failure Indication On";
BA_ "VNSigAllNodes" SG_ 372 ARSFlrIO 1;
BA_ "SignalType" SG_ 528 BrkSysAutBrkReqRC "UNM";
BA_ "SignalLongName" SG_ 528 BrkSysAutBrkReqRC "Brake System Autonomous Braking Request Rolling Count";
BA_ "VNSigAllNodes" SG_ 528 BrkSysAutBrkReqRC 1;
BA_ "SignalType" SG_ 528 BrkSysAutBrkReqPVal "UNM";
BA_ "SignalLongName" SG_ 528 BrkSysAutBrkReqPVal "Brake System Autonomous Braking Request Protection Value";
BA_ "VNSigAllNodes" SG_ 528 BrkSysAutBrkReqPVal 1;
BA_ "PacketOrder" SG_ 528 BSABR_TrlBrkRq 2;
BA_ "SignalType" SG_ 528 BSABR_TrlBrkRq "UNM";
BA_ "SignalLongName" SG_ 528 BSABR_TrlBrkRq "Brake System Autonomous Braking Request : Trailer Brake Request";
BA_ "VNSigAllNodes" SG_ 528 BSABR_TrlBrkRq 1;
BA_ "SignalType" SG_ 528 BSABR_TrlBrkCntlIntRq "BLN";
BA_ "SignalLongName" SG_ 528 BSABR_TrlBrkCntlIntRq "Brake System Autonomous Braking Request : Trailer Brake Control Interactive Request";
BA_ "VNSigAllNodes" SG_ 528 BSABR_TrlBrkCntlIntRq 1;
BA_ "SignalType" SG_ 552 ThrmlRefCmpIGBTTmpV "ENM";
BA_ "SignalLongName" SG_ 552 ThrmlRefCmpIGBTTmpV "Thermal Refrigerant Compressor Insulated Gate Bipolar Transistor Temperature Validity";
BA_ "VNSigAllNodes" SG_ 552 ThrmlRefCmpIGBTTmpV 1;
BA_ "SignalType" SG_ 552 ThrmlRefCmpIGBTTmp "UNM";
BA_ "SignalLongName" SG_ 552 ThrmlRefCmpIGBTTmp "Thermal Refrigerant Compressor Insulated Gate Bipolar Transistor Temperature";
BA_ "VNSigAllNodes" SG_ 552 ThrmlRefCmpIGBTTmp 1;
BA_ "SignalType" SG_ 552 ThrmlRefCmpHiVltgInptV "ENM";
BA_ "SignalLongName" SG_ 552 ThrmlRefCmpHiVltgInptV "Thermal Refrigerant Compressor High Voltage Input Validity";
BA_ "VNSigAllNodes" SG_ 552 ThrmlRefCmpHiVltgInptV 1;
BA_ "SignalType" SG_ 552 ThrmlRefCmpHiVltgInpt "UNM";
BA_ "SignalLongName" SG_ 552 ThrmlRefCmpHiVltgInpt "Thermal Refrigerant Compressor High Voltage Input";
BA_ "VNSigAllNodes" SG_ 552 ThrmlRefCmpHiVltgInpt 1;
BA_ "SignalType" SG_ 552 ThrmlRefCmpCPUHtSkTmpV "ENM";
BA_ "SignalLongName" SG_ 552 ThrmlRefCmpCPUHtSkTmpV "Thermal Refrigerant Compressor Central Processing Unit Heat Sink Temperature Validity";
BA_ "VNSigAllNodes" SG_ 552 ThrmlRefCmpCPUHtSkTmpV 1;
BA_ "SignalType" SG_ 552 ThrmlRefCmpCPUHtSkTmp "UNM";
BA_ "SignalLongName" SG_ 552 ThrmlRefCmpCPUHtSkTmp "Thermal Refrigerant Compressor Central Processing Unit Heat Sink Temperature";
BA_ "VNSigAllNodes" SG_ 552 ThrmlRefCmpCPUHtSkTmp 1;
BA_ "SignalType" SG_ 442 CrksftTqMinImCapV "ENM";
BA_ "SignalLongName" SG_ 442 CrksftTqMinImCapV "Crankshaft Torque Minimum Immediate Capacity Validity";
BA_ "VNSigAllNodes" SG_ 442 CrksftTqMinImCapV 1;
BA_ "SignalType" SG_ 442 CrksftTqMinImCap "UNM";
BA_ "SignalLongName" SG_ 442 CrksftTqMinImCap "Crankshaft Torque Minimum Immediate Capacity";
BA_ "VNSigAllNodes" SG_ 442 CrksftTqMinImCap 1;
BA_ "SignalType" SG_ 442 DrvIntndCrksftTrqRw "UNM";
BA_ "SignalLongName" SG_ 442 DrvIntndCrksftTrqRw "Driver Intended Crankshaft Torque Raw";
BA_ "VNSigAllNodes" SG_ 442 DrvIntndCrksftTrqRw 1;
BA_ "SignalType" SG_ 442 DrvIntndCrksftTrqMin "UNM";
BA_ "SignalLongName" SG_ 442 DrvIntndCrksftTrqMin "Driver Intended Crankshaft Torque Minimum";
BA_ "VNSigAllNodes" SG_ 442 DrvIntndCrksftTrqMin 1;
BA_ "SignalType" SG_ 442 DrvIntndCrksftTrq "UNM";
BA_ "SignalLongName" SG_ 442 DrvIntndCrksftTrq "Driver Intended Crankshaft Torque";
BA_ "VNSigAllNodes" SG_ 442 DrvIntndCrksftTrq 1;
BA_ "SignalType" SG_ 442 CrksftMaxTrqLmtV "ENM";
BA_ "SignalLongName" SG_ 442 CrksftMaxTrqLmtV "Crankshaft Maximum Torque Limit Validity";
BA_ "VNSigAllNodes" SG_ 442 CrksftMaxTrqLmtV 1;
BA_ "SignalType" SG_ 442 CrksftMaxTrqLmt "UNM";
BA_ "SignalLongName" SG_ 442 CrksftMaxTrqLmt "Crankshaft Maximum Torque Limit";
BA_ "VNSigAllNodes" SG_ 442 CrksftMaxTrqLmt 1;
BA_ "SignalType" SG_ 753 EBCMDS5_DTCStatus "ENM";
BA_ "SignalLongName" SG_ 753 EBCMDS5_DTCStatus "Electronic Brake Control Module Diagnostic Status 5 : Diagnostic Trouble Code Status";
BA_ "VNSigAllNodes" SG_ 753 EBCMDS5_DTCStatus 1;
BA_ "SignalType" SG_ 753 EBCMDS5_DTCIndex "UNM";
BA_ "PacketOrder" SG_ 753 EBCMDS5_DTCIndex 2;
BA_ "SignalLongName" SG_ 753 EBCMDS5_DTCIndex "Electronic Brake Control Module Diagnostic Status 5 : Diagnostic Trouble Code Index";
BA_ "VNSigAllNodes" SG_ 753 EBCMDS5_DTCIndex 1;
BA_ "PacketOrder" SG_ 753 EBCMDS4_DTCStatus 1;
BA_ "SignalType" SG_ 753 EBCMDS4_DTCStatus "ENM";
BA_ "SignalLongName" SG_ 753 EBCMDS4_DTCStatus "Electronic Brake Control Module Diagnostic Status 4 : Diagnostic Trouble Code Status";
BA_ "VNSigAllNodes" SG_ 753 EBCMDS4_DTCStatus 1;
BA_ "SignalType" SG_ 753 EBCMDS4_DTCIndex "UNM";
BA_ "PacketOrder" SG_ 753 EBCMDS4_DTCIndex 2;
BA_ "SignalLongName" SG_ 753 EBCMDS4_DTCIndex "Electronic Brake Control Module Diagnostic Status 4 : Diagnostic Trouble Code Index";
BA_ "VNSigAllNodes" SG_ 753 EBCMDS4_DTCIndex 1;
BA_ "PacketOrder" SG_ 753 EBCMDS3_DTCStatus 1;
BA_ "SignalType" SG_ 753 EBCMDS3_DTCStatus "ENM";
BA_ "SignalLongName" SG_ 753 EBCMDS3_DTCStatus "Electronic Brake Control Module Diagnostic Status 3 : Diagnostic Trouble Code Status";
BA_ "VNSigAllNodes" SG_ 753 EBCMDS3_DTCStatus 1;
BA_ "SignalType" SG_ 753 EBCMDS3_DTCIndex "UNM";
BA_ "PacketOrder" SG_ 753 EBCMDS3_DTCIndex 2;
BA_ "SignalLongName" SG_ 753 EBCMDS3_DTCIndex "Electronic Brake Control Module Diagnostic Status 3 : Diagnostic Trouble Code Index";
BA_ "VNSigAllNodes" SG_ 753 EBCMDS3_DTCIndex 1;
BA_ "PacketOrder" SG_ 753 EBCMDS2_DTCStatus 1;
BA_ "SignalType" SG_ 753 EBCMDS2_DTCStatus "ENM";
BA_ "SignalLongName" SG_ 753 EBCMDS2_DTCStatus "Electronic Brake Control Module Diagnostic Status 2 : Diagnostic Trouble Code Status";
BA_ "VNSigAllNodes" SG_ 753 EBCMDS2_DTCStatus 1;
BA_ "SignalType" SG_ 753 EBCMDS2_DTCIndex "UNM";
BA_ "PacketOrder" SG_ 753 EBCMDS2_DTCIndex 2;
BA_ "SignalLongName" SG_ 753 EBCMDS2_DTCIndex "Electronic Brake Control Module Diagnostic Status 2 : Diagnostic Trouble Code Index";
BA_ "VNSigAllNodes" SG_ 753 EBCMDS2_DTCIndex 1;
BA_ "PacketOrder" SG_ 753 EBCMDS1_DTCStatus 1;
BA_ "SignalType" SG_ 753 EBCMDS1_DTCStatus "ENM";
BA_ "SignalLongName" SG_ 753 EBCMDS1_DTCStatus "Electronic Brake Control Module Diagnostic Status 1 : Diagnostic Trouble Code Status";
BA_ "VNSigAllNodes" SG_ 753 EBCMDS1_DTCStatus 1;
BA_ "SignalType" SG_ 753 EBCMDS1_DTCIndex "UNM";
BA_ "PacketOrder" SG_ 753 EBCMDS1_DTCIndex 2;
BA_ "SignalLongName" SG_ 753 EBCMDS1_DTCIndex "Electronic Brake Control Module Diagnostic Status 1 : Diagnostic Trouble Code Index";
BA_ "VNSigAllNodes" SG_ 753 EBCMDS1_DTCIndex 1;
BA_ "SignalType" SG_ 989 RdHVCntctrShdwnReq "ENM";
BA_ "SignalLongName" SG_ 989 RdHVCntctrShdwnReq "Redundant High Voltage Contactor Shutdown Request";
BA_ "VNSigAllNodes" SG_ 989 RdHVCntctrShdwnReq 1;
BA_ "SignalType" SG_ 989 AuxClntHtrVlvStat "ENM";
BA_ "SignalLongName" SG_ 989 AuxClntHtrVlvStat "Auxiliary Coolant Heater Valve Status";
BA_ "VNSigAllNodes" SG_ 989 AuxClntHtrVlvStat 1;
BA_ "SignalType" SG_ 989 EngCoolFanOpEnbl "BLN";
BA_ "SignalLongName" SG_ 989 EngCoolFanOpEnbl "Engine Cooling Fan Operation Enable";
BA_ "VNSigAllNodes" SG_ 989 EngCoolFanOpEnbl 1;
BA_ "SignalType" SG_ 989 DiagFreeRunCntrV "ENM";
BA_ "SignalLongName" SG_ 989 DiagFreeRunCntrV "Diagnostic Free Running Counter Validity";
BA_ "VNSigAllNodes" SG_ 989 DiagFreeRunCntrV 1;
BA_ "SignalType" SG_ 989 DiagFreeRunCntr "UNM";
BA_ "SignalLongName" SG_ 989 DiagFreeRunCntr "Diagnostic Free Running Counter";
BA_ "VNSigAllNodes" SG_ 989 DiagFreeRunCntr 1;
BA_ "SignalType" SG_ 989 HybFanSpdRq "UNM";
BA_ "SignalLongName" SG_ 989 HybFanSpdRq "Hybrid Fan Speed Percent Request";
BA_ "VNSigAllNodes" SG_ 989 HybFanSpdRq 1;
BA_ "SignalType" SG_ 989 MntnceMdStEngRq "BLN";
BA_ "SignalLongName" SG_ 989 MntnceMdStEngRq "Maintenance Mode Start Engine Request";
BA_ "VNSigAllNodes" SG_ 989 MntnceMdStEngRq 1;
BA_ "SignalType" SG_ 989 RdHVCntctrCmdStat "ENM";
BA_ "SignalLongName" SG_ 989 RdHVCntctrCmdStat "Redundant High Voltage Contactor Command Status";
BA_ "VNSigAllNodes" SG_ 989 RdHVCntctrCmdStat 1;
BA_ "SignalType" SG_ 550 ACCMCII_DtBtG "ASC";
BA_ "PacketOrder" SG_ 550 ACCMCII_DtBtG 10;
BA_ "SignalLongName" SG_ 550 ACCMCII_DtBtG "Air Compressor Control Module Calibration Identification : Data Byte G";
BA_ "VNSigAllNodes" SG_ 550 ACCMCII_DtBtG 1;
BA_ "SignalType" SG_ 550 ACCMCII_DtBtF "ASC";
BA_ "PacketOrder" SG_ 550 ACCMCII_DtBtF 9;
BA_ "SignalLongName" SG_ 550 ACCMCII_DtBtF "Air Compressor Control Module Calibration Identification : Data Byte F";
BA_ "VNSigAllNodes" SG_ 550 ACCMCII_DtBtF 1;
BA_ "SignalType" SG_ 550 ACCMCII_DtBtE "ASC";
BA_ "PacketOrder" SG_ 550 ACCMCII_DtBtE 8;
BA_ "SignalLongName" SG_ 550 ACCMCII_DtBtE "Air Compressor Control Module Calibration Identification : Data Byte E";
BA_ "VNSigAllNodes" SG_ 550 ACCMCII_DtBtE 1;
BA_ "SignalType" SG_ 550 ACCMCII_DtBtD "ASC";
BA_ "PacketOrder" SG_ 550 ACCMCII_DtBtD 7;
BA_ "SignalLongName" SG_ 550 ACCMCII_DtBtD "Air Compressor Control Module Calibration Identification : Data Byte D";
BA_ "VNSigAllNodes" SG_ 550 ACCMCII_DtBtD 1;
BA_ "SignalType" SG_ 550 ACCMCII_DtBtC "ASC";
BA_ "SignalLongName" SG_ 550 ACCMCII_DtBtC "Air Compressor Control Module Calibration Identification : Data Byte C";
BA_ "VNSigAllNodes" SG_ 550 ACCMCII_DtBtC 1;
BA_ "SignalType" SG_ 550 ACCMCII_DtBtB "ASC";
BA_ "PacketOrder" SG_ 550 ACCMCII_DtBtB 5;
BA_ "SignalLongName" SG_ 550 ACCMCII_DtBtB "Air Compressor Control Module Calibration Identification : Data Byte B";
BA_ "VNSigAllNodes" SG_ 550 ACCMCII_DtBtB 1;
BA_ "SignalType" SG_ 550 ACCMCII_DtBtA "ASC";
BA_ "PacketOrder" SG_ 550 ACCMCII_DtBtA 4;
BA_ "SignalLongName" SG_ 550 ACCMCII_DtBtA "Air Compressor Control Module Calibration Identification : Data Byte A";
BA_ "VNSigAllNodes" SG_ 550 ACCMCII_DtBtA 1;
BA_ "SignalType" SG_ 550 ACCMCII_SeqNum "UNM";
BA_ "PacketOrder" SG_ 550 ACCMCII_SeqNum 3;
BA_ "SignalLongName" SG_ 550 ACCMCII_SeqNum "Air Compressor Control Module Calibration Identification : Sequence Number";
BA_ "VNSigAllNodes" SG_ 550 ACCMCII_SeqNum 1;
BA_ "SignalType" SG_ 550 ACCMCII_Index "UNM";
BA_ "PacketOrder" SG_ 550 ACCMCII_Index 1;
BA_ "SignalLongName" SG_ 550 ACCMCII_Index "Air Compressor Control Module Calibration Identification : Index";
BA_ "VNSigAllNodes" SG_ 550 ACCMCII_Index 1;
BA_ "SignalType" SG_ 550 ACCMCII_DatStat "ENM";
BA_ "PacketOrder" SG_ 550 ACCMCII_DatStat 2;
BA_ "SignalLongName" SG_ 550 ACCMCII_DatStat "Air Compressor Control Module Calibration Identification : Data Status";
BA_ "VNSigAllNodes" SG_ 550 ACCMCII_DatStat 1;
BA_ "PacketOrder" SG_ 548 ACCMDSO_DTCStat 1;
BA_ "SignalType" SG_ 548 ACCMDSO_DTCStat "ENM";
BA_ "SignalLongName" SG_ 548 ACCMDSO_DTCStat "Air Compressor Control Module Diagnostic Status Outputs : Diagnostic Trouble Code Status";
BA_ "VNSigAllNodes" SG_ 548 ACCMDSO_DTCStat 1;
BA_ "SignalType" SG_ 548 ACCMDSO_DTCIndx "UNM";
BA_ "PacketOrder" SG_ 548 ACCMDSO_DTCIndx 2;
BA_ "SignalLongName" SG_ 548 ACCMDSO_DTCIndx "Air Compressor Control Module Diagnostic Status Outputs : Diagnostic Trouble Code Index";
BA_ "VNSigAllNodes" SG_ 548 ACCMDSO_DTCIndx 1;
BA_ "SignalType" SG_ 548 ACCMDSI_DTCStat "ENM";
BA_ "PacketOrder" SG_ 548 ACCMDSI_DTCStat 1;
BA_ "SignalLongName" SG_ 548 ACCMDSI_DTCStat "Air Compressor Control Module Diagnostic Status Inputs : Diagnostic Trouble Code Status";
BA_ "VNSigAllNodes" SG_ 548 ACCMDSI_DTCStat 1;
BA_ "SignalType" SG_ 548 ACCMDSI_DTCIndx "UNM";
BA_ "PacketOrder" SG_ 548 ACCMDSI_DTCIndx 2;
BA_ "SignalLongName" SG_ 548 ACCMDSI_DTCIndx "Air Compressor Control Module Diagnostic Status Inputs : Diagnostic Trouble Code Index";
BA_ "VNSigAllNodes" SG_ 548 ACCMDSI_DTCIndx 1;
BA_ "PacketOrder" SG_ 548 ACCMDSG_DTCStat 1;
BA_ "SignalType" SG_ 548 ACCMDSG_DTCStat "ENM";
BA_ "SignalLongName" SG_ 548 ACCMDSG_DTCStat "Air Compressor Control Module Diagnostic Status General : Diagnostic Trouble Code Status";
BA_ "VNSigAllNodes" SG_ 548 ACCMDSG_DTCStat 1;
BA_ "PacketOrder" SG_ 548 ACCMDSG_DTCIndx 2;
BA_ "SignalType" SG_ 548 ACCMDSG_DTCIndx "UNM";
BA_ "SignalLongName" SG_ 548 ACCMDSG_DTCIndx "Air Compressor Control Module Diagnostic Status General : Diagnostic Trouble Code Index";
BA_ "VNSigAllNodes" SG_ 548 ACCMDSG_DTCIndx 1;
BA_ "SignalType" SG_ 988 AccPwrModMinCoolRq "ENM";
BA_ "SignalLongName" SG_ 988 AccPwrModMinCoolRq "Accessory Power Module Minimum Cooling Request";
BA_ "VNSigAllNodes" SG_ 988 AccPwrModMinCoolRq 1;
BA_ "SignalType" SG_ 988 A6ERRAlrmTime "UNM";
BA_ "PacketOrder" SG_ 988 A6ERRAlrmTime 2;
BA_ "SignalLongName" SG_ 988 A6ERRAlrmTime "Alarm 6 Extended Range Request : Alarm Time";
BA_ "VNSigAllNodes" SG_ 988 A6ERRAlrmTime 1;
BA_ "SignalType" SG_ 988 A6ERRAlrmReq "ENM";
BA_ "PacketOrder" SG_ 988 A6ERRAlrmReq 1;
BA_ "SignalLongName" SG_ 988 A6ERRAlrmReq "Alarm 6 Extended Range Request : Alarm Request";
BA_ "VNSigAllNodes" SG_ 988 A6ERRAlrmReq 1;
BA_ "SignalType" SG_ 988 EngMntncePrcntCpl "UNM";
BA_ "SignalLongName" SG_ 988 EngMntncePrcntCpl "Engine Maintenance Percent Complete";
BA_ "VNSigAllNodes" SG_ 988 EngMntncePrcntCpl 1;
BA_ "SignalType" SG_ 988 MntnceMdDsplyRq "ENM";
BA_ "SignalLongName" SG_ 988 MntnceMdDsplyRq "Maintenance Mode Display Request";
BA_ "VNSigAllNodes" SG_ 988 MntnceMdDsplyRq 1;
BA_ "SignalType" SG_ 988 EngMntnceMdAct "BLN";
BA_ "SignalLongName" SG_ 988 EngMntnceMdAct "Engine Maintenance Mode Active";
BA_ "VNSigAllNodes" SG_ 988 EngMntnceMdAct 1;
BA_ "SignalType" SG_ 988 HVPropChgrUnbl "BLN";
BA_ "SignalLongName" SG_ 988 HVPropChgrUnbl "High Voltage Propulsion Charging Unavailable";
BA_ "VNSigAllNodes" SG_ 988 HVPropChgrUnbl 1;
BA_ "SignalType" SG_ 988 EngHtrValvBpasCmd "ENM";
BA_ "SignalLongName" SG_ 988 EngHtrValvBpasCmd "Engine Heater Valve Bypass Command";
BA_ "VNSigAllNodes" SG_ 988 EngHtrValvBpasCmd 1;
BA_ "SignalType" SG_ 1029 FCO6D_ObjVertVar "SNM";
BA_ "PacketOrder" SG_ 1029 FCO6D_ObjVertVar 8;
BA_ "SignalLongName" SG_ 1029 FCO6D_ObjVertVar "Forward Camera Object 6 Detected : Object Vertical Variance";
BA_ "VNSigAllNodes" SG_ 1029 FCO6D_ObjVertVar 1;
BA_ "SignalType" SG_ 1029 FCO6D_ObjVertPos "SNM";
BA_ "PacketOrder" SG_ 1029 FCO6D_ObjVertPos 7;
BA_ "SignalLongName" SG_ 1029 FCO6D_ObjVertPos "Forward Camera Object 6 Detected : Object Vertical Position";
BA_ "VNSigAllNodes" SG_ 1029 FCO6D_ObjVertPos 1;
BA_ "SignalType" SG_ 1029 FCO6D_ObjTyp "ENM";
BA_ "PacketOrder" SG_ 1029 FCO6D_ObjTyp 3;
BA_ "SignalLongName" SG_ 1029 FCO6D_ObjTyp "Forward Camera Object 6 Detected : Object Type";
BA_ "VNSigAllNodes" SG_ 1029 FCO6D_ObjTyp 1;
BA_ "PacketOrder" SG_ 1029 FCO6D_ObjQlty 1;
BA_ "SignalType" SG_ 1029 FCO6D_ObjQlty "ENM";
BA_ "SignalLongName" SG_ 1029 FCO6D_ObjQlty "Forward Camera Object 6 Detected : Object Quality";
BA_ "VNSigAllNodes" SG_ 1029 FCO6D_ObjQlty 1;
BA_ "SignalType" SG_ 1029 FCO6D_ObjId "UNM";
BA_ "PacketOrder" SG_ 1029 FCO6D_ObjId 2;
BA_ "SignalLongName" SG_ 1029 FCO6D_ObjId "Forward Camera Object 6 Detected : Object ID";
BA_ "VNSigAllNodes" SG_ 1029 FCO6D_ObjId 1;
BA_ "SignalType" SG_ 1029 FCO6D_ObjHorzPos "SNM";
BA_ "PacketOrder" SG_ 1029 FCO6D_ObjHorzPos 4;
BA_ "SignalLongName" SG_ 1029 FCO6D_ObjHorzPos "Forward Camera Object 6 Detected : Object Horizontal Position";
BA_ "VNSigAllNodes" SG_ 1029 FCO6D_ObjHorzPos 1;
BA_ "SignalType" SG_ 1029 FCO6D_ObjHorzDim "UNM";
BA_ "PacketOrder" SG_ 1029 FCO6D_ObjHorzDim 6;
BA_ "SignalLongName" SG_ 1029 FCO6D_ObjHorzDim "Forward Camera Object 6 Detected : Object Horizontal Dimension";
BA_ "VNSigAllNodes" SG_ 1029 FCO6D_ObjHorzDim 1;
BA_ "SignalType" SG_ 1029 FCO6D_ObjDist "UNM";
BA_ "PacketOrder" SG_ 1029 FCO6D_ObjDist 9;
BA_ "SignalLongName" SG_ 1029 FCO6D_ObjDist "Forward Camera Object 6 Detected : Object Distance";
BA_ "VNSigAllNodes" SG_ 1029 FCO6D_ObjDist 1;
BA_ "SignalType" SG_ 1029 FCO6D_DetMthd "ENM";
BA_ "PacketOrder" SG_ 1029 FCO6D_DetMthd 5;
BA_ "SignalLongName" SG_ 1029 FCO6D_DetMthd "Forward Camera Object 6 Detected : Detection Method";
BA_ "VNSigAllNodes" SG_ 1029 FCO6D_DetMthd 1;
BA_ "SignalType" SG_ 1028 FCO5D_ObjVertVar "SNM";
BA_ "PacketOrder" SG_ 1028 FCO5D_ObjVertVar 8;
BA_ "SignalLongName" SG_ 1028 FCO5D_ObjVertVar "Forward Camera Object 5 Detected : Object Vertical Variance";
BA_ "VNSigAllNodes" SG_ 1028 FCO5D_ObjVertVar 1;
BA_ "SignalType" SG_ 1028 FCO5D_ObjVertPos "SNM";
BA_ "PacketOrder" SG_ 1028 FCO5D_ObjVertPos 7;
BA_ "SignalLongName" SG_ 1028 FCO5D_ObjVertPos "Forward Camera Object 5 Detected : Object Vertical Position";
BA_ "VNSigAllNodes" SG_ 1028 FCO5D_ObjVertPos 1;
BA_ "SignalType" SG_ 1028 FCO5D_ObjTyp "ENM";
BA_ "PacketOrder" SG_ 1028 FCO5D_ObjTyp 3;
BA_ "SignalLongName" SG_ 1028 FCO5D_ObjTyp "Forward Camera Object 5 Detected : Object Type";
BA_ "VNSigAllNodes" SG_ 1028 FCO5D_ObjTyp 1;
BA_ "PacketOrder" SG_ 1028 FCO5D_ObjQlty 1;
BA_ "SignalType" SG_ 1028 FCO5D_ObjQlty "ENM";
BA_ "SignalLongName" SG_ 1028 FCO5D_ObjQlty "Forward Camera Object 5 Detected : Object Quality";
BA_ "VNSigAllNodes" SG_ 1028 FCO5D_ObjQlty 1;
BA_ "SignalType" SG_ 1028 FCO5D_ObjId "UNM";
BA_ "PacketOrder" SG_ 1028 FCO5D_ObjId 2;
BA_ "SignalLongName" SG_ 1028 FCO5D_ObjId "Forward Camera Object 5 Detected : Object ID";
BA_ "VNSigAllNodes" SG_ 1028 FCO5D_ObjId 1;
BA_ "SignalType" SG_ 1028 FCO5D_ObjHorzPos "SNM";
BA_ "PacketOrder" SG_ 1028 FCO5D_ObjHorzPos 4;
BA_ "SignalLongName" SG_ 1028 FCO5D_ObjHorzPos "Forward Camera Object 5 Detected : Object Horizontal Position";
BA_ "VNSigAllNodes" SG_ 1028 FCO5D_ObjHorzPos 1;
BA_ "SignalType" SG_ 1028 FCO5D_ObjHorzDim "UNM";
BA_ "PacketOrder" SG_ 1028 FCO5D_ObjHorzDim 6;
BA_ "SignalLongName" SG_ 1028 FCO5D_ObjHorzDim "Forward Camera Object 5 Detected : Object Horizontal Dimension";
BA_ "VNSigAllNodes" SG_ 1028 FCO5D_ObjHorzDim 1;
BA_ "SignalType" SG_ 1028 FCO5D_ObjDist "UNM";
BA_ "PacketOrder" SG_ 1028 FCO5D_ObjDist 9;
BA_ "SignalLongName" SG_ 1028 FCO5D_ObjDist "Forward Camera Object 5 Detected : Object Distance";
BA_ "VNSigAllNodes" SG_ 1028 FCO5D_ObjDist 1;
BA_ "SignalType" SG_ 1028 FCO5D_DetMthd "ENM";
BA_ "PacketOrder" SG_ 1028 FCO5D_DetMthd 5;
BA_ "SignalLongName" SG_ 1028 FCO5D_DetMthd "Forward Camera Object 5 Detected : Detection Method";
BA_ "VNSigAllNodes" SG_ 1028 FCO5D_DetMthd 1;
BA_ "SignalType" SG_ 500 EnhDrvMdSwChUseAct "BLN";
BA_ "SignalLongName" SG_ 500 EnhDrvMdSwChUseAct "Enhanced Driver Selected Mode Switch Chassis Use Active";
BA_ "VNSigAllNodes" SG_ 500 EnhDrvMdSwChUseAct 1;
BA_ "SignalType" SG_ 500 EnhDrvSelMdSwStat "ENM";
BA_ "SignalLongName" SG_ 500 EnhDrvSelMdSwStat "Enhanced Driver Selected Mode Switch Status";
BA_ "VNSigAllNodes" SG_ 500 EnhDrvSelMdSwStat 1;
BA_ "GenSigSendType" SG_ 500 DrvSelMd8Stat 10;
BA_ "SignalType" SG_ 500 DrvSelMd8Stat "ENM";
BA_ "SignalLongName" SG_ 500 DrvSelMd8Stat "Driver Selected Mode 8 Status";
BA_ "VNSigAllNodes" SG_ 500 DrvSelMd8Stat 1;
BA_ "GenSigSendType" SG_ 500 DrvSelMd8ReqDnd 10;
BA_ "SignalType" SG_ 500 DrvSelMd8ReqDnd "BLN";
BA_ "SignalLongName" SG_ 500 DrvSelMd8ReqDnd "Driver Selected Mode 8 Request Denied";
BA_ "VNSigAllNodes" SG_ 500 DrvSelMd8ReqDnd 1;
BA_ "GenSigSendType" SG_ 500 DrvSelMd7Stat 10;
BA_ "SignalType" SG_ 500 DrvSelMd7Stat "ENM";
BA_ "SignalLongName" SG_ 500 DrvSelMd7Stat "Driver Selected Mode 7 Status";
BA_ "VNSigAllNodes" SG_ 500 DrvSelMd7Stat 1;
BA_ "GenSigSendType" SG_ 500 DrvSelMd7ReqDnd 10;
BA_ "SignalType" SG_ 500 DrvSelMd7ReqDnd "BLN";
BA_ "SignalLongName" SG_ 500 DrvSelMd7ReqDnd "Driver Selected Mode 7 Request Denied";
BA_ "VNSigAllNodes" SG_ 500 DrvSelMd7ReqDnd 1;
BA_ "GenSigSendType" SG_ 500 DrvSelMd6Stat 10;
BA_ "SignalType" SG_ 500 DrvSelMd6Stat "ENM";
BA_ "SignalLongName" SG_ 500 DrvSelMd6Stat "Driver Selected Mode 6 Status";
BA_ "VNSigAllNodes" SG_ 500 DrvSelMd6Stat 1;
BA_ "GenSigSendType" SG_ 500 DrvSelMd6ReqDnd 10;
BA_ "SignalType" SG_ 500 DrvSelMd6ReqDnd "BLN";
BA_ "SignalLongName" SG_ 500 DrvSelMd6ReqDnd "Driver Selected Mode 6 Request Denied";
BA_ "VNSigAllNodes" SG_ 500 DrvSelMd6ReqDnd 1;
BA_ "GenSigSendType" SG_ 500 DrvSelMd5Stat 10;
BA_ "SignalType" SG_ 500 DrvSelMd5Stat "ENM";
BA_ "SignalLongName" SG_ 500 DrvSelMd5Stat "Driver Selected Mode 5 Status";
BA_ "VNSigAllNodes" SG_ 500 DrvSelMd5Stat 1;
BA_ "GenSigSendType" SG_ 500 DrvSelMd5ReqDnd 10;
BA_ "SignalType" SG_ 500 DrvSelMd5ReqDnd "BLN";
BA_ "SignalLongName" SG_ 500 DrvSelMd5ReqDnd "Driver Selected Mode 5 Request Denied";
BA_ "VNSigAllNodes" SG_ 500 DrvSelMd5ReqDnd 1;
BA_ "GenSigSendType" SG_ 500 DrvSelMd4Stat 10;
BA_ "SignalType" SG_ 500 DrvSelMd4Stat "ENM";
BA_ "SignalLongName" SG_ 500 DrvSelMd4Stat "Driver Selected Mode 4 Status";
BA_ "VNSigAllNodes" SG_ 500 DrvSelMd4Stat 1;
BA_ "GenSigSendType" SG_ 500 DrvSelMd4ReqDnd 10;
BA_ "SignalType" SG_ 500 DrvSelMd4ReqDnd "BLN";
BA_ "SignalLongName" SG_ 500 DrvSelMd4ReqDnd "Driver Selected Mode 4 Request Denied";
BA_ "VNSigAllNodes" SG_ 500 DrvSelMd4ReqDnd 1;
BA_ "GenSigSendType" SG_ 500 DrvSelMd3Stat 10;
BA_ "SignalType" SG_ 500 DrvSelMd3Stat "ENM";
BA_ "SignalLongName" SG_ 500 DrvSelMd3Stat "Driver Selected Mode 3 Status";
BA_ "VNSigAllNodes" SG_ 500 DrvSelMd3Stat 1;
BA_ "GenSigSendType" SG_ 500 DrvSelMd3ReqDnd 10;
BA_ "SignalType" SG_ 500 DrvSelMd3ReqDnd "BLN";
BA_ "SignalLongName" SG_ 500 DrvSelMd3ReqDnd "Driver Selected Mode 3 Request Denied";
BA_ "VNSigAllNodes" SG_ 500 DrvSelMd3ReqDnd 1;
BA_ "GenSigSendType" SG_ 500 DrvSelMd2Stat 10;
BA_ "SignalType" SG_ 500 DrvSelMd2Stat "ENM";
BA_ "SignalLongName" SG_ 500 DrvSelMd2Stat "Driver Selected Mode 2 Status";
BA_ "VNSigAllNodes" SG_ 500 DrvSelMd2Stat 1;
BA_ "GenSigSendType" SG_ 500 DrvSelMd2ReqDnd 10;
BA_ "SignalType" SG_ 500 DrvSelMd2ReqDnd "BLN";
BA_ "SignalLongName" SG_ 500 DrvSelMd2ReqDnd "Driver Selected Mode 2 Request Denied";
BA_ "VNSigAllNodes" SG_ 500 DrvSelMd2ReqDnd 1;
BA_ "GenSigSendType" SG_ 500 DSMSS_DrvSelMd0Pn 10;
BA_ "SignalType" SG_ 500 DSMSS_DrvSelMd0Pn "BLN";
BA_ "PacketOrder" SG_ 500 DSMSS_DrvSelMd0Pn 17;
BA_ "SignalLongName" SG_ 500 DSMSS_DrvSelMd0Pn "Driver Selected Mode Selection Status : Driver Selected Mode 0 Pending";
BA_ "VNSigAllNodes" SG_ 500 DSMSS_DrvSelMd0Pn 1;
BA_ "GenSigSendType" SG_ 500 DSMSS_DrvSelMd8Pn 10;
BA_ "SignalType" SG_ 500 DSMSS_DrvSelMd8Pn "BLN";
BA_ "PacketOrder" SG_ 500 DSMSS_DrvSelMd8Pn 16;
BA_ "SignalLongName" SG_ 500 DSMSS_DrvSelMd8Pn "Driver Selected Mode Selection Status : Driver Selected Mode 8 Pending";
BA_ "VNSigAllNodes" SG_ 500 DSMSS_DrvSelMd8Pn 1;
BA_ "GenSigSendType" SG_ 500 DSMSS_DrvSelMd7Pn 10;
BA_ "SignalType" SG_ 500 DSMSS_DrvSelMd7Pn "BLN";
BA_ "PacketOrder" SG_ 500 DSMSS_DrvSelMd7Pn 15;
BA_ "SignalLongName" SG_ 500 DSMSS_DrvSelMd7Pn "Driver Selected Mode Selection Status : Driver Selected Mode 7 Pending";
BA_ "VNSigAllNodes" SG_ 500 DSMSS_DrvSelMd7Pn 1;
BA_ "GenSigSendType" SG_ 500 DSMSS_DrvSelMd6Pn 10;
BA_ "SignalType" SG_ 500 DSMSS_DrvSelMd6Pn "BLN";
BA_ "PacketOrder" SG_ 500 DSMSS_DrvSelMd6Pn 14;
BA_ "SignalLongName" SG_ 500 DSMSS_DrvSelMd6Pn "Driver Selected Mode Selection Status : Driver Selected Mode 6 Pending";
BA_ "VNSigAllNodes" SG_ 500 DSMSS_DrvSelMd6Pn 1;
BA_ "GenSigSendType" SG_ 500 DSMSS_DrvSelMd5Pn 10;
BA_ "SignalType" SG_ 500 DSMSS_DrvSelMd5Pn "BLN";
BA_ "PacketOrder" SG_ 500 DSMSS_DrvSelMd5Pn 13;
BA_ "SignalLongName" SG_ 500 DSMSS_DrvSelMd5Pn "Driver Selected Mode Selection Status : Driver Selected Mode 5 Pending";
BA_ "VNSigAllNodes" SG_ 500 DSMSS_DrvSelMd5Pn 1;
BA_ "GenSigSendType" SG_ 500 DSMSS_DrvSelMd4Pn 10;
BA_ "SignalType" SG_ 500 DSMSS_DrvSelMd4Pn "BLN";
BA_ "PacketOrder" SG_ 500 DSMSS_DrvSelMd4Pn 12;
BA_ "SignalLongName" SG_ 500 DSMSS_DrvSelMd4Pn "Driver Selected Mode Selection Status : Driver Selected Mode 4 Pending";
BA_ "VNSigAllNodes" SG_ 500 DSMSS_DrvSelMd4Pn 1;
BA_ "GenSigSendType" SG_ 500 DSMSS_DrvSelMd3Pn 10;
BA_ "SignalType" SG_ 500 DSMSS_DrvSelMd3Pn "BLN";
BA_ "PacketOrder" SG_ 500 DSMSS_DrvSelMd3Pn 11;
BA_ "SignalLongName" SG_ 500 DSMSS_DrvSelMd3Pn "Driver Selected Mode Selection Status : Driver Selected Mode 3 Pending";
BA_ "VNSigAllNodes" SG_ 500 DSMSS_DrvSelMd3Pn 1;
BA_ "GenSigSendType" SG_ 500 DSMSS_DrvSelMd2Pn 10;
BA_ "SignalType" SG_ 500 DSMSS_DrvSelMd2Pn "BLN";
BA_ "PacketOrder" SG_ 500 DSMSS_DrvSelMd2Pn 10;
BA_ "SignalLongName" SG_ 500 DSMSS_DrvSelMd2Pn "Driver Selected Mode Selection Status : Driver Selected Mode 2 Pending";
BA_ "VNSigAllNodes" SG_ 500 DSMSS_DrvSelMd2Pn 1;
BA_ "GenSigSendType" SG_ 500 DSMSS_DrvSelMd1Pn 10;
BA_ "SignalType" SG_ 500 DSMSS_DrvSelMd1Pn "BLN";
BA_ "PacketOrder" SG_ 500 DSMSS_DrvSelMd1Pn 9;
BA_ "SignalLongName" SG_ 500 DSMSS_DrvSelMd1Pn "Driver Selected Mode Selection Status : Driver Selected Mode 1 Pending";
BA_ "VNSigAllNodes" SG_ 500 DSMSS_DrvSelMd1Pn 1;
BA_ "GenSigSendType" SG_ 500 DSMSS_DrvSelMd8Un 10;
BA_ "SignalType" SG_ 500 DSMSS_DrvSelMd8Un "BLN";
BA_ "PacketOrder" SG_ 500 DSMSS_DrvSelMd8Un 8;
BA_ "SignalLongName" SG_ 500 DSMSS_DrvSelMd8Un "Driver Selected Mode Selection Status : Driver Selected Mode 8 Unavailable";
BA_ "VNSigAllNodes" SG_ 500 DSMSS_DrvSelMd8Un 1;
BA_ "GenSigSendType" SG_ 500 DSMSS_DrvSelMd7Un 10;
BA_ "SignalType" SG_ 500 DSMSS_DrvSelMd7Un "BLN";
BA_ "PacketOrder" SG_ 500 DSMSS_DrvSelMd7Un 7;
BA_ "SignalLongName" SG_ 500 DSMSS_DrvSelMd7Un "Driver Selected Mode Selection Status : Driver Selected Mode 7 Unavailable";
BA_ "VNSigAllNodes" SG_ 500 DSMSS_DrvSelMd7Un 1;
BA_ "GenSigSendType" SG_ 500 DSMSS_DrvSelMd6Un 10;
BA_ "SignalType" SG_ 500 DSMSS_DrvSelMd6Un "BLN";
BA_ "PacketOrder" SG_ 500 DSMSS_DrvSelMd6Un 6;
BA_ "SignalLongName" SG_ 500 DSMSS_DrvSelMd6Un "Driver Selected Mode Selection Status : Driver Selected Mode 6 Unavailable";
BA_ "VNSigAllNodes" SG_ 500 DSMSS_DrvSelMd6Un 1;
BA_ "GenSigSendType" SG_ 500 DSMSS_DrvSelMd5Un 10;
BA_ "SignalType" SG_ 500 DSMSS_DrvSelMd5Un "BLN";
BA_ "PacketOrder" SG_ 500 DSMSS_DrvSelMd5Un 5;
BA_ "SignalLongName" SG_ 500 DSMSS_DrvSelMd5Un "Driver Selected Mode Selection Status : Driver Selected Mode 5 Unavailable";
BA_ "VNSigAllNodes" SG_ 500 DSMSS_DrvSelMd5Un 1;
BA_ "GenSigSendType" SG_ 500 DSMSS_DrvSelMd4Un 10;
BA_ "SignalType" SG_ 500 DSMSS_DrvSelMd4Un "BLN";
BA_ "PacketOrder" SG_ 500 DSMSS_DrvSelMd4Un 4;
BA_ "SignalLongName" SG_ 500 DSMSS_DrvSelMd4Un "Driver Selected Mode Selection Status : Driver Selected Mode 4 Unavailable";
BA_ "VNSigAllNodes" SG_ 500 DSMSS_DrvSelMd4Un 1;
BA_ "GenSigSendType" SG_ 500 DSMSS_DrvSelMd3Un 10;
BA_ "SignalType" SG_ 500 DSMSS_DrvSelMd3Un "BLN";
BA_ "PacketOrder" SG_ 500 DSMSS_DrvSelMd3Un 3;
BA_ "SignalLongName" SG_ 500 DSMSS_DrvSelMd3Un "Driver Selected Mode Selection Status : Driver Selected Mode 3 Unavailable";
BA_ "VNSigAllNodes" SG_ 500 DSMSS_DrvSelMd3Un 1;
BA_ "GenSigSendType" SG_ 500 DSMSS_DrvSelMd2Un 10;
BA_ "SignalType" SG_ 500 DSMSS_DrvSelMd2Un "BLN";
BA_ "PacketOrder" SG_ 500 DSMSS_DrvSelMd2Un 2;
BA_ "SignalLongName" SG_ 500 DSMSS_DrvSelMd2Un "Driver Selected Mode Selection Status : Driver Selected Mode 2 Unavailable";
BA_ "VNSigAllNodes" SG_ 500 DSMSS_DrvSelMd2Un 1;
BA_ "GenSigSendType" SG_ 500 DSMSS_DrvSelMd1Un 10;
BA_ "SignalType" SG_ 500 DSMSS_DrvSelMd1Un "BLN";
BA_ "PacketOrder" SG_ 500 DSMSS_DrvSelMd1Un 1;
BA_ "SignalLongName" SG_ 500 DSMSS_DrvSelMd1Un "Driver Selected Mode Selection Status : Driver Selected Mode 1 Unavailable";
BA_ "VNSigAllNodes" SG_ 500 DSMSS_DrvSelMd1Un 1;
BA_ "GenSigSendType" SG_ 500 DrvSelMd1ReqDnd 10;
BA_ "SignalType" SG_ 500 DrvSelMd1ReqDnd "BLN";
BA_ "SignalLongName" SG_ 500 DrvSelMd1ReqDnd "Driver Selected Mode 1 Request Denied";
BA_ "VNSigAllNodes" SG_ 500 DrvSelMd1ReqDnd 1;
BA_ "GenSigSendType" SG_ 500 DrvSelMd1Stat 10;
BA_ "SignalType" SG_ 500 DrvSelMd1Stat "ENM";
BA_ "SignalLongName" SG_ 500 DrvSelMd1Stat "Driver Selected Mode 1 Status";
BA_ "VNSigAllNodes" SG_ 500 DrvSelMd1Stat 1;
BA_ "SignalType" SG_ 1417 PrplsnTrqRelCap "UNM";
BA_ "SignalLongName" SG_ 1417 PrplsnTrqRelCap "Propulsion Torque Relative Capability";
BA_ "VNSigAllNodes" SG_ 1417 PrplsnTrqRelCap 1;
BA_ "SignalType" SG_ 1417 ETC_MinTorq "UNM";
BA_ "PacketOrder" SG_ 1417 ETC_MinTorq 7;
BA_ "SignalLongName" SG_ 1417 ETC_MinTorq "Engine Torque Capability : Minimum Torque";
BA_ "VNSigAllNodes" SG_ 1417 ETC_MinTorq 1;
BA_ "SignalType" SG_ 1417 ETC_MinRunTorq "UNM";
BA_ "PacketOrder" SG_ 1417 ETC_MinRunTorq 6;
BA_ "SignalLongName" SG_ 1417 ETC_MinRunTorq "Engine Torque Capability : Minimum Run Torque";
BA_ "VNSigAllNodes" SG_ 1417 ETC_MinRunTorq 1;
BA_ "SignalType" SG_ 1417 ETC_MaxTorq "UNM";
BA_ "PacketOrder" SG_ 1417 ETC_MaxTorq 5;
BA_ "SignalLongName" SG_ 1417 ETC_MaxTorq "Engine Torque Capability : Maximum Torque";
BA_ "VNSigAllNodes" SG_ 1417 ETC_MaxTorq 1;
BA_ "SignalType" SG_ 1417 ETC_RefEngSpd "UNM";
BA_ "PacketOrder" SG_ 1417 ETC_RefEngSpd 4;
BA_ "SignalLongName" SG_ 1417 ETC_RefEngSpd "Engine Torque Capability : Reference Engine Speed";
BA_ "VNSigAllNodes" SG_ 1417 ETC_RefEngSpd 1;
BA_ "SignalType" SG_ 1417 ETC_UnsdRsrvd "UNM";
BA_ "PacketOrder" SG_ 1417 ETC_UnsdRsrvd 3;
BA_ "SignalLongName" SG_ 1417 ETC_UnsdRsrvd "Engine Torque Capability : Unused and Reserved";
BA_ "VNSigAllNodes" SG_ 1417 ETC_UnsdRsrvd 1;
BA_ "SignalType" SG_ 1417 ETC_FrmCntr "UNM";
BA_ "PacketOrder" SG_ 1417 ETC_FrmCntr 2;
BA_ "SignalLongName" SG_ 1417 ETC_FrmCntr "Engine Torque Capability : Frame Counter";
BA_ "VNSigAllNodes" SG_ 1417 ETC_FrmCntr 1;
BA_ "SignalType" SG_ 1417 ETC_EngOpMd "ENM";
BA_ "PacketOrder" SG_ 1417 ETC_EngOpMd 1;
BA_ "SignalLongName" SG_ 1417 ETC_EngOpMd "Engine Torque Capability : Engine Operating Mode";
BA_ "VNSigAllNodes" SG_ 1417 ETC_EngOpMd 1;
BA_ "SignalType" SG_ 407 TrnsOvrallActTorqRatioV "ENM";
BA_ "SignalLongName" SG_ 407 TrnsOvrallActTorqRatioV "Transmission Overall Actual Torque Ratio Validity";
BA_ "VNSigAllNodes" SG_ 407 TrnsOvrallActTorqRatioV 1;
BA_ "SignalType" SG_ 407 TrnsOvrallActTorqRatio "SNM";
BA_ "SignalLongName" SG_ 407 TrnsOvrallActTorqRatio "Transmission Overall Actual Torque Ratio";
BA_ "VNSigAllNodes" SG_ 407 TrnsOvrallActTorqRatio 1;
BA_ "SignalType" SG_ 189 TransVehTopSpdLim "UNM";
BA_ "SignalLongName" SG_ 189 TransVehTopSpdLim "Transmission Vehicle Top Speed Limit Value";
BA_ "VNSigAllNodes" SG_ 189 TransVehTopSpdLim 1;
BA_ "SignalType" SG_ 189 TransMinVoltReq "UNM";
BA_ "SignalLongName" SG_ 189 TransMinVoltReq "Transmission Minimum Voltage Request";
BA_ "VNSigAllNodes" SG_ 189 TransMinVoltReq 1;
BA_ "SignalType" SG_ 189 TrnsRtoCntlSysFlt "BLN";
BA_ "SignalLongName" SG_ 189 TrnsRtoCntlSysFlt "Transmission Ratio Control System Fault";
BA_ "VNSigAllNodes" SG_ 189 TrnsRtoCntlSysFlt 1;
BA_ "SignalType" SG_ 189 TransMnPressEstmd "UNM";
BA_ "SignalLongName" SG_ 189 TransMnPressEstmd "Transmission Main Pressure Estimated";
BA_ "VNSigAllNodes" SG_ 189 TransMnPressEstmd 1;
BA_ "SignalType" SG_ 189 TrnsInpMinSpdRq "ENM";
BA_ "SignalLongName" SG_ 189 TrnsInpMinSpdRq "Transmission Input Minimum Speed Request";
BA_ "VNSigAllNodes" SG_ 189 TrnsInpMinSpdRq 1;
BA_ "SignalType" SG_ 189 TrnsHydPrsDsrd "UNM";
BA_ "SignalLongName" SG_ 189 TrnsHydPrsDsrd "Transmission Hydraulic Pressure Desired";
BA_ "VNSigAllNodes" SG_ 189 TrnsHydPrsDsrd 1;
BA_ "SignalType" SG_ 189 TransAuxPumpSpdDsrd "UNM";
BA_ "SignalLongName" SG_ 189 TransAuxPumpSpdDsrd "Transmission Auxiliary Pump Speed Desired";
BA_ "VNSigAllNodes" SG_ 189 TransAuxPumpSpdDsrd 1;
BA_ "SignalType" SG_ 187 TransClch5_TorqCmnd "UNM";
BA_ "SignalLongName" SG_ 187 TransClch5_TorqCmnd "Transmission Clutch 5 Torque Command";
BA_ "VNSigAllNodes" SG_ 187 TransClch5_TorqCmnd 1;
BA_ "SignalType" SG_ 187 TransCltch5MinPrsRq "UNM";
BA_ "SignalLongName" SG_ 187 TransCltch5MinPrsRq "Transmission Clutch 5 Minimum Pressure Required";
BA_ "VNSigAllNodes" SG_ 187 TransCltch5MinPrsRq 1;
BA_ "SignalType" SG_ 187 TransCltch5FillCmd "ENM";
BA_ "SignalLongName" SG_ 187 TransCltch5FillCmd "Transmission Clutch 5 Fill Commanded";
BA_ "VNSigAllNodes" SG_ 187 TransCltch5FillCmd 1;
BA_ "SignalType" SG_ 187 TransClch4_TorqCmnd "UNM";
BA_ "SignalLongName" SG_ 187 TransClch4_TorqCmnd "Transmission Clutch 4 Torque Command";
BA_ "VNSigAllNodes" SG_ 187 TransClch4_TorqCmnd 1;
BA_ "SignalType" SG_ 187 TransCltch4MinPrsRq "UNM";
BA_ "SignalLongName" SG_ 187 TransCltch4MinPrsRq "Transmission Clutch 4 Minimum Pressure Required";
BA_ "VNSigAllNodes" SG_ 187 TransCltch4MinPrsRq 1;
BA_ "SignalType" SG_ 187 TransCltch4FillCmd "ENM";
BA_ "SignalLongName" SG_ 187 TransCltch4FillCmd "Transmission Clutch 4 Fill Commanded";
BA_ "VNSigAllNodes" SG_ 187 TransCltch4FillCmd 1;
BA_ "SignalType" SG_ 185 TransCltch1FillCmd "ENM";
BA_ "SignalLongName" SG_ 185 TransCltch1FillCmd "Transmission Clutch 1 Fill Commanded";
BA_ "VNSigAllNodes" SG_ 185 TransCltch1FillCmd 1;
BA_ "SignalType" SG_ 185 TransCltch1CntlRqPVal "UNM";
BA_ "SignalLongName" SG_ 185 TransCltch1CntlRqPVal "Transmission Clutch 1 Control Requested Protection Value";
BA_ "VNSigAllNodes" SG_ 185 TransCltch1CntlRqPVal 1;
BA_ "SignalType" SG_ 185 TransCltch1CntlRq "ENM";
BA_ "SignalLongName" SG_ 185 TransCltch1CntlRq "Transmission Clutch 1 Control Requested";
BA_ "VNSigAllNodes" SG_ 185 TransCltch1CntlRq 1;
BA_ "SignalType" SG_ 185 MtrBCoolFlwCmd "UNM";
BA_ "SignalLongName" SG_ 185 MtrBCoolFlwCmd "Motor B Cooling Flow Command";
BA_ "VNSigAllNodes" SG_ 185 MtrBCoolFlwCmd 1;
BA_ "SignalType" SG_ 185 MtrACoolFlwCmd "UNM";
BA_ "SignalLongName" SG_ 185 MtrACoolFlwCmd "Motor A Cooling Flow Command";
BA_ "VNSigAllNodes" SG_ 185 MtrACoolFlwCmd 1;
BA_ "SignalType" SG_ 185 TransCltchCntlARC "UNM";
BA_ "SignalLongName" SG_ 185 TransCltchCntlARC "Transmission Clutch Control Alive Rolling Count";
BA_ "VNSigAllNodes" SG_ 185 TransCltchCntlARC 1;
BA_ "SignalType" SG_ 185 TransCltch5CntlRqPVal "UNM";
BA_ "SignalLongName" SG_ 185 TransCltch5CntlRqPVal "Transmission Clutch 5 Control Requested Protection Value";
BA_ "VNSigAllNodes" SG_ 185 TransCltch5CntlRqPVal 1;
BA_ "SignalType" SG_ 185 TransCltch5CntlRq "ENM";
BA_ "SignalLongName" SG_ 185 TransCltch5CntlRq "Transmission Clutch 5 Control Requested";
BA_ "VNSigAllNodes" SG_ 185 TransCltch5CntlRq 1;
BA_ "SignalType" SG_ 185 TransCltch4CntlRqPVal "UNM";
BA_ "SignalLongName" SG_ 185 TransCltch4CntlRqPVal "Transmission Clutch 4 Control Requested Protection Value";
BA_ "VNSigAllNodes" SG_ 185 TransCltch4CntlRqPVal 1;
BA_ "SignalType" SG_ 185 TransCltch4CntlRq "ENM";
BA_ "SignalLongName" SG_ 185 TransCltch4CntlRq "Transmission Clutch 4 Control Requested";
BA_ "VNSigAllNodes" SG_ 185 TransCltch4CntlRq 1;
BA_ "SignalType" SG_ 185 TransCltch3CntlRqPVal "UNM";
BA_ "SignalLongName" SG_ 185 TransCltch3CntlRqPVal "Transmission Clutch 3 Control Requested Protection Value";
BA_ "VNSigAllNodes" SG_ 185 TransCltch3CntlRqPVal 1;
BA_ "SignalType" SG_ 185 TransCltch3CntlRq "ENM";
BA_ "SignalLongName" SG_ 185 TransCltch3CntlRq "Transmission Clutch 3 Control Requested";
BA_ "VNSigAllNodes" SG_ 185 TransCltch3CntlRq 1;
BA_ "SignalType" SG_ 185 TransCltch2CntlRqPVal "UNM";
BA_ "SignalLongName" SG_ 185 TransCltch2CntlRqPVal "Transmission Clutch 2 Control Requested Protection Value";
BA_ "VNSigAllNodes" SG_ 185 TransCltch2CntlRqPVal 1;
BA_ "SignalType" SG_ 185 TransCltch2CntlRq "ENM";
BA_ "SignalLongName" SG_ 185 TransCltch2CntlRq "Transmission Clutch 2 Control Requested";
BA_ "VNSigAllNodes" SG_ 185 TransCltch2CntlRq 1;
BA_ "SignalType" SG_ 185 TransClch1_TorqCmnd "UNM";
BA_ "SignalLongName" SG_ 185 TransClch1_TorqCmnd "Transmission Clutch 1 Torque Command";
BA_ "VNSigAllNodes" SG_ 185 TransClch1_TorqCmnd 1;
BA_ "SignalType" SG_ 185 TransCltch1MinPrsRq "UNM";
BA_ "SignalLongName" SG_ 185 TransCltch1MinPrsRq "Transmission Clutch 1 Minimum Pressure Required";
BA_ "VNSigAllNodes" SG_ 185 TransCltch1MinPrsRq 1;
BA_ "SignalType" SG_ 186 TransClch3_TorqCmnd "UNM";
BA_ "SignalLongName" SG_ 186 TransClch3_TorqCmnd "Transmission Clutch 3 Torque Command";
BA_ "VNSigAllNodes" SG_ 186 TransClch3_TorqCmnd 1;
BA_ "SignalType" SG_ 186 TransCltch3MinPrsRq "UNM";
BA_ "SignalLongName" SG_ 186 TransCltch3MinPrsRq "Transmission Clutch 3 Minimum Pressure Required";
BA_ "VNSigAllNodes" SG_ 186 TransCltch3MinPrsRq 1;
BA_ "SignalType" SG_ 186 TransCltch3FillCmd "ENM";
BA_ "SignalLongName" SG_ 186 TransCltch3FillCmd "Transmission Clutch 3 Fill Commanded";
BA_ "VNSigAllNodes" SG_ 186 TransCltch3FillCmd 1;
BA_ "SignalType" SG_ 186 TransClch2_TorqCmnd "UNM";
BA_ "SignalLongName" SG_ 186 TransClch2_TorqCmnd "Transmission Clutch 2 Torque Command";
BA_ "VNSigAllNodes" SG_ 186 TransClch2_TorqCmnd 1;
BA_ "SignalType" SG_ 186 TransCltch2MinPrsRq "UNM";
BA_ "SignalLongName" SG_ 186 TransCltch2MinPrsRq "Transmission Clutch 2 Minimum Pressure Required";
BA_ "VNSigAllNodes" SG_ 186 TransCltch2MinPrsRq 1;
BA_ "SignalType" SG_ 186 TransCltch2FillCmd "ENM";
BA_ "SignalLongName" SG_ 186 TransCltch2FillCmd "Transmission Clutch 2 Fill Commanded";
BA_ "VNSigAllNodes" SG_ 186 TransCltch2FillCmd 1;
BA_ "SignalType" SG_ 152 TransClch5MaxEngy "UNM";
BA_ "SignalLongName" SG_ 152 TransClch5MaxEngy "Transmission Clutch 5 Maximum Energy";
BA_ "VNSigAllNodes" SG_ 152 TransClch5MaxEngy 1;
BA_ "SignalType" SG_ 152 TransClch5FlTm "UNM";
BA_ "SignalLongName" SG_ 152 TransClch5FlTm "Transmission Clutch 5 Fill Time";
BA_ "VNSigAllNodes" SG_ 152 TransClch5FlTm 1;
BA_ "SignalType" SG_ 152 TransClch5FlAch "BLN";
BA_ "SignalLongName" SG_ 152 TransClch5FlAch "Transmission Clutch 5 Fill Achieved";
BA_ "VNSigAllNodes" SG_ 152 TransClch5FlAch 1;
BA_ "SignalType" SG_ 152 TransCltch5EstTrq "UNM";
BA_ "SignalLongName" SG_ 152 TransCltch5EstTrq "Transmission Clutch 5 Estimated Torque";
BA_ "VNSigAllNodes" SG_ 152 TransCltch5EstTrq 1;
BA_ "SignalType" SG_ 152 TransClch5_Avail "BLN";
BA_ "SignalLongName" SG_ 152 TransClch5_Avail "Transmission Clutch 5 Available";
BA_ "VNSigAllNodes" SG_ 152 TransClch5_Avail 1;
BA_ "SignalType" SG_ 152 TransClch4FlTm "UNM";
BA_ "SignalLongName" SG_ 152 TransClch4FlTm "Transmission Clutch 4 Fill Time";
BA_ "VNSigAllNodes" SG_ 152 TransClch4FlTm 1;
BA_ "SignalType" SG_ 152 TransClch4EstTorq "UNM";
BA_ "SignalLongName" SG_ 152 TransClch4EstTorq "Transmission Clutch 4 Estimated Torque";
BA_ "VNSigAllNodes" SG_ 152 TransClch4EstTorq 1;
BA_ "SignalType" SG_ 152 TransClch4MaxEnrgy "UNM";
BA_ "SignalLongName" SG_ 152 TransClch4MaxEnrgy "Transmission Clutch 4 Maximum Energy";
BA_ "VNSigAllNodes" SG_ 152 TransClch4MaxEnrgy 1;
BA_ "SignalType" SG_ 152 TransClch4FlAch "BLN";
BA_ "SignalLongName" SG_ 152 TransClch4FlAch "Transmission Clutch 4 Fill Achieved";
BA_ "VNSigAllNodes" SG_ 152 TransClch4FlAch 1;
BA_ "SignalType" SG_ 152 TransClch4_Avail "BLN";
BA_ "SignalLongName" SG_ 152 TransClch4_Avail "Transmission Clutch 4 Available";
BA_ "VNSigAllNodes" SG_ 152 TransClch4_Avail 1;
BA_ "SignalType" SG_ 151 TransClch3FlTm "UNM";
BA_ "SignalLongName" SG_ 151 TransClch3FlTm "Transmission Clutch 3 Fill Time";
BA_ "VNSigAllNodes" SG_ 151 TransClch3FlTm 1;
BA_ "SignalType" SG_ 151 TransClch3EstTorq "UNM";
BA_ "SignalLongName" SG_ 151 TransClch3EstTorq "Transmission Clutch 3 Estimated Torque";
BA_ "VNSigAllNodes" SG_ 151 TransClch3EstTorq 1;
BA_ "SignalType" SG_ 151 TransClch3MaxEnrgy "UNM";
BA_ "SignalLongName" SG_ 151 TransClch3MaxEnrgy "Transmission Clutch 3 Maximum Energy";
BA_ "VNSigAllNodes" SG_ 151 TransClch3MaxEnrgy 1;
BA_ "SignalType" SG_ 151 TransClch3FlAch "BLN";
BA_ "SignalLongName" SG_ 151 TransClch3FlAch "Transmission Clutch 3 Fill Achieved";
BA_ "VNSigAllNodes" SG_ 151 TransClch3FlAch 1;
BA_ "SignalType" SG_ 151 TransClch3_Avail "BLN";
BA_ "SignalLongName" SG_ 151 TransClch3_Avail "Transmission Clutch 3 Available";
BA_ "VNSigAllNodes" SG_ 151 TransClch3_Avail 1;
BA_ "SignalType" SG_ 151 TransClch2FlTm "UNM";
BA_ "SignalLongName" SG_ 151 TransClch2FlTm "Transmission Clutch 2 Fill Time";
BA_ "VNSigAllNodes" SG_ 151 TransClch2FlTm 1;
BA_ "SignalType" SG_ 151 TransClch2EstTorq "UNM";
BA_ "SignalLongName" SG_ 151 TransClch2EstTorq "Transmission Clutch 2 Estimated Torque";
BA_ "VNSigAllNodes" SG_ 151 TransClch2EstTorq 1;
BA_ "SignalType" SG_ 151 TransClch2MaxEnrgy "UNM";
BA_ "SignalLongName" SG_ 151 TransClch2MaxEnrgy "Transmission Clutch 2 Maximum Energy";
BA_ "VNSigAllNodes" SG_ 151 TransClch2MaxEnrgy 1;
BA_ "SignalType" SG_ 151 TransClch2FlAch "BLN";
BA_ "SignalLongName" SG_ 151 TransClch2FlAch "Transmission Clutch 2 Fill Achieved";
BA_ "VNSigAllNodes" SG_ 151 TransClch2FlAch 1;
BA_ "SignalType" SG_ 151 TransClch2_Avail "BLN";
BA_ "SignalLongName" SG_ 151 TransClch2_Avail "Transmission Clutch 2 Available";
BA_ "VNSigAllNodes" SG_ 151 TransClch2_Avail 1;
BA_ "SignalType" SG_ 150 TrnsInpDvcStat "ENM";
BA_ "SignalLongName" SG_ 150 TrnsInpDvcStat "Transmission Input Device Status";
BA_ "VNSigAllNodes" SG_ 150 TrnsInpDvcStat 1;
BA_ "SignalType" SG_ 150 TransInhibitNeut "BLN";
BA_ "SignalLongName" SG_ 150 TransInhibitNeut "Transmission Default Action Inhibit Neutral";
BA_ "VNSigAllNodes" SG_ 150 TransInhibitNeut 1;
BA_ "SignalType" SG_ 150 TransInhibitMode2 "BLN";
BA_ "SignalLongName" SG_ 150 TransInhibitMode2 "Transmission Default Action Inhibit Mode 2";
BA_ "VNSigAllNodes" SG_ 150 TransInhibitMode2 1;
BA_ "SignalType" SG_ 150 TransInhibitMode1 "BLN";
BA_ "SignalLongName" SG_ 150 TransInhibitMode1 "Transmission Default Action Inhibit Mode 1";
BA_ "VNSigAllNodes" SG_ 150 TransInhibitMode1 1;
BA_ "SignalType" SG_ 150 TransInhibitGear4 "BLN";
BA_ "SignalLongName" SG_ 150 TransInhibitGear4 "Transmission Default Action Inhibit Gear 4";
BA_ "VNSigAllNodes" SG_ 150 TransInhibitGear4 1;
BA_ "SignalType" SG_ 150 TransInhibitGear3 "BLN";
BA_ "SignalLongName" SG_ 150 TransInhibitGear3 "Transmission Default Action Inhibit Gear 3";
BA_ "VNSigAllNodes" SG_ 150 TransInhibitGear3 1;
BA_ "SignalType" SG_ 150 TransInhibitGear2 "BLN";
BA_ "SignalLongName" SG_ 150 TransInhibitGear2 "Transmission Default Action Inhibit Gear 2";
BA_ "VNSigAllNodes" SG_ 150 TransInhibitGear2 1;
BA_ "SignalType" SG_ 150 TransInhibitGear1 "BLN";
BA_ "SignalLongName" SG_ 150 TransInhibitGear1 "Transmission Default Action Inhibit Gear 1";
BA_ "VNSigAllNodes" SG_ 150 TransInhibitGear1 1;
BA_ "SignalType" SG_ 150 TrnsPTSysShtdwnRq "BLN";
BA_ "SignalLongName" SG_ 150 TrnsPTSysShtdwnRq "Transmission Powertrain System Shutdown Requested";
BA_ "VNSigAllNodes" SG_ 150 TrnsPTSysShtdwnRq 1;
BA_ "SignalType" SG_ 150 TransClch1FlTm "UNM";
BA_ "SignalLongName" SG_ 150 TransClch1FlTm "Transmission Clutch 1 Fill Time";
BA_ "VNSigAllNodes" SG_ 150 TransClch1FlTm 1;
BA_ "SignalType" SG_ 150 TransClch1EstTorq "UNM";
BA_ "SignalLongName" SG_ 150 TransClch1EstTorq "Transmission Clutch 1 Estimated Torque";
BA_ "VNSigAllNodes" SG_ 150 TransClch1EstTorq 1;
BA_ "SignalType" SG_ 150 TransClch1MaxEnrgy "UNM";
BA_ "SignalLongName" SG_ 150 TransClch1MaxEnrgy "Transmission Clutch 1 Maximum Energy";
BA_ "VNSigAllNodes" SG_ 150 TransClch1MaxEnrgy 1;
BA_ "SignalType" SG_ 150 TransClch1FlAch "BLN";
BA_ "SignalLongName" SG_ 150 TransClch1FlAch "Transmission Clutch 1 Fill Achieved";
BA_ "VNSigAllNodes" SG_ 150 TransClch1FlAch 1;
BA_ "SignalType" SG_ 150 TransClch1_Avail "BLN";
BA_ "SignalLongName" SG_ 150 TransClch1_Avail "Transmission Clutch 1 Available";
BA_ "VNSigAllNodes" SG_ 150 TransClch1_Avail 1;
BA_ "SignalType" SG_ 188 HybTrnsLubeFlwRqd "UNM";
BA_ "SignalLongName" SG_ 188 HybTrnsLubeFlwRqd "Hybrid Transmission Lube Flow Requested";
BA_ "VNSigAllNodes" SG_ 188 HybTrnsLubeFlwRqd 1;
BA_ "SignalType" SG_ 188 MtrBSpd "SNM";
BA_ "SignalLongName" SG_ 188 MtrBSpd "Motor B Speed";
BA_ "VNSigAllNodes" SG_ 188 MtrBSpd 1;
BA_ "SignalType" SG_ 188 MtrASpd "SNM";
BA_ "SignalLongName" SG_ 188 MtrASpd "Motor A Speed";
BA_ "VNSigAllNodes" SG_ 188 MtrASpd 1;
BA_ "SignalType" SG_ 188 HybTransStCmmnd "ENM";
BA_ "SignalLongName" SG_ 188 HybTransStCmmnd "Hybrid Transmission State Commanded";
BA_ "VNSigAllNodes" SG_ 188 HybTransStCmmnd 1;
BA_ "SignalType" SG_ 188 HybTransStAchvd "ENM";
BA_ "SignalLongName" SG_ 188 HybTransStAchvd "Hybrid Transmission State Achieved";
BA_ "VNSigAllNodes" SG_ 188 HybTransStAchvd 1;
BA_ "SignalType" SG_ 188 TransFldPmpCmd "ENM";
BA_ "SignalLongName" SG_ 188 TransFldPmpCmd "Transmission Fluid Pump Command";
BA_ "VNSigAllNodes" SG_ 188 TransFldPmpCmd 1;
BA_ "SignalType" SG_ 188 TransDirctnStV "ENM";
BA_ "SignalLongName" SG_ 188 TransDirctnStV "Transmission Direction State Validity";
BA_ "VNSigAllNodes" SG_ 188 TransDirctnStV 1;
BA_ "SignalType" SG_ 188 TransDirctnSt "ENM";
BA_ "SignalLongName" SG_ 188 TransDirctnSt "Transmission Direction State";
BA_ "VNSigAllNodes" SG_ 188 TransDirctnSt 1;
BA_ "SignalType" SG_ 188 TnsClchFlLnePrsBstRq "BLN";
BA_ "SignalLongName" SG_ 188 TnsClchFlLnePrsBstRq "Transmission Clutch Fill Line Pressure Boost Requested";
BA_ "VNSigAllNodes" SG_ 188 TnsClchFlLnePrsBstRq 1;
BA_ "SignalType" SG_ 188 TransAuxPumpSpd "UNM";
BA_ "SignalLongName" SG_ 188 TransAuxPumpSpd "Transmission Auxiliary Pump Speed";
BA_ "VNSigAllNodes" SG_ 188 TransAuxPumpSpd 1;
BA_ "SignalType" SG_ 188 TransAuxPumpAvail "BLN";
BA_ "SignalLongName" SG_ 188 TransAuxPumpAvail "Transmission Auxiliary Pump Available";
BA_ "VNSigAllNodes" SG_ 188 TransAuxPumpAvail 1;
BA_ "SignalType" SG_ 188 MtrBSpdV "ENM";
BA_ "SignalLongName" SG_ 188 MtrBSpdV "Motor B Speed Validity";
BA_ "VNSigAllNodes" SG_ 188 MtrBSpdV 1;
BA_ "SignalType" SG_ 188 MtrASpdV "ENM";
BA_ "SignalLongName" SG_ 188 MtrASpdV "Motor A Speed Validity";
BA_ "VNSigAllNodes" SG_ 188 MtrASpdV 1;
BA_ "SignalType" SG_ 170 EngCommFlrRedPwrCm "BLN";
BA_ "SignalLongName" SG_ 170 EngCommFlrRedPwrCm "Engine Communication Failure Reduced Power Commanded";
BA_ "VNSigAllNodes" SG_ 170 EngCommFlrRedPwrCm 1;
BA_ "SignalType" SG_ 170 CmndAxlTrqARC "UNM";
BA_ "SignalLongName" SG_ 170 CmndAxlTrqARC "Commanded Axle Torque Alive Rolling Count";
BA_ "VNSigAllNodes" SG_ 170 CmndAxlTrqARC 1;
BA_ "SignalType" SG_ 170 CmndAxlTrqRespTyp "ENM";
BA_ "SignalLongName" SG_ 170 CmndAxlTrqRespTyp "Commanded Axle Torque Response Type";
BA_ "VNSigAllNodes" SG_ 170 CmndAxlTrqRespTyp 1;
BA_ "SignalType" SG_ 170 CmndAxlTrqImm "UNM";
BA_ "SignalLongName" SG_ 170 CmndAxlTrqImm "Commanded Axle Torque Immediate";
BA_ "VNSigAllNodes" SG_ 170 CmndAxlTrqImm 1;
BA_ "SignalType" SG_ 170 AccPos "UNM";
BA_ "SignalLongName" SG_ 170 AccPos "Accelerator Effective Position";
BA_ "VNSigAllNodes" SG_ 170 AccPos 1;
BA_ "SignalType" SG_ 170 CmndAxlTrqPredct "UNM";
BA_ "SignalLongName" SG_ 170 CmndAxlTrqPredct "Commanded Axle Torque Predicted";
BA_ "VNSigAllNodes" SG_ 170 CmndAxlTrqPredct 1;
BA_ "SignalType" SG_ 170 CmndAxlTrqPredctProtVal "UNM";
BA_ "SignalLongName" SG_ 170 CmndAxlTrqPredctProtVal "Commanded Axle Torque Predicted Protection Value";
BA_ "VNSigAllNodes" SG_ 170 CmndAxlTrqPredctProtVal 1;
BA_ "SignalType" SG_ 1221 SpdLmtVsnFsdSpdUnt "ENM";
BA_ "SignalLongName" SG_ 1221 SpdLmtVsnFsdSpdUnt "Speed Limit Vision Fused Speed Unit";
BA_ "VNSigAllNodes" SG_ 1221 SpdLmtVsnFsdSpdUnt 1;
BA_ "SignalType" SG_ 1221 SpdLmtVnFsSpdNwDet "BLN";
BA_ "SignalLongName" SG_ 1221 SpdLmtVnFsSpdNwDet "Speed Limit Vision Fused Speed New Detected";
BA_ "VNSigAllNodes" SG_ 1221 SpdLmtVnFsSpdNwDet 1;
BA_ "SignalType" SG_ 1221 SpdLmtVsnFsdSpdM "ENM";
BA_ "SignalLongName" SG_ 1221 SpdLmtVsnFsdSpdM "Speed Limit Vision Fused Speed Mask";
BA_ "VNSigAllNodes" SG_ 1221 SpdLmtVsnFsdSpdM 1;
BA_ "SignalType" SG_ 1221 SpdLmtVsnFsdSpd "UNM";
BA_ "SignalLongName" SG_ 1221 SpdLmtVsnFsdSpd "Speed Limit Vision Fused Speed";
BA_ "VNSigAllNodes" SG_ 1221 SpdLmtVsnFsdSpd 1;
BA_ "SignalType" SG_ 1221 CCClntCrcFlwRtReq "UNM";
BA_ "SignalLongName" SG_ 1221 CCClntCrcFlwRtReq "Climate Control Coolant Circulation Flow Rate Request";
BA_ "VNSigAllNodes" SG_ 1221 CCClntCrcFlwRtReq 1;
BA_ "SignalType" SG_ 1221 PFFanSpdPrcntRq "UNM";
BA_ "SignalLongName" SG_ 1221 PFFanSpdPrcntRq "Platform Fan Speed Percent Request";
BA_ "VNSigAllNodes" SG_ 1221 PFFanSpdPrcntRq 1;
BA_ "SignalType" SG_ 1243 CSERDTC_CdNum "UNM";
BA_ "SignalLongName" SG_ 1243 CSERDTC_CdNum "Chassis System Emissions Related DTC : Code Number";
BA_ "VNSigAllNodes" SG_ 1243 CSERDTC_CdNum 1;
BA_ "SignalType" SG_ 1243 CSERDTC_SysDes "ENM";
BA_ "PacketOrder" SG_ 1243 CSERDTC_SysDes 1;
BA_ "SignalLongName" SG_ 1243 CSERDTC_SysDes "Chassis System Emissions Related DTC : System Designator";
BA_ "VNSigAllNodes" SG_ 1243 CSERDTC_SysDes 1;
BA_ "SignalType" SG_ 1243 ChsSysEmmRelMalfAct "BLN";
BA_ "SignalLongName" SG_ 1243 ChsSysEmmRelMalfAct "Chassis System Emissions Related Malfunction Active";
BA_ "VNSigAllNodes" SG_ 1243 ChsSysEmmRelMalfAct 1;
BA_ "SignalType" SG_ 979 PTABR_AccReq "SNM";
BA_ "PacketOrder" SG_ 979 PTABR_AccReq 2;
BA_ "SignalLongName" SG_ 979 PTABR_AccReq "Powertrain Automatic Braking Request : Acceleration Request";
BA_ "VNSigAllNodes" SG_ 979 PTABR_AccReq 1;
BA_ "SignalType" SG_ 979 PTABR_PTBrkRqAct "BLN";
BA_ "PacketOrder" SG_ 979 PTABR_PTBrkRqAct 1;
BA_ "SignalLongName" SG_ 979 PTABR_PTBrkRqAct "Powertrain Automatic Braking Request : Powertrain Brake Request Active";
BA_ "VNSigAllNodes" SG_ 979 PTABR_PTBrkRqAct 1;
BA_ "SignalType" SG_ 979 PTAutoBrkReqPVal "UNM";
BA_ "SignalLongName" SG_ 979 PTAutoBrkReqPVal "Powertrain Automatic Braking Request Protection Value";
BA_ "VNSigAllNodes" SG_ 979 PTAutoBrkReqPVal 1;
BA_ "SignalType" SG_ 979 PTAutoBrkReqARC "UNM";
BA_ "SignalLongName" SG_ 979 PTAutoBrkReqARC "Powertrain Automatic Braking Request Alive Rolling Count";
BA_ "VNSigAllNodes" SG_ 979 PTAutoBrkReqARC 1;
BA_ "SignalType" SG_ 979 BrkBstVacV "ENM";
BA_ "SignalLongName" SG_ 979 BrkBstVacV "Brake Boost Vacuum Validity";
BA_ "VNSigAllNodes" SG_ 979 BrkBstVacV 1;
BA_ "SignalType" SG_ 979 BrkBstVac "UNM";
BA_ "SignalLongName" SG_ 979 BrkBstVac "Brake Boost Vacuum";
BA_ "VNSigAllNodes" SG_ 979 BrkBstVac 1;
BA_ "SignalType" SG_ 979 EngManfldAirTmpV "ENM";
BA_ "SignalLongName" SG_ 979 EngManfldAirTmpV "Engine Manifold Air Temperature Validity";
BA_ "VNSigAllNodes" SG_ 979 EngManfldAirTmpV 1;
BA_ "SignalType" SG_ 979 EngManfldAirTmp "UNM";
BA_ "SignalLongName" SG_ 979 EngManfldAirTmp "Engine Manifold Air Temperature";
BA_ "VNSigAllNodes" SG_ 979 EngManfldAirTmp 1;
BA_ "SignalType" SG_ 546 ThrmlRfCmprElctrCrntV "ENM";
BA_ "SignalLongName" SG_ 546 ThrmlRfCmprElctrCrntV "Thermal Refrigerant Compressor Electrical Current Validity";
BA_ "VNSigAllNodes" SG_ 546 ThrmlRfCmprElctrCrntV 1;
BA_ "SignalType" SG_ 546 ThrmlRfCmprElctrCrnt "UNM";
BA_ "SignalLongName" SG_ 546 ThrmlRfCmprElctrCrnt "Thermal Refrigerant Compressor Electrical Current";
BA_ "VNSigAllNodes" SG_ 546 ThrmlRfCmprElctrCrnt 1;
BA_ "SignalType" SG_ 546 ThrmlRefCompStat "ENM";
BA_ "SignalLongName" SG_ 546 ThrmlRefCompStat "Thermal Refrigerant Compressor Status";
BA_ "VNSigAllNodes" SG_ 546 ThrmlRefCompStat 1;
BA_ "SignalType" SG_ 546 ThrmlRefCompSpdV "ENM";
BA_ "SignalLongName" SG_ 546 ThrmlRefCompSpdV "Thermal Refrigerant Compressor Speed Validity";
BA_ "VNSigAllNodes" SG_ 546 ThrmlRefCompSpdV 1;
BA_ "SignalType" SG_ 546 ThrmlRefCompSpd "UNM";
BA_ "SignalLongName" SG_ 546 ThrmlRefCompSpd "Thermal Refrigerant Compressor Speed";
BA_ "VNSigAllNodes" SG_ 546 ThrmlRefCompSpd 1;
BA_ "SignalType" SG_ 546 ThrmlRfCmpOvTmpFltPr "BLN";
BA_ "SignalLongName" SG_ 546 ThrmlRfCmpOvTmpFltPr "Thermal Refrigerant Compressor Over Temperature Fault Present";
BA_ "VNSigAllNodes" SG_ 546 ThrmlRfCmpOvTmpFltPr 1;
BA_ "SignalType" SG_ 546 ThrmlRefCompElecPwrV "ENM";
BA_ "SignalLongName" SG_ 546 ThrmlRefCompElecPwrV "Thermal Refrigerant Compressor Electrical Power Validity";
BA_ "VNSigAllNodes" SG_ 546 ThrmlRefCompElecPwrV 1;
BA_ "SignalType" SG_ 546 ThrmlRefCompElecPwr "UNM";
BA_ "SignalLongName" SG_ 546 ThrmlRefCompElecPwr "Thermal Refrigerant Compressor Electrical Power";
BA_ "VNSigAllNodes" SG_ 546 ThrmlRefCompElecPwr 1;
BA_ "SignalType" SG_ 530 RstVTDTmprDtctd "ENM";
BA_ "SignalLongName" SG_ 530 RstVTDTmprDtctd "Reset Vehicle Theft Deterrent Tamper Detected";
BA_ "VNSigAllNodes" SG_ 530 RstVTDTmprDtctd 1;
BA_ "SignalType" SG_ 530 RstIllDrIdDevDtctd "ENM";
BA_ "SignalLongName" SG_ 530 RstIllDrIdDevDtctd "Reset Illegitimate Driver Identification Device Detected";
BA_ "VNSigAllNodes" SG_ 530 RstIllDrIdDevDtctd 1;
BA_ "SignalType" SG_ 530 RstDrIdDevLrnd "ENM";
BA_ "SignalLongName" SG_ 530 RstDrIdDevLrnd "Reset Driver Identification Device Learned";
BA_ "VNSigAllNodes" SG_ 530 RstDrIdDevLrnd 1;
BA_ "SignalType" SG_ 1239 IntlgntBattSnsBattSOC "UNM";
BA_ "SignalLongName" SG_ 1239 IntlgntBattSnsBattSOC "Intelligent Battery Sensor Battery State of Charge";
BA_ "VNSigAllNodes" SG_ 1239 IntlgntBattSnsBattSOC 1;
BA_ "SignalType" SG_ 1239 BattTemp "UNM";
BA_ "SignalLongName" SG_ 1239 BattTemp "Battery Temperature";
BA_ "VNSigAllNodes" SG_ 1239 BattTemp 1;
BA_ "SignalType" SG_ 1239 BatSOH "UNM";
BA_ "SignalLongName" SG_ 1239 BatSOH "Battery State Of Health";
BA_ "VNSigAllNodes" SG_ 1239 BatSOH 1;
BA_ "SignalType" SG_ 1239 BatSOFVolt "UNM";
BA_ "SignalLongName" SG_ 1239 BatSOFVolt "Battery State Of Function Voltage";
BA_ "VNSigAllNodes" SG_ 1239 BatSOFVolt 1;
BA_ "SignalType" SG_ 1239 BattSOXStat "ENM";
BA_ "SignalLongName" SG_ 1239 BattSOXStat "Battery SOX Status";
BA_ "VNSigAllNodes" SG_ 1239 BattSOXStat 1;
BA_ "SignalType" SG_ 1239 BattTempV "ENM";
BA_ "SignalLongName" SG_ 1239 BattTempV "Battery Temperature Validity";
BA_ "VNSigAllNodes" SG_ 1239 BattTempV 1;
BA_ "VNSigSLHSSharedDiagnostic" SG_ 1610 DgnInf 1;
BA_ "SignalType" SG_ 1610 DgnInf "UNM";
BA_ "SignalLongName" SG_ 1610 DgnInf "Diagnostic Information";
BA_ "VNSigAllNodes" SG_ 1610 DgnInf 1;
BA_ "SignalType" SG_ 1027 FCO4D_ObjVertVar "SNM";
BA_ "PacketOrder" SG_ 1027 FCO4D_ObjVertVar 8;
BA_ "SignalLongName" SG_ 1027 FCO4D_ObjVertVar "Forward Camera Object 4 Detected : Object Vertical Variance";
BA_ "VNSigAllNodes" SG_ 1027 FCO4D_ObjVertVar 1;
BA_ "SignalType" SG_ 1027 FCO4D_ObjVertPos "SNM";
BA_ "PacketOrder" SG_ 1027 FCO4D_ObjVertPos 7;
BA_ "SignalLongName" SG_ 1027 FCO4D_ObjVertPos "Forward Camera Object 4 Detected : Object Vertical Position";
BA_ "VNSigAllNodes" SG_ 1027 FCO4D_ObjVertPos 1;
BA_ "SignalType" SG_ 1027 FCO4D_ObjTyp "ENM";
BA_ "PacketOrder" SG_ 1027 FCO4D_ObjTyp 3;
BA_ "SignalLongName" SG_ 1027 FCO4D_ObjTyp "Forward Camera Object 4 Detected : Object Type";
BA_ "VNSigAllNodes" SG_ 1027 FCO4D_ObjTyp 1;
BA_ "PacketOrder" SG_ 1027 FCO4D_ObjQlty 1;
BA_ "SignalType" SG_ 1027 FCO4D_ObjQlty "ENM";
BA_ "SignalLongName" SG_ 1027 FCO4D_ObjQlty "Forward Camera Object 4 Detected : Object Quality";
BA_ "VNSigAllNodes" SG_ 1027 FCO4D_ObjQlty 1;
BA_ "SignalType" SG_ 1027 FCO4D_ObjId "UNM";
BA_ "PacketOrder" SG_ 1027 FCO4D_ObjId 2;
BA_ "SignalLongName" SG_ 1027 FCO4D_ObjId "Forward Camera Object 4 Detected : Object ID";
BA_ "VNSigAllNodes" SG_ 1027 FCO4D_ObjId 1;
BA_ "SignalType" SG_ 1027 FCO4D_ObjHorzPos "SNM";
BA_ "PacketOrder" SG_ 1027 FCO4D_ObjHorzPos 4;
BA_ "SignalLongName" SG_ 1027 FCO4D_ObjHorzPos "Forward Camera Object 4 Detected : Object Horizontal Position";
BA_ "VNSigAllNodes" SG_ 1027 FCO4D_ObjHorzPos 1;
BA_ "SignalType" SG_ 1027 FCO4D_ObjHorzDim "UNM";
BA_ "PacketOrder" SG_ 1027 FCO4D_ObjHorzDim 6;
BA_ "SignalLongName" SG_ 1027 FCO4D_ObjHorzDim "Forward Camera Object 4 Detected : Object Horizontal Dimension";
BA_ "VNSigAllNodes" SG_ 1027 FCO4D_ObjHorzDim 1;
BA_ "SignalType" SG_ 1027 FCO4D_ObjDist "UNM";
BA_ "PacketOrder" SG_ 1027 FCO4D_ObjDist 9;
BA_ "SignalLongName" SG_ 1027 FCO4D_ObjDist "Forward Camera Object 4 Detected : Object Distance";
BA_ "VNSigAllNodes" SG_ 1027 FCO4D_ObjDist 1;
BA_ "SignalType" SG_ 1027 FCO4D_DetMthd "ENM";
BA_ "PacketOrder" SG_ 1027 FCO4D_DetMthd 5;
BA_ "SignalLongName" SG_ 1027 FCO4D_DetMthd "Forward Camera Object 4 Detected : Detection Method";
BA_ "VNSigAllNodes" SG_ 1027 FCO4D_DetMthd 1;
BA_ "SignalType" SG_ 1026 FCO3D_ObjVertVar "SNM";
BA_ "PacketOrder" SG_ 1026 FCO3D_ObjVertVar 8;
BA_ "SignalLongName" SG_ 1026 FCO3D_ObjVertVar "Forward Camera Object 3 Detected : Object Vertical Variance";
BA_ "VNSigAllNodes" SG_ 1026 FCO3D_ObjVertVar 1;
BA_ "SignalType" SG_ 1026 FCO3D_ObjVertPos "SNM";
BA_ "PacketOrder" SG_ 1026 FCO3D_ObjVertPos 7;
BA_ "SignalLongName" SG_ 1026 FCO3D_ObjVertPos "Forward Camera Object 3 Detected : Object Vertical Position";
BA_ "VNSigAllNodes" SG_ 1026 FCO3D_ObjVertPos 1;
BA_ "PacketOrder" SG_ 1026 FCO3D_ObjQlty 1;
BA_ "SignalType" SG_ 1026 FCO3D_ObjQlty "ENM";
BA_ "SignalLongName" SG_ 1026 FCO3D_ObjQlty "Forward Camera Object 3 Detected : Object Quality";
BA_ "VNSigAllNodes" SG_ 1026 FCO3D_ObjQlty 1;
BA_ "SignalType" SG_ 1026 FCO3D_ObjDist "UNM";
BA_ "PacketOrder" SG_ 1026 FCO3D_ObjDist 9;
BA_ "SignalLongName" SG_ 1026 FCO3D_ObjDist "Forward Camera Object 3 Detected : Object Distance";
BA_ "VNSigAllNodes" SG_ 1026 FCO3D_ObjDist 1;
BA_ "SignalType" SG_ 1026 FCO3D_DetMthd "ENM";
BA_ "PacketOrder" SG_ 1026 FCO3D_DetMthd 5;
BA_ "SignalLongName" SG_ 1026 FCO3D_DetMthd "Forward Camera Object 3 Detected : Detection Method";
BA_ "VNSigAllNodes" SG_ 1026 FCO3D_DetMthd 1;
BA_ "SignalType" SG_ 1026 FCO3D_ObjHorzPos "SNM";
BA_ "PacketOrder" SG_ 1026 FCO3D_ObjHorzPos 4;
BA_ "SignalLongName" SG_ 1026 FCO3D_ObjHorzPos "Forward Camera Object 3 Detected : Object Horizontal Position";
BA_ "VNSigAllNodes" SG_ 1026 FCO3D_ObjHorzPos 1;
BA_ "SignalType" SG_ 1026 FCO3D_ObjHorzDim "UNM";
BA_ "PacketOrder" SG_ 1026 FCO3D_ObjHorzDim 6;
BA_ "SignalLongName" SG_ 1026 FCO3D_ObjHorzDim "Forward Camera Object 3 Detected : Object Horizontal Dimension";
BA_ "VNSigAllNodes" SG_ 1026 FCO3D_ObjHorzDim 1;
BA_ "SignalType" SG_ 1026 FCO3D_ObjTyp "ENM";
BA_ "PacketOrder" SG_ 1026 FCO3D_ObjTyp 3;
BA_ "SignalLongName" SG_ 1026 FCO3D_ObjTyp "Forward Camera Object 3 Detected : Object Type";
BA_ "VNSigAllNodes" SG_ 1026 FCO3D_ObjTyp 1;
BA_ "SignalType" SG_ 1026 FCO3D_ObjId "UNM";
BA_ "PacketOrder" SG_ 1026 FCO3D_ObjId 2;
BA_ "SignalLongName" SG_ 1026 FCO3D_ObjId "Forward Camera Object 3 Detected : Object ID";
BA_ "VNSigAllNodes" SG_ 1026 FCO3D_ObjId 1;
BA_ "PacketOrder" SG_ 1025 FCO2D_ObjQlty 2;
BA_ "SignalType" SG_ 1025 FCO2D_ObjQlty "ENM";
BA_ "SignalLongName" SG_ 1025 FCO2D_ObjQlty "Forward Camera Object 2 Detected : Object Quality";
BA_ "VNSigAllNodes" SG_ 1025 FCO2D_ObjQlty 1;
BA_ "SignalType" SG_ 1025 FCO2D_ObjDist "UNM";
BA_ "PacketOrder" SG_ 1025 FCO2D_ObjDist 9;
BA_ "SignalLongName" SG_ 1025 FCO2D_ObjDist "Forward Camera Object 2 Detected : Object Distance";
BA_ "VNSigAllNodes" SG_ 1025 FCO2D_ObjDist 1;
BA_ "SignalType" SG_ 1025 FCO2D_ObjVertVar "SNM";
BA_ "PacketOrder" SG_ 1025 FCO2D_ObjVertVar 8;
BA_ "SignalLongName" SG_ 1025 FCO2D_ObjVertVar "Forward Camera Object 2 Detected : Object Vertical Variance";
BA_ "VNSigAllNodes" SG_ 1025 FCO2D_ObjVertVar 1;
BA_ "SignalType" SG_ 1025 FCO2D_ObjVertPos "SNM";
BA_ "PacketOrder" SG_ 1025 FCO2D_ObjVertPos 7;
BA_ "SignalLongName" SG_ 1025 FCO2D_ObjVertPos "Forward Camera Object 2 Detected : Object Vertical Position";
BA_ "VNSigAllNodes" SG_ 1025 FCO2D_ObjVertPos 1;
BA_ "SignalType" SG_ 1025 FCO2D_ObjHorzDim "UNM";
BA_ "PacketOrder" SG_ 1025 FCO2D_ObjHorzDim 6;
BA_ "SignalLongName" SG_ 1025 FCO2D_ObjHorzDim "Forward Camera Object 2 Detected : Object Horizontal Dimension";
BA_ "VNSigAllNodes" SG_ 1025 FCO2D_ObjHorzDim 1;
BA_ "SignalType" SG_ 1025 FCO2D_DetMthd "ENM";
BA_ "PacketOrder" SG_ 1025 FCO2D_DetMthd 5;
BA_ "SignalLongName" SG_ 1025 FCO2D_DetMthd "Forward Camera Object 2 Detected : Detection Method";
BA_ "VNSigAllNodes" SG_ 1025 FCO2D_DetMthd 1;
BA_ "SignalType" SG_ 1025 FCO2D_ObjHorzPos "SNM";
BA_ "PacketOrder" SG_ 1025 FCO2D_ObjHorzPos 4;
BA_ "SignalLongName" SG_ 1025 FCO2D_ObjHorzPos "Forward Camera Object 2 Detected : Object Horizontal Position";
BA_ "VNSigAllNodes" SG_ 1025 FCO2D_ObjHorzPos 1;
BA_ "SignalType" SG_ 1025 FCO2D_ObjTyp "ENM";
BA_ "PacketOrder" SG_ 1025 FCO2D_ObjTyp 3;
BA_ "SignalLongName" SG_ 1025 FCO2D_ObjTyp "Forward Camera Object 2 Detected : Object Type";
BA_ "VNSigAllNodes" SG_ 1025 FCO2D_ObjTyp 1;
BA_ "PacketOrder" SG_ 1025 FCO2D_ObjId 2;
BA_ "SignalType" SG_ 1025 FCO2D_ObjId "UNM";
BA_ "SignalLongName" SG_ 1025 FCO2D_ObjId "Forward Camera Object 2 Detected : Object ID";
BA_ "VNSigAllNodes" SG_ 1025 FCO2D_ObjId 1;
BA_ "SignalType" SG_ 1024 FCO1D_ObjQlty "ENM";
BA_ "PacketOrder" SG_ 1024 FCO1D_ObjQlty 1;
BA_ "SignalLongName" SG_ 1024 FCO1D_ObjQlty "Forward Camera Object 1 Detected : Object Quality";
BA_ "VNSigAllNodes" SG_ 1024 FCO1D_ObjQlty 1;
BA_ "SignalType" SG_ 1024 FCO1D_ObjDist "UNM";
BA_ "PacketOrder" SG_ 1024 FCO1D_ObjDist 9;
BA_ "SignalLongName" SG_ 1024 FCO1D_ObjDist "Forward Camera Object 1 Detected : Object Distance";
BA_ "VNSigAllNodes" SG_ 1024 FCO1D_ObjDist 1;
BA_ "SignalType" SG_ 1024 FCO1D_ObjVertVar "SNM";
BA_ "PacketOrder" SG_ 1024 FCO1D_ObjVertVar 8;
BA_ "SignalLongName" SG_ 1024 FCO1D_ObjVertVar "Forward Camera Object 1 Detected : Object Vertical Variance";
BA_ "VNSigAllNodes" SG_ 1024 FCO1D_ObjVertVar 1;
BA_ "SignalType" SG_ 1024 FCO1D_ObjVertPos "SNM";
BA_ "PacketOrder" SG_ 1024 FCO1D_ObjVertPos 7;
BA_ "SignalLongName" SG_ 1024 FCO1D_ObjVertPos "Forward Camera Object 1 Detected : Object Vertical Position";
BA_ "VNSigAllNodes" SG_ 1024 FCO1D_ObjVertPos 1;
BA_ "SignalType" SG_ 1024 FCO1D_ObjHorzDim "UNM";
BA_ "PacketOrder" SG_ 1024 FCO1D_ObjHorzDim 4;
BA_ "SignalLongName" SG_ 1024 FCO1D_ObjHorzDim "Forward Camera Object 1 Detected : Object Horizontal Dimension";
BA_ "VNSigAllNodes" SG_ 1024 FCO1D_ObjHorzDim 1;
BA_ "SignalType" SG_ 1024 FCO1D_DetMthd "ENM";
BA_ "PacketOrder" SG_ 1024 FCO1D_DetMthd 6;
BA_ "SignalLongName" SG_ 1024 FCO1D_DetMthd "Forward Camera Object 1 Detected : Detection Method";
BA_ "VNSigAllNodes" SG_ 1024 FCO1D_DetMthd 1;
BA_ "PacketOrder" SG_ 1024 FCO1D_ObjHorzPos 1;
BA_ "SignalType" SG_ 1024 FCO1D_ObjHorzPos "SNM";
BA_ "SignalLongName" SG_ 1024 FCO1D_ObjHorzPos "Forward Camera Object 1 Detected : Object Horizontal Position";
BA_ "VNSigAllNodes" SG_ 1024 FCO1D_ObjHorzPos 1;
BA_ "SignalType" SG_ 1024 FCO1D_ObjTyp "ENM";
BA_ "PacketOrder" SG_ 1024 FCO1D_ObjTyp 5;
BA_ "SignalLongName" SG_ 1024 FCO1D_ObjTyp "Forward Camera Object 1 Detected : Object Type";
BA_ "VNSigAllNodes" SG_ 1024 FCO1D_ObjTyp 1;
BA_ "SignalType" SG_ 1024 FCO1D_ObjId "UNM";
BA_ "PacketOrder" SG_ 1024 FCO1D_ObjId 2;
BA_ "SignalLongName" SG_ 1024 FCO1D_ObjId "Forward Camera Object 1 Detected : Object ID";
BA_ "VNSigAllNodes" SG_ 1024 FCO1D_ObjId 1;
BA_ "SignalType" SG_ 508 LonLatAccSnsChk "UNM";
BA_ "SignalLongName" SG_ 508 LonLatAccSnsChk "Longitudinal/Lateral Acceleration Sensor Checksum";
BA_ "VNSigAllNodes" SG_ 508 LonLatAccSnsChk 1;
BA_ "SignalType" SG_ 508 LonLatAccSnsValARC "UNM";
BA_ "SignalLongName" SG_ 508 LonLatAccSnsValARC "Longitudinal/Lateral Acceleration Sensor Value Alive Rolling Count";
BA_ "VNSigAllNodes" SG_ 508 LonLatAccSnsValARC 1;
BA_ "SignalType" SG_ 508 LatAccSnsVal "SNM";
BA_ "SignalLongName" SG_ 508 LatAccSnsVal "Lateral Acceleration Sensor Value";
BA_ "VNSigAllNodes" SG_ 508 LatAccSnsVal 1;
BA_ "SignalType" SG_ 508 LonAccSnsVal "SNM";
BA_ "SignalLongName" SG_ 508 LonAccSnsVal "Longitudinal Acceleration Sensor Value";
BA_ "VNSigAllNodes" SG_ 508 LonAccSnsVal 1;
BA_ "SignalType" SG_ 508 CSTBATS_TrqVl "UNM";
BA_ "PacketOrder" SG_ 508 CSTBATS_TrqVl 2;
BA_ "SignalLongName" SG_ 508 CSTBATS_TrqVl "Chassis System Total Brake Axle Torque Status : Torque Value";
BA_ "VNSigAllNodes" SG_ 508 CSTBATS_TrqVl 1;
BA_ "SignalType" SG_ 508 CSTBATS_TrqVlV "ENM";
BA_ "PacketOrder" SG_ 508 CSTBATS_TrqVlV 1;
BA_ "SignalLongName" SG_ 508 CSTBATS_TrqVlV "Chassis System Total Brake Axle Torque Status : Torque Value Validity";
BA_ "VNSigAllNodes" SG_ 508 CSTBATS_TrqVlV 1;
BA_ "SignalType" SG_ 422 TrStPTGrdBrkDsMdOvr "ENM";
BA_ "SignalLongName" SG_ 422 TrStPTGrdBrkDsMdOvr "Transmission State Powertrain Grade Braking  Disable Mode Override";
BA_ "VNSigAllNodes" SG_ 422 TrStPTGrdBrkDsMdOvr 1;
BA_ "SignalType" SG_ 422 TrnsHybEngSrtStpOvrd "ENM";
BA_ "SignalLongName" SG_ 422 TrnsHybEngSrtStpOvrd "Transmission Hybrid Engine Start Stop Override";
BA_ "VNSigAllNodes" SG_ 422 TrnsHybEngSrtStpOvrd 1;
BA_REL_ "GenSigSuprvResp" BU_SG_REL_ HCP_HS SG_ 901 TrnsMtrBCoolFlwEst 1;
BA_REL_ "GenSigTimeoutMsg" BU_SG_REL_ HCP_HS SG_ 901 TrnsMtrBCoolFlwEst 901;
BA_REL_ "GenSigTimeoutTime" BU_SG_REL_ HCP_HS SG_ 901 TrnsMtrBCoolFlwEst 250;
BA_REL_ "GenSigSuprvResp" BU_SG_REL_ HCP_HS SG_ 901 TrnsMtrACoolFlwEst 1;
BA_REL_ "GenSigTimeoutMsg" BU_SG_REL_ HCP_HS SG_ 901 TrnsMtrACoolFlwEst 901;
BA_REL_ "GenSigTimeoutTime" BU_SG_REL_ HCP_HS SG_ 901 TrnsMtrACoolFlwEst 250;
BA_REL_ "GenSigSuprvResp" BU_SG_REL_ HCP_HS SG_ 901 TrnsLubeFlwEst 1;
BA_REL_ "GenSigTimeoutMsg" BU_SG_REL_ HCP_HS SG_ 901 TrnsLubeFlwEst 901;
BA_REL_ "GenSigTimeoutTime" BU_SG_REL_ HCP_HS SG_ 901 TrnsLubeFlwEst 250;
BA_REL_ "GenSigSuprvResp" BU_SG_REL_ AHL_AFL_HS SG_ 1032 RdTyp 1;
BA_REL_ "GenSigTimeoutMsg" BU_SG_REL_ AHL_AFL_HS SG_ 1032 RdTyp 1032;
BA_REL_ "GenSigTimeoutTime" BU_SG_REL_ AHL_AFL_HS SG_ 1032 RdTyp 250;
BA_REL_ "GenSigSuprvResp" BU_SG_REL_ AHL_AFL_HS SG_ 1032 FwdCamSysOpStat 1;
BA_REL_ "GenSigTimeoutMsg" BU_SG_REL_ AHL_AFL_HS SG_ 1032 FwdCamSysOpStat 1032;
BA_REL_ "GenSigTimeoutTime" BU_SG_REL_ AHL_AFL_HS SG_ 1032 FwdCamSysOpStat 250;
BA_REL_ "GenSigSuprvResp" BU_SG_REL_ AHL_AFL_HS SG_ 1032 EnvIllum 1;
BA_REL_ "GenSigTimeoutMsg" BU_SG_REL_ AHL_AFL_HS SG_ 1032 EnvIllum 1032;
BA_REL_ "GenSigTimeoutTime" BU_SG_REL_ AHL_AFL_HS SG_ 1032 EnvIllum 250;
BA_REL_ "GenSigSuprvResp" BU_SG_REL_ AHL_AFL_HS SG_ 1032 AutoHgBmSts 1;
BA_REL_ "GenSigTimeoutMsg" BU_SG_REL_ AHL_AFL_HS SG_ 1032 AutoHgBmSts 1032;
BA_REL_ "GenSigTimeoutTime" BU_SG_REL_ AHL_AFL_HS SG_ 1032 AutoHgBmSts 250;
BA_REL_ "GenSigSuprvResp" BU_SG_REL_ AHL_AFL_HS SG_ 1031 FCO8D_ObjVertVar 1;
BA_REL_ "GenSigTimeoutMsg" BU_SG_REL_ AHL_AFL_HS SG_ 1031 FCO8D_ObjVertVar 1031;
BA_REL_ "GenSigTimeoutTime" BU_SG_REL_ AHL_AFL_HS SG_ 1031 FCO8D_ObjVertVar 250;
BA_REL_ "GenSigSuprvResp" BU_SG_REL_ AHL_AFL_HS SG_ 1031 FCO8D_ObjVertPos 1;
BA_REL_ "GenSigTimeoutMsg" BU_SG_REL_ AHL_AFL_HS SG_ 1031 FCO8D_ObjVertPos 1031;
BA_REL_ "GenSigTimeoutTime" BU_SG_REL_ AHL_AFL_HS SG_ 1031 FCO8D_ObjVertPos 250;
BA_REL_ "GenSigSuprvResp" BU_SG_REL_ AHL_AFL_HS SG_ 1031 FCO8D_ObjTyp 1;
BA_REL_ "GenSigTimeoutMsg" BU_SG_REL_ AHL_AFL_HS SG_ 1031 FCO8D_ObjTyp 1031;
BA_REL_ "GenSigTimeoutTime" BU_SG_REL_ AHL_AFL_HS SG_ 1031 FCO8D_ObjTyp 250;
BA_REL_ "GenSigSuprvResp" BU_SG_REL_ AHL_AFL_HS SG_ 1031 FCO8D_ObjQlty 1;
BA_REL_ "GenSigTimeoutMsg" BU_SG_REL_ AHL_AFL_HS SG_ 1031 FCO8D_ObjQlty 1031;
BA_REL_ "GenSigTimeoutTime" BU_SG_REL_ AHL_AFL_HS SG_ 1031 FCO8D_ObjQlty 250;
BA_REL_ "GenSigSuprvResp" BU_SG_REL_ AHL_AFL_HS SG_ 1031 FCO8D_ObjId 1;
BA_REL_ "GenSigTimeoutMsg" BU_SG_REL_ AHL_AFL_HS SG_ 1031 FCO8D_ObjId 1031;
BA_REL_ "GenSigTimeoutTime" BU_SG_REL_ AHL_AFL_HS SG_ 1031 FCO8D_ObjId 250;
BA_REL_ "GenSigSuprvResp" BU_SG_REL_ AHL_AFL_HS SG_ 1031 FCO8D_ObjHorzPos 1;
BA_REL_ "GenSigTimeoutMsg" BU_SG_REL_ AHL_AFL_HS SG_ 1031 FCO8D_ObjHorzPos 1031;
BA_REL_ "GenSigTimeoutTime" BU_SG_REL_ AHL_AFL_HS SG_ 1031 FCO8D_ObjHorzPos 250;
BA_REL_ "GenSigSuprvResp" BU_SG_REL_ AHL_AFL_HS SG_ 1031 FCO8D_ObjHorzDim 1;
BA_REL_ "GenSigTimeoutMsg" BU_SG_REL_ AHL_AFL_HS SG_ 1031 FCO8D_ObjHorzDim 1031;
BA_REL_ "GenSigTimeoutTime" BU_SG_REL_ AHL_AFL_HS SG_ 1031 FCO8D_ObjHorzDim 250;
BA_REL_ "GenSigSuprvResp" BU_SG_REL_ AHL_AFL_HS SG_ 1031 FCO8D_ObjDist 1;
BA_REL_ "GenSigTimeoutMsg" BU_SG_REL_ AHL_AFL_HS SG_ 1031 FCO8D_ObjDist 1031;
BA_REL_ "GenSigTimeoutTime" BU_SG_REL_ AHL_AFL_HS SG_ 1031 FCO8D_ObjDist 250;
BA_REL_ "GenSigSuprvResp" BU_SG_REL_ AHL_AFL_HS SG_ 1031 FCO8D_DetMthd 1;
BA_REL_ "GenSigTimeoutMsg" BU_SG_REL_ AHL_AFL_HS SG_ 1031 FCO8D_DetMthd 1031;
BA_REL_ "GenSigTimeoutTime" BU_SG_REL_ AHL_AFL_HS SG_ 1031 FCO8D_DetMthd 250;
BA_REL_ "GenSigSuprvResp" BU_SG_REL_ AHL_AFL_HS SG_ 1030 FCO7D_ObjVertVar 1;
BA_REL_ "GenSigTimeoutMsg" BU_SG_REL_ AHL_AFL_HS SG_ 1030 FCO7D_ObjVertVar 1030;
BA_REL_ "GenSigTimeoutTime" BU_SG_REL_ AHL_AFL_HS SG_ 1030 FCO7D_ObjVertVar 250;
BA_REL_ "GenSigSuprvResp" BU_SG_REL_ AHL_AFL_HS SG_ 1030 FCO7D_ObjVertPos 1;
BA_REL_ "GenSigTimeoutMsg" BU_SG_REL_ AHL_AFL_HS SG_ 1030 FCO7D_ObjVertPos 1030;
BA_REL_ "GenSigTimeoutTime" BU_SG_REL_ AHL_AFL_HS SG_ 1030 FCO7D_ObjVertPos 250;
BA_REL_ "GenSigSuprvResp" BU_SG_REL_ AHL_AFL_HS SG_ 1030 FCO7D_ObjTyp 1;
BA_REL_ "GenSigTimeoutMsg" BU_SG_REL_ AHL_AFL_HS SG_ 1030 FCO7D_ObjTyp 1030;
BA_REL_ "GenSigTimeoutTime" BU_SG_REL_ AHL_AFL_HS SG_ 1030 FCO7D_ObjTyp 250;
BA_REL_ "GenSigSuprvResp" BU_SG_REL_ AHL_AFL_HS SG_ 1030 FCO7D_ObjQlty 1;
BA_REL_ "GenSigTimeoutMsg" BU_SG_REL_ AHL_AFL_HS SG_ 1030 FCO7D_ObjQlty 1030;
BA_REL_ "GenSigTimeoutTime" BU_SG_REL_ AHL_AFL_HS SG_ 1030 FCO7D_ObjQlty 250;
BA_REL_ "GenSigSuprvResp" BU_SG_REL_ AHL_AFL_HS SG_ 1030 FCO7D_ObjId 1;
BA_REL_ "GenSigTimeoutMsg" BU_SG_REL_ AHL_AFL_HS SG_ 1030 FCO7D_ObjId 1030;
BA_REL_ "GenSigTimeoutTime" BU_SG_REL_ AHL_AFL_HS SG_ 1030 FCO7D_ObjId 250;
BA_REL_ "GenSigSuprvResp" BU_SG_REL_ AHL_AFL_HS SG_ 1030 FCO7D_ObjHorzPos 1;
BA_REL_ "GenSigTimeoutMsg" BU_SG_REL_ AHL_AFL_HS SG_ 1030 FCO7D_ObjHorzPos 1030;
BA_REL_ "GenSigTimeoutTime" BU_SG_REL_ AHL_AFL_HS SG_ 1030 FCO7D_ObjHorzPos 250;
BA_REL_ "GenSigSuprvResp" BU_SG_REL_ AHL_AFL_HS SG_ 1030 FCO7D_ObjHorzDim 1;
BA_REL_ "GenSigTimeoutMsg" BU_SG_REL_ AHL_AFL_HS SG_ 1030 FCO7D_ObjHorzDim 1030;
BA_REL_ "GenSigTimeoutTime" BU_SG_REL_ AHL_AFL_HS SG_ 1030 FCO7D_ObjHorzDim 250;
BA_REL_ "GenSigSuprvResp" BU_SG_REL_ AHL_AFL_HS SG_ 1030 FCO7D_ObjDist 1;
BA_REL_ "GenSigTimeoutMsg" BU_SG_REL_ AHL_AFL_HS SG_ 1030 FCO7D_ObjDist 1030;
BA_REL_ "GenSigTimeoutTime" BU_SG_REL_ AHL_AFL_HS SG_ 1030 FCO7D_ObjDist 250;
BA_REL_ "GenSigSuprvResp" BU_SG_REL_ AHL_AFL_HS SG_ 1030 FCO7D_DetMthd 1;
BA_REL_ "GenSigTimeoutMsg" BU_SG_REL_ AHL_AFL_HS SG_ 1030 FCO7D_DetMthd 1030;
BA_REL_ "GenSigTimeoutTime" BU_SG_REL_ AHL_AFL_HS SG_ 1030 FCO7D_DetMthd 250;
BA_REL_ "GenSigSuprvResp" BU_SG_REL_ BCM_HS SG_ 479 ASIRI_Indication16 1;
BA_REL_ "GenSigTimeoutMsg" BU_SG_REL_ BCM_HS SG_ 479 ASIRI_Indication16 479;
BA_REL_ "GenSigTimeoutTime" BU_SG_REL_ BCM_HS SG_ 479 ASIRI_Indication16 250;
BA_REL_ "GenSigSuprvResp" BU_SG_REL_ BCM_HS SG_ 479 ASIRI_Indication15 1;
BA_REL_ "GenSigTimeoutMsg" BU_SG_REL_ BCM_HS SG_ 479 ASIRI_Indication15 479;
BA_REL_ "GenSigTimeoutTime" BU_SG_REL_ BCM_HS SG_ 479 ASIRI_Indication15 250;
BA_REL_ "GenSigSuprvResp" BU_SG_REL_ BCM_HS SG_ 479 ASIRI_Indication14 1;
BA_REL_ "GenSigTimeoutMsg" BU_SG_REL_ BCM_HS SG_ 479 ASIRI_Indication14 479;
BA_REL_ "GenSigTimeoutTime" BU_SG_REL_ BCM_HS SG_ 479 ASIRI_Indication14 250;
BA_REL_ "GenSigSuprvResp" BU_SG_REL_ BCM_HS SG_ 479 ASIRI_Indication13 1;
BA_REL_ "GenSigTimeoutMsg" BU_SG_REL_ BCM_HS SG_ 479 ASIRI_Indication13 479;
BA_REL_ "GenSigTimeoutTime" BU_SG_REL_ BCM_HS SG_ 479 ASIRI_Indication13 250;
BA_REL_ "GenSigSuprvResp" BU_SG_REL_ BCM_HS SG_ 479 ASIRI_Indication12 1;
BA_REL_ "GenSigTimeoutMsg" BU_SG_REL_ BCM_HS SG_ 479 ASIRI_Indication12 479;
BA_REL_ "GenSigTimeoutTime" BU_SG_REL_ BCM_HS SG_ 479 ASIRI_Indication12 250;
BA_REL_ "GenSigSuprvResp" BU_SG_REL_ BCM_HS SG_ 479 ASIRI_Indication11 1;
BA_REL_ "GenSigTimeoutMsg" BU_SG_REL_ BCM_HS SG_ 479 ASIRI_Indication11 479;
BA_REL_ "GenSigTimeoutTime" BU_SG_REL_ BCM_HS SG_ 479 ASIRI_Indication11 250;
BA_REL_ "GenSigSuprvResp" BU_SG_REL_ BCM_HS SG_ 479 ASIRI_Indication10 1;
BA_REL_ "GenSigTimeoutMsg" BU_SG_REL_ BCM_HS SG_ 479 ASIRI_Indication10 479;
BA_REL_ "GenSigTimeoutTime" BU_SG_REL_ BCM_HS SG_ 479 ASIRI_Indication10 250;
BA_REL_ "GenSigSuprvResp" BU_SG_REL_ BCM_HS SG_ 479 ASIRI_Indication09 1;
BA_REL_ "GenSigTimeoutMsg" BU_SG_REL_ BCM_HS SG_ 479 ASIRI_Indication09 479;
BA_REL_ "GenSigTimeoutTime" BU_SG_REL_ BCM_HS SG_ 479 ASIRI_Indication09 250;
BA_REL_ "GenSigSuprvResp" BU_SG_REL_ BCM_HS SG_ 479 ASIRI_Indication08 1;
BA_REL_ "GenSigTimeoutMsg" BU_SG_REL_ BCM_HS SG_ 479 ASIRI_Indication08 479;
BA_REL_ "GenSigTimeoutTime" BU_SG_REL_ BCM_HS SG_ 479 ASIRI_Indication08 250;
BA_REL_ "GenSigSuprvResp" BU_SG_REL_ BCM_HS SG_ 479 ASIRI_Indication07 1;
BA_REL_ "GenSigTimeoutMsg" BU_SG_REL_ BCM_HS SG_ 479 ASIRI_Indication07 479;
BA_REL_ "GenSigTimeoutTime" BU_SG_REL_ BCM_HS SG_ 479 ASIRI_Indication07 250;
BA_REL_ "GenSigSuprvResp" BU_SG_REL_ BCM_HS SG_ 479 ASIRI_Indication06 1;
BA_REL_ "GenSigTimeoutMsg" BU_SG_REL_ BCM_HS SG_ 479 ASIRI_Indication06 479;
BA_REL_ "GenSigTimeoutTime" BU_SG_REL_ BCM_HS SG_ 479 ASIRI_Indication06 250;
BA_REL_ "GenSigSuprvResp" BU_SG_REL_ BCM_HS SG_ 479 ASIRI_Indication05 1;
BA_REL_ "GenSigTimeoutMsg" BU_SG_REL_ BCM_HS SG_ 479 ASIRI_Indication05 479;
BA_REL_ "GenSigTimeoutTime" BU_SG_REL_ BCM_HS SG_ 479 ASIRI_Indication05 250;
BA_REL_ "GenSigSuprvResp" BU_SG_REL_ BCM_HS SG_ 479 ASIRI_Indication04 1;
BA_REL_ "GenSigTimeoutMsg" BU_SG_REL_ BCM_HS SG_ 479 ASIRI_Indication04 479;
BA_REL_ "GenSigTimeoutTime" BU_SG_REL_ BCM_HS SG_ 479 ASIRI_Indication04 250;
BA_REL_ "GenSigSuprvResp" BU_SG_REL_ BCM_HS SG_ 479 ASIRI_Indication03 1;
BA_REL_ "GenSigTimeoutMsg" BU_SG_REL_ BCM_HS SG_ 479 ASIRI_Indication03 479;
BA_REL_ "GenSigTimeoutTime" BU_SG_REL_ BCM_HS SG_ 479 ASIRI_Indication03 250;
BA_REL_ "GenSigSuprvResp" BU_SG_REL_ BCM_HS SG_ 479 ASIRI_Indication02 1;
BA_REL_ "GenSigTimeoutMsg" BU_SG_REL_ BCM_HS SG_ 479 ASIRI_Indication02 479;
BA_REL_ "GenSigTimeoutTime" BU_SG_REL_ BCM_HS SG_ 479 ASIRI_Indication02 250;
BA_REL_ "GenSigSuprvResp" BU_SG_REL_ BCM_HS SG_ 479 ASIRI_Indication01 1;
BA_REL_ "GenSigTimeoutMsg" BU_SG_REL_ BCM_HS SG_ 479 ASIRI_Indication01 479;
BA_REL_ "GenSigTimeoutTime" BU_SG_REL_ BCM_HS SG_ 479 ASIRI_Indication01 250;
BA_REL_ "GenSigSuprvResp" BU_SG_REL_ BCM_HS SG_ 479 PTWrmgWtToShftIO 1;
BA_REL_ "GenSigTimeoutMsg" BU_SG_REL_ BCM_HS SG_ 479 PTWrmgWtToShftIO 479;
BA_REL_ "GenSigTimeoutTime" BU_SG_REL_ BCM_HS SG_ 479 PTWrmgWtToShftIO 250;
BA_REL_ "GenSigSuprvResp" BU_SG_REL_ EPB_HS SG_ 479 PrplsnSysAtv 1;
BA_REL_ "GenSigTimeoutMsg" BU_SG_REL_ EPB_HS SG_ 479 PrplsnSysAtv 479;
BA_REL_ "GenSigTimeoutTime" BU_SG_REL_ EPB_HS SG_ 479 PrplsnSysAtv 250;
BA_REL_ "GenSigSuprvResp" BU_SG_REL_ VICM_HS SG_ 479 PrplsnSysAtv 1;
BA_REL_ "GenSigTimeoutMsg" BU_SG_REL_ VICM_HS SG_ 479 PrplsnSysAtv 479;
BA_REL_ "GenSigTimeoutTime" BU_SG_REL_ VICM_HS SG_ 479 PrplsnSysAtv 250;
BA_REL_ "GenSigSuprvResp" BU_SG_REL_ ICCM_OBD_HS SG_ 479 PrplsnSysAtv 1;
BA_REL_ "GenSigTimeoutMsg" BU_SG_REL_ ICCM_OBD_HS SG_ 479 PrplsnSysAtv 479;
BA_REL_ "GenSigTimeoutTime" BU_SG_REL_ ICCM_OBD_HS SG_ 479 PrplsnSysAtv 250;
BA_REL_ "GenSigSuprvResp" BU_SG_REL_ ICCM_HS SG_ 479 PrplsnSysAtv 1;
BA_REL_ "GenSigTimeoutMsg" BU_SG_REL_ ICCM_HS SG_ 479 PrplsnSysAtv 479;
BA_REL_ "GenSigTimeoutTime" BU_SG_REL_ ICCM_HS SG_ 479 PrplsnSysAtv 250;
BA_REL_ "GenSigSuprvResp" BU_SG_REL_ FSCM_HS SG_ 479 PrplsnSysAtv 1;
BA_REL_ "GenSigTimeoutMsg" BU_SG_REL_ FSCM_HS SG_ 479 PrplsnSysAtv 479;
BA_REL_ "GenSigTimeoutTime" BU_SG_REL_ FSCM_HS SG_ 479 PrplsnSysAtv 250;
BA_REL_ "GenSigSuprvResp" BU_SG_REL_ VICM2_HS SG_ 479 PrplsnSysAtv 1;
BA_REL_ "GenSigTimeoutMsg" BU_SG_REL_ VICM2_HS SG_ 479 PrplsnSysAtv 479;
BA_REL_ "GenSigTimeoutTime" BU_SG_REL_ VICM2_HS SG_ 479 PrplsnSysAtv 250;
BA_REL_ "GenSigSuprvResp" BU_SG_REL_ VICM2_HS SG_ 479 PrplsnSysAtv 1;
BA_REL_ "GenSigTimeoutMsg" BU_SG_REL_ VICM2_HS SG_ 479 PrplsnSysAtv 479;
BA_REL_ "GenSigTimeoutTime" BU_SG_REL_ VICM2_HS SG_ 479 PrplsnSysAtv 250;
BA_REL_ "GenSigSuprvResp" BU_SG_REL_ BCM_HS SG_ 479 PTShftLvrLckRqd 1;
BA_REL_ "GenSigTimeoutMsg" BU_SG_REL_ BCM_HS SG_ 479 PTShftLvrLckRqd 479;
BA_REL_ "GenSigTimeoutTime" BU_SG_REL_ BCM_HS SG_ 479 PTShftLvrLckRqd 250;
BA_REL_ "GenSigSuprvResp" BU_SG_REL_ SADS_HS SG_ 211 ActAxleTrq 1;
BA_REL_ "GenSigTimeoutMsg" BU_SG_REL_ SADS_HS SG_ 211 ActAxleTrq 211;
BA_REL_ "GenSigTimeoutTime" BU_SG_REL_ SADS_HS SG_ 211 ActAxleTrq 250;
BA_REL_ "GenSigSuprvResp" BU_SG_REL_ EOCM_F_HS SG_ 211 ActAxleTrq 1;
BA_REL_ "GenSigTimeoutMsg" BU_SG_REL_ EOCM_F_HS SG_ 211 ActAxleTrq 211;
BA_REL_ "GenSigTimeoutTime" BU_SG_REL_ EOCM_F_HS SG_ 211 ActAxleTrq 120;
BA_REL_ "GenSigSuprvResp" BU_SG_REL_ EOCM_F_HS SG_ 211 ActAxleTrq 1;
BA_REL_ "GenSigTimeoutMsg" BU_SG_REL_ EOCM_F_HS SG_ 211 ActAxleTrq 211;
BA_REL_ "GenSigTimeoutTime" BU_SG_REL_ EOCM_F_HS SG_ 211 ActAxleTrq 120;
BA_REL_ "GenSigSuprvResp" BU_SG_REL_ VICM_HS SG_ 211 ActAxleTrq 1;
BA_REL_ "GenSigTimeoutMsg" BU_SG_REL_ VICM_HS SG_ 211 ActAxleTrq 211;
BA_REL_ "GenSigTimeoutTime" BU_SG_REL_ VICM_HS SG_ 211 ActAxleTrq 250;
BA_REL_ "GenSigSuprvResp" BU_SG_REL_ VICM_HS SG_ 1020 OtsAirTmpEmsnsRel 1;
BA_REL_ "GenSigTimeoutMsg" BU_SG_REL_ VICM_HS SG_ 1020 OtsAirTmpEmsnsRel 1020;
BA_REL_ "GenSigTimeoutTime" BU_SG_REL_ VICM_HS SG_ 1020 OtsAirTmpEmsnsRel 625;
BA_REL_ "GenSigSuprvResp" BU_SG_REL_ VICM_HS SG_ 1020 OATEmsnsRelCrVal 1;
BA_REL_ "GenSigTimeoutMsg" BU_SG_REL_ VICM_HS SG_ 1020 OATEmsnsRelCrVal 1020;
BA_REL_ "GenSigTimeoutTime" BU_SG_REL_ VICM_HS SG_ 1020 OATEmsnsRelCrVal 625;
BA_REL_ "GenSigSuprvResp" BU_SG_REL_ VICM_HS SG_ 1020 CatlystOutGasTempEst 1;
BA_REL_ "GenSigTimeoutMsg" BU_SG_REL_ VICM_HS SG_ 1020 CatlystOutGasTempEst 1020;
BA_REL_ "GenSigTimeoutTime" BU_SG_REL_ VICM_HS SG_ 1020 CatlystOutGasTempEst 625;
BA_REL_ "GenSigSuprvResp" BU_SG_REL_ VICM_HS SG_ 1020 OtsAirTmpCrVal 1;
BA_REL_ "GenSigTimeoutMsg" BU_SG_REL_ VICM_HS SG_ 1020 OtsAirTmpCrVal 1020;
BA_REL_ "GenSigTimeoutTime" BU_SG_REL_ VICM_HS SG_ 1020 OtsAirTmpCrVal 625;
BA_REL_ "GenSigSuprvResp" BU_SG_REL_ VICM_HS SG_ 1020 OtsAirTmp 1;
BA_REL_ "GenSigTimeoutMsg" BU_SG_REL_ VICM_HS SG_ 1020 OtsAirTmp 1020;
BA_REL_ "GenSigTimeoutTime" BU_SG_REL_ VICM_HS SG_ 1020 OtsAirTmp 625;
BA_REL_ "GenSigSuprvResp" BU_SG_REL_ VICM_HS SG_ 1020 EngInltSpcfcHmdty 1;
BA_REL_ "GenSigTimeoutMsg" BU_SG_REL_ VICM_HS SG_ 1020 EngInltSpcfcHmdty 1020;
BA_REL_ "GenSigTimeoutTime" BU_SG_REL_ VICM_HS SG_ 1020 EngInltSpcfcHmdty 625;
BA_REL_ "GenSigSuprvResp" BU_SG_REL_ BCM_HS SG_ 1219 DslExhFldDiagWrnIdRq 1;
BA_REL_ "GenSigTimeoutMsg" BU_SG_REL_ BCM_HS SG_ 1219 DslExhFldDiagWrnIdRq 1219;
BA_REL_ "GenSigTimeoutTime" BU_SG_REL_ BCM_HS SG_ 1219 DslExhFldDiagWrnIdRq 2500;
BA_REL_ "GenSigSuprvResp" BU_SG_REL_ BCM_HS SG_ 1219 DslEmnsOBDMrkt 1;
BA_REL_ "GenSigTimeoutMsg" BU_SG_REL_ BCM_HS SG_ 1219 DslEmnsOBDMrkt 1219;
BA_REL_ "GenSigTimeoutTime" BU_SG_REL_ BCM_HS SG_ 1219 DslEmnsOBDMrkt 2500;
BA_REL_ "GenSigSuprvResp" BU_SG_REL_ VICM_HS SG_ 552 ThrmlRefCmpIGBTTmp 1;
BA_REL_ "GenSigTimeoutMsg" BU_SG_REL_ VICM_HS SG_ 552 ThrmlRefCmpIGBTTmp 552;
BA_REL_ "GenSigTimeoutTime" BU_SG_REL_ VICM_HS SG_ 552 ThrmlRefCmpIGBTTmp 250;
BA_REL_ "GenSigSuprvResp" BU_SG_REL_ VICM_HS SG_ 552 ThrmlRefCmpHiVltgInpt 1;
BA_REL_ "GenSigTimeoutMsg" BU_SG_REL_ VICM_HS SG_ 552 ThrmlRefCmpHiVltgInpt 552;
BA_REL_ "GenSigTimeoutTime" BU_SG_REL_ VICM_HS SG_ 552 ThrmlRefCmpHiVltgInpt 250;
BA_REL_ "GenSigSuprvResp" BU_SG_REL_ VICM_HS SG_ 552 ThrmlRefCmpCPUHtSkTmp 1;
BA_REL_ "GenSigTimeoutMsg" BU_SG_REL_ VICM_HS SG_ 552 ThrmlRefCmpCPUHtSkTmp 552;
BA_REL_ "GenSigTimeoutTime" BU_SG_REL_ VICM_HS SG_ 552 ThrmlRefCmpCPUHtSkTmp 250;
BA_REL_ "GenSigSuprvResp" BU_SG_REL_ TCM_HS SG_ 442 CrksftTqMinImCap 1;
BA_REL_ "GenSigTimeoutMsg" BU_SG_REL_ TCM_HS SG_ 442 CrksftTqMinImCap 442;
BA_REL_ "GenSigTimeoutTime" BU_SG_REL_ TCM_HS SG_ 442 CrksftTqMinImCap 250;
BA_REL_ "GenSigSuprvResp" BU_SG_REL_ HCP_HS SG_ 989 RdHVCntctrShdwnReq 1;
BA_REL_ "GenSigTimeoutMsg" BU_SG_REL_ HCP_HS SG_ 989 RdHVCntctrShdwnReq 989;
BA_REL_ "GenSigTimeoutTime" BU_SG_REL_ HCP_HS SG_ 989 RdHVCntctrShdwnReq 250;
BA_REL_ "GenSigSuprvResp" BU_SG_REL_ HCP_HS SG_ 989 RdHVCntctrShdwnReq 1;
BA_REL_ "GenSigTimeoutMsg" BU_SG_REL_ HCP_HS SG_ 989 RdHVCntctrShdwnReq 989;
BA_REL_ "GenSigTimeoutTime" BU_SG_REL_ HCP_HS SG_ 989 RdHVCntctrShdwnReq 250;
BA_REL_ "GenSigSuprvResp" BU_SG_REL_ HCP_HS SG_ 989 RdHVCntctrShdwnReq 1;
BA_REL_ "GenSigTimeoutMsg" BU_SG_REL_ HCP_HS SG_ 989 RdHVCntctrShdwnReq 989;
BA_REL_ "GenSigTimeoutTime" BU_SG_REL_ HCP_HS SG_ 989 RdHVCntctrShdwnReq 250;
BA_REL_ "GenSigSuprvResp" BU_SG_REL_ HCP_HS SG_ 989 RdHVCntctrCmdStat 1;
BA_REL_ "GenSigTimeoutMsg" BU_SG_REL_ HCP_HS SG_ 989 RdHVCntctrCmdStat 989;
BA_REL_ "GenSigTimeoutTime" BU_SG_REL_ HCP_HS SG_ 989 RdHVCntctrCmdStat 250;
BA_REL_ "GenSigSuprvResp" BU_SG_REL_ HCP_HS SG_ 989 RdHVCntctrCmdStat 1;
BA_REL_ "GenSigTimeoutMsg" BU_SG_REL_ HCP_HS SG_ 989 RdHVCntctrCmdStat 989;
BA_REL_ "GenSigTimeoutTime" BU_SG_REL_ HCP_HS SG_ 989 RdHVCntctrCmdStat 250;
BA_REL_ "GenSigSuprvResp" BU_SG_REL_ HCP_HS SG_ 989 RdHVCntctrCmdStat 1;
BA_REL_ "GenSigTimeoutMsg" BU_SG_REL_ HCP_HS SG_ 989 RdHVCntctrCmdStat 989;
BA_REL_ "GenSigTimeoutTime" BU_SG_REL_ HCP_HS SG_ 989 RdHVCntctrCmdStat 250;
BA_REL_ "GenSigSuprvResp" BU_SG_REL_ VICM_HS SG_ 988 AccPwrModMinCoolRq 1;
BA_REL_ "GenSigTimeoutMsg" BU_SG_REL_ VICM_HS SG_ 988 AccPwrModMinCoolRq 988;
BA_REL_ "GenSigTimeoutTime" BU_SG_REL_ VICM_HS SG_ 988 AccPwrModMinCoolRq 250;
BA_REL_ "GenSigSuprvResp" BU_SG_REL_ VICM_HS SG_ 988 A6ERRAlrmTime 1;
BA_REL_ "GenSigTimeoutMsg" BU_SG_REL_ VICM_HS SG_ 988 A6ERRAlrmTime 988;
BA_REL_ "GenSigTimeoutTime" BU_SG_REL_ VICM_HS SG_ 988 A6ERRAlrmTime 250;
BA_REL_ "GenSigSuprvResp" BU_SG_REL_ VICM_HS SG_ 988 A6ERRAlrmReq 1;
BA_REL_ "GenSigTimeoutMsg" BU_SG_REL_ VICM_HS SG_ 988 A6ERRAlrmReq 988;
BA_REL_ "GenSigTimeoutTime" BU_SG_REL_ VICM_HS SG_ 988 A6ERRAlrmReq 250;
BA_REL_ "GenSigSuprvResp" BU_SG_REL_ VICM_HS SG_ 988 EngHtrValvBpasCmd 1;
BA_REL_ "GenSigTimeoutMsg" BU_SG_REL_ VICM_HS SG_ 988 EngHtrValvBpasCmd 988;
BA_REL_ "GenSigTimeoutTime" BU_SG_REL_ VICM_HS SG_ 988 EngHtrValvBpasCmd 250;
BA_REL_ "GenSigSuprvResp" BU_SG_REL_ AHL_AFL_HS SG_ 1029 FCO6D_ObjVertVar 1;
BA_REL_ "GenSigTimeoutMsg" BU_SG_REL_ AHL_AFL_HS SG_ 1029 FCO6D_ObjVertVar 1029;
BA_REL_ "GenSigTimeoutTime" BU_SG_REL_ AHL_AFL_HS SG_ 1029 FCO6D_ObjVertVar 250;
BA_REL_ "GenSigSuprvResp" BU_SG_REL_ AHL_AFL_HS SG_ 1029 FCO6D_ObjVertPos 1;
BA_REL_ "GenSigTimeoutMsg" BU_SG_REL_ AHL_AFL_HS SG_ 1029 FCO6D_ObjVertPos 1029;
BA_REL_ "GenSigTimeoutTime" BU_SG_REL_ AHL_AFL_HS SG_ 1029 FCO6D_ObjVertPos 250;
BA_REL_ "GenSigSuprvResp" BU_SG_REL_ AHL_AFL_HS SG_ 1029 FCO6D_ObjTyp 1;
BA_REL_ "GenSigTimeoutMsg" BU_SG_REL_ AHL_AFL_HS SG_ 1029 FCO6D_ObjTyp 1029;
BA_REL_ "GenSigTimeoutTime" BU_SG_REL_ AHL_AFL_HS SG_ 1029 FCO6D_ObjTyp 250;
BA_REL_ "GenSigSuprvResp" BU_SG_REL_ AHL_AFL_HS SG_ 1029 FCO6D_ObjQlty 1;
BA_REL_ "GenSigTimeoutMsg" BU_SG_REL_ AHL_AFL_HS SG_ 1029 FCO6D_ObjQlty 1029;
BA_REL_ "GenSigTimeoutTime" BU_SG_REL_ AHL_AFL_HS SG_ 1029 FCO6D_ObjQlty 250;
BA_REL_ "GenSigSuprvResp" BU_SG_REL_ AHL_AFL_HS SG_ 1029 FCO6D_ObjId 1;
BA_REL_ "GenSigTimeoutMsg" BU_SG_REL_ AHL_AFL_HS SG_ 1029 FCO6D_ObjId 1029;
BA_REL_ "GenSigTimeoutTime" BU_SG_REL_ AHL_AFL_HS SG_ 1029 FCO6D_ObjId 250;
BA_REL_ "GenSigSuprvResp" BU_SG_REL_ AHL_AFL_HS SG_ 1029 FCO6D_ObjHorzPos 1;
BA_REL_ "GenSigTimeoutMsg" BU_SG_REL_ AHL_AFL_HS SG_ 1029 FCO6D_ObjHorzPos 1029;
BA_REL_ "GenSigTimeoutTime" BU_SG_REL_ AHL_AFL_HS SG_ 1029 FCO6D_ObjHorzPos 250;
BA_REL_ "GenSigSuprvResp" BU_SG_REL_ AHL_AFL_HS SG_ 1029 FCO6D_ObjHorzDim 1;
BA_REL_ "GenSigTimeoutMsg" BU_SG_REL_ AHL_AFL_HS SG_ 1029 FCO6D_ObjHorzDim 1029;
BA_REL_ "GenSigTimeoutTime" BU_SG_REL_ AHL_AFL_HS SG_ 1029 FCO6D_ObjHorzDim 250;
BA_REL_ "GenSigSuprvResp" BU_SG_REL_ AHL_AFL_HS SG_ 1029 FCO6D_ObjDist 1;
BA_REL_ "GenSigTimeoutMsg" BU_SG_REL_ AHL_AFL_HS SG_ 1029 FCO6D_ObjDist 1029;
BA_REL_ "GenSigTimeoutTime" BU_SG_REL_ AHL_AFL_HS SG_ 1029 FCO6D_ObjDist 250;
BA_REL_ "GenSigSuprvResp" BU_SG_REL_ AHL_AFL_HS SG_ 1029 FCO6D_DetMthd 1;
BA_REL_ "GenSigTimeoutMsg" BU_SG_REL_ AHL_AFL_HS SG_ 1029 FCO6D_DetMthd 1029;
BA_REL_ "GenSigTimeoutTime" BU_SG_REL_ AHL_AFL_HS SG_ 1029 FCO6D_DetMthd 250;
BA_REL_ "GenSigSuprvResp" BU_SG_REL_ AHL_AFL_HS SG_ 1028 FCO5D_ObjVertVar 1;
BA_REL_ "GenSigTimeoutMsg" BU_SG_REL_ AHL_AFL_HS SG_ 1028 FCO5D_ObjVertVar 1028;
BA_REL_ "GenSigTimeoutTime" BU_SG_REL_ AHL_AFL_HS SG_ 1028 FCO5D_ObjVertVar 250;
BA_REL_ "GenSigSuprvResp" BU_SG_REL_ AHL_AFL_HS SG_ 1028 FCO5D_ObjVertPos 1;
BA_REL_ "GenSigTimeoutMsg" BU_SG_REL_ AHL_AFL_HS SG_ 1028 FCO5D_ObjVertPos 1028;
BA_REL_ "GenSigTimeoutTime" BU_SG_REL_ AHL_AFL_HS SG_ 1028 FCO5D_ObjVertPos 250;
BA_REL_ "GenSigSuprvResp" BU_SG_REL_ AHL_AFL_HS SG_ 1028 FCO5D_ObjTyp 1;
BA_REL_ "GenSigTimeoutMsg" BU_SG_REL_ AHL_AFL_HS SG_ 1028 FCO5D_ObjTyp 1028;
BA_REL_ "GenSigTimeoutTime" BU_SG_REL_ AHL_AFL_HS SG_ 1028 FCO5D_ObjTyp 250;
BA_REL_ "GenSigSuprvResp" BU_SG_REL_ AHL_AFL_HS SG_ 1028 FCO5D_ObjQlty 1;
BA_REL_ "GenSigTimeoutMsg" BU_SG_REL_ AHL_AFL_HS SG_ 1028 FCO5D_ObjQlty 1028;
BA_REL_ "GenSigTimeoutTime" BU_SG_REL_ AHL_AFL_HS SG_ 1028 FCO5D_ObjQlty 250;
BA_REL_ "GenSigSuprvResp" BU_SG_REL_ AHL_AFL_HS SG_ 1028 FCO5D_ObjId 1;
BA_REL_ "GenSigTimeoutMsg" BU_SG_REL_ AHL_AFL_HS SG_ 1028 FCO5D_ObjId 1028;
BA_REL_ "GenSigTimeoutTime" BU_SG_REL_ AHL_AFL_HS SG_ 1028 FCO5D_ObjId 250;
BA_REL_ "GenSigSuprvResp" BU_SG_REL_ AHL_AFL_HS SG_ 1028 FCO5D_ObjHorzPos 1;
BA_REL_ "GenSigTimeoutMsg" BU_SG_REL_ AHL_AFL_HS SG_ 1028 FCO5D_ObjHorzPos 1028;
BA_REL_ "GenSigTimeoutTime" BU_SG_REL_ AHL_AFL_HS SG_ 1028 FCO5D_ObjHorzPos 250;
BA_REL_ "GenSigSuprvResp" BU_SG_REL_ AHL_AFL_HS SG_ 1028 FCO5D_ObjHorzDim 1;
BA_REL_ "GenSigTimeoutMsg" BU_SG_REL_ AHL_AFL_HS SG_ 1028 FCO5D_ObjHorzDim 1028;
BA_REL_ "GenSigTimeoutTime" BU_SG_REL_ AHL_AFL_HS SG_ 1028 FCO5D_ObjHorzDim 250;
BA_REL_ "GenSigSuprvResp" BU_SG_REL_ AHL_AFL_HS SG_ 1028 FCO5D_ObjDist 1;
BA_REL_ "GenSigTimeoutMsg" BU_SG_REL_ AHL_AFL_HS SG_ 1028 FCO5D_ObjDist 1028;
BA_REL_ "GenSigTimeoutTime" BU_SG_REL_ AHL_AFL_HS SG_ 1028 FCO5D_ObjDist 250;
BA_REL_ "GenSigSuprvResp" BU_SG_REL_ AHL_AFL_HS SG_ 1028 FCO5D_DetMthd 1;
BA_REL_ "GenSigTimeoutMsg" BU_SG_REL_ AHL_AFL_HS SG_ 1028 FCO5D_DetMthd 1028;
BA_REL_ "GenSigTimeoutTime" BU_SG_REL_ AHL_AFL_HS SG_ 1028 FCO5D_DetMthd 250;
BA_REL_ "GenSigSuprvResp" BU_SG_REL_ EBCM_OBD_HS SG_ 500 EnhDrvMdSwChUseAct 1;
BA_REL_ "GenSigTimeoutMsg" BU_SG_REL_ EBCM_OBD_HS SG_ 500 EnhDrvMdSwChUseAct 500;
BA_REL_ "GenSigTimeoutTime" BU_SG_REL_ EBCM_OBD_HS SG_ 500 EnhDrvMdSwChUseAct 250;
BA_REL_ "GenSigSuprvResp" BU_SG_REL_ EBCM_HS SG_ 500 EnhDrvMdSwChUseAct 1;
BA_REL_ "GenSigTimeoutMsg" BU_SG_REL_ EBCM_HS SG_ 500 EnhDrvMdSwChUseAct 500;
BA_REL_ "GenSigTimeoutTime" BU_SG_REL_ EBCM_HS SG_ 500 EnhDrvMdSwChUseAct 250;
BA_REL_ "GenSigSuprvResp" BU_SG_REL_ EBCM_OBD_HS SG_ 500 EnhDrvSelMdSwStat 1;
BA_REL_ "GenSigTimeoutMsg" BU_SG_REL_ EBCM_OBD_HS SG_ 500 EnhDrvSelMdSwStat 500;
BA_REL_ "GenSigTimeoutTime" BU_SG_REL_ EBCM_OBD_HS SG_ 500 EnhDrvSelMdSwStat 250;
BA_REL_ "GenSigSuprvResp" BU_SG_REL_ EBCM_HS SG_ 500 EnhDrvSelMdSwStat 1;
BA_REL_ "GenSigTimeoutMsg" BU_SG_REL_ EBCM_HS SG_ 500 EnhDrvSelMdSwStat 500;
BA_REL_ "GenSigTimeoutTime" BU_SG_REL_ EBCM_HS SG_ 500 EnhDrvSelMdSwStat 250;
BA_REL_ "GenSigSuprvResp" BU_SG_REL_ EBCM_OBD_HS SG_ 500 DrvSelMd7Stat 1;
BA_REL_ "GenSigTimeoutMsg" BU_SG_REL_ EBCM_OBD_HS SG_ 500 DrvSelMd7Stat 500;
BA_REL_ "GenSigTimeoutTime" BU_SG_REL_ EBCM_OBD_HS SG_ 500 DrvSelMd7Stat 250;
BA_REL_ "GenSigSuprvResp" BU_SG_REL_ EBCM_HS SG_ 500 DrvSelMd7Stat 1;
BA_REL_ "GenSigTimeoutMsg" BU_SG_REL_ EBCM_HS SG_ 500 DrvSelMd7Stat 500;
BA_REL_ "GenSigTimeoutTime" BU_SG_REL_ EBCM_HS SG_ 500 DrvSelMd7Stat 250;
BA_REL_ "GenSigSuprvResp" BU_SG_REL_ EBCM_OBD_HS SG_ 500 DrvSelMd6Stat 1;
BA_REL_ "GenSigTimeoutMsg" BU_SG_REL_ EBCM_OBD_HS SG_ 500 DrvSelMd6Stat 500;
BA_REL_ "GenSigTimeoutTime" BU_SG_REL_ EBCM_OBD_HS SG_ 500 DrvSelMd6Stat 250;
BA_REL_ "GenSigSuprvResp" BU_SG_REL_ EBCM_HS SG_ 500 DrvSelMd6Stat 1;
BA_REL_ "GenSigTimeoutMsg" BU_SG_REL_ EBCM_HS SG_ 500 DrvSelMd6Stat 500;
BA_REL_ "GenSigTimeoutTime" BU_SG_REL_ EBCM_HS SG_ 500 DrvSelMd6Stat 250;
BA_REL_ "GenSigSuprvResp" BU_SG_REL_ EBCM_OBD_HS SG_ 500 DrvSelMd5Stat 1;
BA_REL_ "GenSigTimeoutMsg" BU_SG_REL_ EBCM_OBD_HS SG_ 500 DrvSelMd5Stat 500;
BA_REL_ "GenSigTimeoutTime" BU_SG_REL_ EBCM_OBD_HS SG_ 500 DrvSelMd5Stat 250;
BA_REL_ "GenSigSuprvResp" BU_SG_REL_ EBCM_HS SG_ 500 DrvSelMd5Stat 1;
BA_REL_ "GenSigTimeoutMsg" BU_SG_REL_ EBCM_HS SG_ 500 DrvSelMd5Stat 500;
BA_REL_ "GenSigTimeoutTime" BU_SG_REL_ EBCM_HS SG_ 500 DrvSelMd5Stat 250;
BA_REL_ "GenSigSuprvResp" BU_SG_REL_ EBCM_OBD_HS SG_ 500 DrvSelMd4Stat 1;
BA_REL_ "GenSigTimeoutMsg" BU_SG_REL_ EBCM_OBD_HS SG_ 500 DrvSelMd4Stat 500;
BA_REL_ "GenSigTimeoutTime" BU_SG_REL_ EBCM_OBD_HS SG_ 500 DrvSelMd4Stat 250;
BA_REL_ "GenSigSuprvResp" BU_SG_REL_ EBCM_HS SG_ 500 DrvSelMd4Stat 1;
BA_REL_ "GenSigTimeoutMsg" BU_SG_REL_ EBCM_HS SG_ 500 DrvSelMd4Stat 500;
BA_REL_ "GenSigTimeoutTime" BU_SG_REL_ EBCM_HS SG_ 500 DrvSelMd4Stat 250;
BA_REL_ "GenSigSuprvResp" BU_SG_REL_ EBCM_OBD_HS SG_ 500 DrvSelMd3Stat 1;
BA_REL_ "GenSigTimeoutMsg" BU_SG_REL_ EBCM_OBD_HS SG_ 500 DrvSelMd3Stat 500;
BA_REL_ "GenSigTimeoutTime" BU_SG_REL_ EBCM_OBD_HS SG_ 500 DrvSelMd3Stat 250;
BA_REL_ "GenSigSuprvResp" BU_SG_REL_ EBCM_HS SG_ 500 DrvSelMd3Stat 1;
BA_REL_ "GenSigTimeoutMsg" BU_SG_REL_ EBCM_HS SG_ 500 DrvSelMd3Stat 500;
BA_REL_ "GenSigTimeoutTime" BU_SG_REL_ EBCM_HS SG_ 500 DrvSelMd3Stat 250;
BA_REL_ "GenSigSuprvResp" BU_SG_REL_ EBCM_OBD_HS SG_ 500 DrvSelMd2Stat 1;
BA_REL_ "GenSigTimeoutMsg" BU_SG_REL_ EBCM_OBD_HS SG_ 500 DrvSelMd2Stat 500;
BA_REL_ "GenSigTimeoutTime" BU_SG_REL_ EBCM_OBD_HS SG_ 500 DrvSelMd2Stat 250;
BA_REL_ "GenSigSuprvResp" BU_SG_REL_ EBCM_HS SG_ 500 DrvSelMd2Stat 1;
BA_REL_ "GenSigTimeoutMsg" BU_SG_REL_ EBCM_HS SG_ 500 DrvSelMd2Stat 500;
BA_REL_ "GenSigTimeoutTime" BU_SG_REL_ EBCM_HS SG_ 500 DrvSelMd2Stat 250;
BA_REL_ "GenSigSuprvResp" BU_SG_REL_ EBCM_OBD_HS SG_ 500 DSMSS_DrvSelMd0Pn 1;
BA_REL_ "GenSigTimeoutMsg" BU_SG_REL_ EBCM_OBD_HS SG_ 500 DSMSS_DrvSelMd0Pn 500;
BA_REL_ "GenSigTimeoutTime" BU_SG_REL_ EBCM_OBD_HS SG_ 500 DSMSS_DrvSelMd0Pn 250;
BA_REL_ "GenSigSuprvResp" BU_SG_REL_ EBCM_HS SG_ 500 DSMSS_DrvSelMd0Pn 1;
BA_REL_ "GenSigTimeoutMsg" BU_SG_REL_ EBCM_HS SG_ 500 DSMSS_DrvSelMd0Pn 500;
BA_REL_ "GenSigTimeoutTime" BU_SG_REL_ EBCM_HS SG_ 500 DSMSS_DrvSelMd0Pn 250;
BA_REL_ "GenSigSuprvResp" BU_SG_REL_ EBCM_OBD_HS SG_ 500 DSMSS_DrvSelMd8Pn 1;
BA_REL_ "GenSigTimeoutMsg" BU_SG_REL_ EBCM_OBD_HS SG_ 500 DSMSS_DrvSelMd8Pn 500;
BA_REL_ "GenSigTimeoutTime" BU_SG_REL_ EBCM_OBD_HS SG_ 500 DSMSS_DrvSelMd8Pn 250;
BA_REL_ "GenSigSuprvResp" BU_SG_REL_ EBCM_HS SG_ 500 DSMSS_DrvSelMd8Pn 1;
BA_REL_ "GenSigTimeoutMsg" BU_SG_REL_ EBCM_HS SG_ 500 DSMSS_DrvSelMd8Pn 500;
BA_REL_ "GenSigTimeoutTime" BU_SG_REL_ EBCM_HS SG_ 500 DSMSS_DrvSelMd8Pn 250;
BA_REL_ "GenSigSuprvResp" BU_SG_REL_ EBCM_OBD_HS SG_ 500 DSMSS_DrvSelMd7Pn 1;
BA_REL_ "GenSigTimeoutMsg" BU_SG_REL_ EBCM_OBD_HS SG_ 500 DSMSS_DrvSelMd7Pn 500;
BA_REL_ "GenSigTimeoutTime" BU_SG_REL_ EBCM_OBD_HS SG_ 500 DSMSS_DrvSelMd7Pn 250;
BA_REL_ "GenSigSuprvResp" BU_SG_REL_ EBCM_HS SG_ 500 DSMSS_DrvSelMd7Pn 1;
BA_REL_ "GenSigTimeoutMsg" BU_SG_REL_ EBCM_HS SG_ 500 DSMSS_DrvSelMd7Pn 500;
BA_REL_ "GenSigTimeoutTime" BU_SG_REL_ EBCM_HS SG_ 500 DSMSS_DrvSelMd7Pn 250;
BA_REL_ "GenSigSuprvResp" BU_SG_REL_ EBCM_OBD_HS SG_ 500 DSMSS_DrvSelMd6Pn 1;
BA_REL_ "GenSigTimeoutMsg" BU_SG_REL_ EBCM_OBD_HS SG_ 500 DSMSS_DrvSelMd6Pn 500;
BA_REL_ "GenSigTimeoutTime" BU_SG_REL_ EBCM_OBD_HS SG_ 500 DSMSS_DrvSelMd6Pn 250;
BA_REL_ "GenSigSuprvResp" BU_SG_REL_ EBCM_HS SG_ 500 DSMSS_DrvSelMd6Pn 1;
BA_REL_ "GenSigTimeoutMsg" BU_SG_REL_ EBCM_HS SG_ 500 DSMSS_DrvSelMd6Pn 500;
BA_REL_ "GenSigTimeoutTime" BU_SG_REL_ EBCM_HS SG_ 500 DSMSS_DrvSelMd6Pn 250;
BA_REL_ "GenSigSuprvResp" BU_SG_REL_ EBCM_OBD_HS SG_ 500 DSMSS_DrvSelMd5Pn 1;
BA_REL_ "GenSigTimeoutMsg" BU_SG_REL_ EBCM_OBD_HS SG_ 500 DSMSS_DrvSelMd5Pn 500;
BA_REL_ "GenSigTimeoutTime" BU_SG_REL_ EBCM_OBD_HS SG_ 500 DSMSS_DrvSelMd5Pn 250;
BA_REL_ "GenSigSuprvResp" BU_SG_REL_ EBCM_HS SG_ 500 DSMSS_DrvSelMd5Pn 1;
BA_REL_ "GenSigTimeoutMsg" BU_SG_REL_ EBCM_HS SG_ 500 DSMSS_DrvSelMd5Pn 500;
BA_REL_ "GenSigTimeoutTime" BU_SG_REL_ EBCM_HS SG_ 500 DSMSS_DrvSelMd5Pn 250;
BA_REL_ "GenSigSuprvResp" BU_SG_REL_ EBCM_OBD_HS SG_ 500 DSMSS_DrvSelMd4Pn 1;
BA_REL_ "GenSigTimeoutMsg" BU_SG_REL_ EBCM_OBD_HS SG_ 500 DSMSS_DrvSelMd4Pn 500;
BA_REL_ "GenSigTimeoutTime" BU_SG_REL_ EBCM_OBD_HS SG_ 500 DSMSS_DrvSelMd4Pn 250;
BA_REL_ "GenSigSuprvResp" BU_SG_REL_ EBCM_HS SG_ 500 DSMSS_DrvSelMd4Pn 1;
BA_REL_ "GenSigTimeoutMsg" BU_SG_REL_ EBCM_HS SG_ 500 DSMSS_DrvSelMd4Pn 500;
BA_REL_ "GenSigTimeoutTime" BU_SG_REL_ EBCM_HS SG_ 500 DSMSS_DrvSelMd4Pn 250;
BA_REL_ "GenSigSuprvResp" BU_SG_REL_ EBCM_OBD_HS SG_ 500 DSMSS_DrvSelMd3Pn 1;
BA_REL_ "GenSigTimeoutMsg" BU_SG_REL_ EBCM_OBD_HS SG_ 500 DSMSS_DrvSelMd3Pn 500;
BA_REL_ "GenSigTimeoutTime" BU_SG_REL_ EBCM_OBD_HS SG_ 500 DSMSS_DrvSelMd3Pn 250;
BA_REL_ "GenSigSuprvResp" BU_SG_REL_ EBCM_HS SG_ 500 DSMSS_DrvSelMd3Pn 1;
BA_REL_ "GenSigTimeoutMsg" BU_SG_REL_ EBCM_HS SG_ 500 DSMSS_DrvSelMd3Pn 500;
BA_REL_ "GenSigTimeoutTime" BU_SG_REL_ EBCM_HS SG_ 500 DSMSS_DrvSelMd3Pn 250;
BA_REL_ "GenSigSuprvResp" BU_SG_REL_ EBCM_OBD_HS SG_ 500 DSMSS_DrvSelMd2Pn 1;
BA_REL_ "GenSigTimeoutMsg" BU_SG_REL_ EBCM_OBD_HS SG_ 500 DSMSS_DrvSelMd2Pn 500;
BA_REL_ "GenSigTimeoutTime" BU_SG_REL_ EBCM_OBD_HS SG_ 500 DSMSS_DrvSelMd2Pn 250;
BA_REL_ "GenSigSuprvResp" BU_SG_REL_ EBCM_HS SG_ 500 DSMSS_DrvSelMd2Pn 1;
BA_REL_ "GenSigTimeoutMsg" BU_SG_REL_ EBCM_HS SG_ 500 DSMSS_DrvSelMd2Pn 500;
BA_REL_ "GenSigTimeoutTime" BU_SG_REL_ EBCM_HS SG_ 500 DSMSS_DrvSelMd2Pn 250;
BA_REL_ "GenSigSuprvResp" BU_SG_REL_ EBCM_OBD_HS SG_ 500 DSMSS_DrvSelMd1Pn 1;
BA_REL_ "GenSigTimeoutMsg" BU_SG_REL_ EBCM_OBD_HS SG_ 500 DSMSS_DrvSelMd1Pn 500;
BA_REL_ "GenSigTimeoutTime" BU_SG_REL_ EBCM_OBD_HS SG_ 500 DSMSS_DrvSelMd1Pn 250;
BA_REL_ "GenSigSuprvResp" BU_SG_REL_ EBCM_HS SG_ 500 DSMSS_DrvSelMd1Pn 1;
BA_REL_ "GenSigTimeoutMsg" BU_SG_REL_ EBCM_HS SG_ 500 DSMSS_DrvSelMd1Pn 500;
BA_REL_ "GenSigTimeoutTime" BU_SG_REL_ EBCM_HS SG_ 500 DSMSS_DrvSelMd1Pn 250;
BA_REL_ "GenSigSuprvResp" BU_SG_REL_ EBCM_OBD_HS SG_ 500 DSMSS_DrvSelMd8Un 1;
BA_REL_ "GenSigTimeoutMsg" BU_SG_REL_ EBCM_OBD_HS SG_ 500 DSMSS_DrvSelMd8Un 500;
BA_REL_ "GenSigTimeoutTime" BU_SG_REL_ EBCM_OBD_HS SG_ 500 DSMSS_DrvSelMd8Un 250;
BA_REL_ "GenSigSuprvResp" BU_SG_REL_ EBCM_HS SG_ 500 DSMSS_DrvSelMd8Un 1;
BA_REL_ "GenSigTimeoutMsg" BU_SG_REL_ EBCM_HS SG_ 500 DSMSS_DrvSelMd8Un 500;
BA_REL_ "GenSigTimeoutTime" BU_SG_REL_ EBCM_HS SG_ 500 DSMSS_DrvSelMd8Un 250;
BA_REL_ "GenSigSuprvResp" BU_SG_REL_ EBCM_OBD_HS SG_ 500 DSMSS_DrvSelMd7Un 1;
BA_REL_ "GenSigTimeoutMsg" BU_SG_REL_ EBCM_OBD_HS SG_ 500 DSMSS_DrvSelMd7Un 500;
BA_REL_ "GenSigTimeoutTime" BU_SG_REL_ EBCM_OBD_HS SG_ 500 DSMSS_DrvSelMd7Un 250;
BA_REL_ "GenSigSuprvResp" BU_SG_REL_ EBCM_HS SG_ 500 DSMSS_DrvSelMd7Un 1;
BA_REL_ "GenSigTimeoutMsg" BU_SG_REL_ EBCM_HS SG_ 500 DSMSS_DrvSelMd7Un 500;
BA_REL_ "GenSigTimeoutTime" BU_SG_REL_ EBCM_HS SG_ 500 DSMSS_DrvSelMd7Un 250;
BA_REL_ "GenSigSuprvResp" BU_SG_REL_ EBCM_OBD_HS SG_ 500 DSMSS_DrvSelMd6Un 1;
BA_REL_ "GenSigTimeoutMsg" BU_SG_REL_ EBCM_OBD_HS SG_ 500 DSMSS_DrvSelMd6Un 500;
BA_REL_ "GenSigTimeoutTime" BU_SG_REL_ EBCM_OBD_HS SG_ 500 DSMSS_DrvSelMd6Un 250;
BA_REL_ "GenSigSuprvResp" BU_SG_REL_ EBCM_HS SG_ 500 DSMSS_DrvSelMd6Un 1;
BA_REL_ "GenSigTimeoutMsg" BU_SG_REL_ EBCM_HS SG_ 500 DSMSS_DrvSelMd6Un 500;
BA_REL_ "GenSigTimeoutTime" BU_SG_REL_ EBCM_HS SG_ 500 DSMSS_DrvSelMd6Un 250;
BA_REL_ "GenSigSuprvResp" BU_SG_REL_ EBCM_OBD_HS SG_ 500 DSMSS_DrvSelMd5Un 1;
BA_REL_ "GenSigTimeoutMsg" BU_SG_REL_ EBCM_OBD_HS SG_ 500 DSMSS_DrvSelMd5Un 500;
BA_REL_ "GenSigTimeoutTime" BU_SG_REL_ EBCM_OBD_HS SG_ 500 DSMSS_DrvSelMd5Un 250;
BA_REL_ "GenSigSuprvResp" BU_SG_REL_ EBCM_HS SG_ 500 DSMSS_DrvSelMd5Un 1;
BA_REL_ "GenSigTimeoutMsg" BU_SG_REL_ EBCM_HS SG_ 500 DSMSS_DrvSelMd5Un 500;
BA_REL_ "GenSigTimeoutTime" BU_SG_REL_ EBCM_HS SG_ 500 DSMSS_DrvSelMd5Un 250;
BA_REL_ "GenSigSuprvResp" BU_SG_REL_ EBCM_OBD_HS SG_ 500 DSMSS_DrvSelMd4Un 1;
BA_REL_ "GenSigTimeoutMsg" BU_SG_REL_ EBCM_OBD_HS SG_ 500 DSMSS_DrvSelMd4Un 500;
BA_REL_ "GenSigTimeoutTime" BU_SG_REL_ EBCM_OBD_HS SG_ 500 DSMSS_DrvSelMd4Un 250;
BA_REL_ "GenSigSuprvResp" BU_SG_REL_ EBCM_HS SG_ 500 DSMSS_DrvSelMd4Un 1;
BA_REL_ "GenSigTimeoutMsg" BU_SG_REL_ EBCM_HS SG_ 500 DSMSS_DrvSelMd4Un 500;
BA_REL_ "GenSigTimeoutTime" BU_SG_REL_ EBCM_HS SG_ 500 DSMSS_DrvSelMd4Un 250;
BA_REL_ "GenSigSuprvResp" BU_SG_REL_ EBCM_OBD_HS SG_ 500 DSMSS_DrvSelMd3Un 1;
BA_REL_ "GenSigTimeoutMsg" BU_SG_REL_ EBCM_OBD_HS SG_ 500 DSMSS_DrvSelMd3Un 500;
BA_REL_ "GenSigTimeoutTime" BU_SG_REL_ EBCM_OBD_HS SG_ 500 DSMSS_DrvSelMd3Un 250;
BA_REL_ "GenSigSuprvResp" BU_SG_REL_ EBCM_HS SG_ 500 DSMSS_DrvSelMd3Un 1;
BA_REL_ "GenSigTimeoutMsg" BU_SG_REL_ EBCM_HS SG_ 500 DSMSS_DrvSelMd3Un 500;
BA_REL_ "GenSigTimeoutTime" BU_SG_REL_ EBCM_HS SG_ 500 DSMSS_DrvSelMd3Un 250;
BA_REL_ "GenSigSuprvResp" BU_SG_REL_ EBCM_OBD_HS SG_ 500 DSMSS_DrvSelMd2Un 1;
BA_REL_ "GenSigTimeoutMsg" BU_SG_REL_ EBCM_OBD_HS SG_ 500 DSMSS_DrvSelMd2Un 500;
BA_REL_ "GenSigTimeoutTime" BU_SG_REL_ EBCM_OBD_HS SG_ 500 DSMSS_DrvSelMd2Un 250;
BA_REL_ "GenSigSuprvResp" BU_SG_REL_ EBCM_HS SG_ 500 DSMSS_DrvSelMd2Un 1;
BA_REL_ "GenSigTimeoutMsg" BU_SG_REL_ EBCM_HS SG_ 500 DSMSS_DrvSelMd2Un 500;
BA_REL_ "GenSigTimeoutTime" BU_SG_REL_ EBCM_HS SG_ 500 DSMSS_DrvSelMd2Un 250;
BA_REL_ "GenSigSuprvResp" BU_SG_REL_ EBCM_OBD_HS SG_ 500 DSMSS_DrvSelMd1Un 1;
BA_REL_ "GenSigTimeoutMsg" BU_SG_REL_ EBCM_OBD_HS SG_ 500 DSMSS_DrvSelMd1Un 500;
BA_REL_ "GenSigTimeoutTime" BU_SG_REL_ EBCM_OBD_HS SG_ 500 DSMSS_DrvSelMd1Un 250;
BA_REL_ "GenSigSuprvResp" BU_SG_REL_ EBCM_HS SG_ 500 DSMSS_DrvSelMd1Un 1;
BA_REL_ "GenSigTimeoutMsg" BU_SG_REL_ EBCM_HS SG_ 500 DSMSS_DrvSelMd1Un 500;
BA_REL_ "GenSigTimeoutTime" BU_SG_REL_ EBCM_HS SG_ 500 DSMSS_DrvSelMd1Un 250;
BA_REL_ "GenSigSuprvResp" BU_SG_REL_ EBCM_OBD_HS SG_ 500 DrvSelMd1Stat 1;
BA_REL_ "GenSigTimeoutMsg" BU_SG_REL_ EBCM_OBD_HS SG_ 500 DrvSelMd1Stat 500;
BA_REL_ "GenSigTimeoutTime" BU_SG_REL_ EBCM_OBD_HS SG_ 500 DrvSelMd1Stat 250;
BA_REL_ "GenSigSuprvResp" BU_SG_REL_ EBCM_HS SG_ 500 DrvSelMd1Stat 1;
BA_REL_ "GenSigTimeoutMsg" BU_SG_REL_ EBCM_HS SG_ 500 DrvSelMd1Stat 500;
BA_REL_ "GenSigTimeoutTime" BU_SG_REL_ EBCM_HS SG_ 500 DrvSelMd1Stat 250;
BA_REL_ "GenSigSuprvResp" BU_SG_REL_ TCM_HS SG_ 1417 PrplsnTrqRelCap 1;
BA_REL_ "GenSigTimeoutMsg" BU_SG_REL_ TCM_HS SG_ 1417 PrplsnTrqRelCap 1417;
BA_REL_ "GenSigTimeoutTime" BU_SG_REL_ TCM_HS SG_ 1417 PrplsnTrqRelCap 1250;
BA_REL_ "GenSigSuprvResp" BU_SG_REL_ PFAF_HS SG_ 188 MtrBSpd 1;
BA_REL_ "GenSigTimeoutMsg" BU_SG_REL_ PFAF_HS SG_ 188 MtrBSpd 188;
BA_REL_ "GenSigTimeoutTime" BU_SG_REL_ PFAF_HS SG_ 188 MtrBSpd 250;
BA_REL_ "GenSigSuprvResp" BU_SG_REL_ TCM_HS SG_ 170 AccPos 1;
BA_REL_ "GenSigTimeoutMsg" BU_SG_REL_ TCM_HS SG_ 170 AccPos 170;
BA_REL_ "GenSigTimeoutTime" BU_SG_REL_ TCM_HS SG_ 170 AccPos 250;
BA_REL_ "GenSigSuprvResp" BU_SG_REL_ ECM_HS SG_ 1221 SpdLmtVsnFsdSpdUnt 1;
BA_REL_ "GenSigTimeoutMsg" BU_SG_REL_ ECM_HS SG_ 1221 SpdLmtVsnFsdSpdUnt 1221;
BA_REL_ "GenSigTimeoutTime" BU_SG_REL_ ECM_HS SG_ 1221 SpdLmtVsnFsdSpdUnt 1250;
BA_REL_ "GenSigSuprvResp" BU_SG_REL_ ECM_HS SG_ 1221 SpdLmtVnFsSpdNwDet 1;
BA_REL_ "GenSigTimeoutMsg" BU_SG_REL_ ECM_HS SG_ 1221 SpdLmtVnFsSpdNwDet 1221;
BA_REL_ "GenSigTimeoutTime" BU_SG_REL_ ECM_HS SG_ 1221 SpdLmtVnFsSpdNwDet 1250;
BA_REL_ "GenSigSuprvResp" BU_SG_REL_ ECM_HS SG_ 1221 SpdLmtVsnFsdSpd 1;
BA_REL_ "GenSigTimeoutMsg" BU_SG_REL_ ECM_HS SG_ 1221 SpdLmtVsnFsdSpd 1221;
BA_REL_ "GenSigTimeoutTime" BU_SG_REL_ ECM_HS SG_ 1221 SpdLmtVsnFsdSpd 1250;
BA_REL_ "GenSigSuprvResp" BU_SG_REL_ VICM2_HS SG_ 1221 CCClntCrcFlwRtReq 1;
BA_REL_ "GenSigTimeoutMsg" BU_SG_REL_ VICM2_HS SG_ 1221 CCClntCrcFlwRtReq 1221;
BA_REL_ "GenSigTimeoutTime" BU_SG_REL_ VICM2_HS SG_ 1221 CCClntCrcFlwRtReq 1250;
BA_REL_ "GenSigSuprvResp" BU_SG_REL_ ECM_HS SG_ 1243 CSERDTC_CdNum 1;
BA_REL_ "GenSigTimeoutMsg" BU_SG_REL_ ECM_HS SG_ 1243 CSERDTC_CdNum 1243;
BA_REL_ "GenSigTimeoutTime" BU_SG_REL_ ECM_HS SG_ 1243 CSERDTC_CdNum 1250;
BA_REL_ "GenSigSuprvResp" BU_SG_REL_ ECM_HS SG_ 1243 CSERDTC_SysDes 1;
BA_REL_ "GenSigTimeoutMsg" BU_SG_REL_ ECM_HS SG_ 1243 CSERDTC_SysDes 1243;
BA_REL_ "GenSigTimeoutTime" BU_SG_REL_ ECM_HS SG_ 1243 CSERDTC_SysDes 1250;
BA_REL_ "GenSigSuprvResp" BU_SG_REL_ ECM_HS SG_ 1243 ChsSysEmmRelMalfAct 1;
BA_REL_ "GenSigTimeoutMsg" BU_SG_REL_ ECM_HS SG_ 1243 ChsSysEmmRelMalfAct 1243;
BA_REL_ "GenSigTimeoutTime" BU_SG_REL_ ECM_HS SG_ 1243 ChsSysEmmRelMalfAct 1250;
BA_REL_ "GenSigSuprvResp" BU_SG_REL_ TCM_HS SG_ 979 PTABR_AccReq 1;
BA_REL_ "GenSigTimeoutMsg" BU_SG_REL_ TCM_HS SG_ 979 PTABR_AccReq 979;
BA_REL_ "GenSigTimeoutTime" BU_SG_REL_ TCM_HS SG_ 979 PTABR_AccReq 250;
BA_REL_ "GenSigSuprvResp" BU_SG_REL_ TCM_HS SG_ 979 PTABR_PTBrkRqAct 1;
BA_REL_ "GenSigTimeoutMsg" BU_SG_REL_ TCM_HS SG_ 979 PTABR_PTBrkRqAct 979;
BA_REL_ "GenSigTimeoutTime" BU_SG_REL_ TCM_HS SG_ 979 PTABR_PTBrkRqAct 250;
BA_REL_ "GenSigSuprvResp" BU_SG_REL_ BCM_HS SG_ 979 EngManfldAirTmp 1;
BA_REL_ "GenSigTimeoutMsg" BU_SG_REL_ BCM_HS SG_ 979 EngManfldAirTmp 979;
BA_REL_ "GenSigTimeoutTime" BU_SG_REL_ BCM_HS SG_ 979 EngManfldAirTmp 250;
BA_REL_ "GenSigSuprvResp" BU_SG_REL_ VICM_HS SG_ 546 ThrmlRfCmprElctrCrnt 1;
BA_REL_ "GenSigTimeoutMsg" BU_SG_REL_ VICM_HS SG_ 546 ThrmlRfCmprElctrCrnt 546;
BA_REL_ "GenSigTimeoutTime" BU_SG_REL_ VICM_HS SG_ 546 ThrmlRfCmprElctrCrnt 250;
BA_REL_ "GenSigSuprvResp" BU_SG_REL_ VICM_HS SG_ 546 ThrmlRfCmprElctrCrnt 1;
BA_REL_ "GenSigTimeoutMsg" BU_SG_REL_ VICM_HS SG_ 546 ThrmlRfCmprElctrCrnt 546;
BA_REL_ "GenSigTimeoutTime" BU_SG_REL_ VICM_HS SG_ 546 ThrmlRfCmprElctrCrnt 250;
BA_REL_ "GenSigSuprvResp" BU_SG_REL_ VICM_HS SG_ 546 ThrmlRefCompStat 1;
BA_REL_ "GenSigTimeoutMsg" BU_SG_REL_ VICM_HS SG_ 546 ThrmlRefCompStat 546;
BA_REL_ "GenSigTimeoutTime" BU_SG_REL_ VICM_HS SG_ 546 ThrmlRefCompStat 250;
BA_REL_ "GenSigSuprvResp" BU_SG_REL_ VICM_HS SG_ 546 ThrmlRefCompSpd 1;
BA_REL_ "GenSigTimeoutMsg" BU_SG_REL_ VICM_HS SG_ 546 ThrmlRefCompSpd 546;
BA_REL_ "GenSigTimeoutTime" BU_SG_REL_ VICM_HS SG_ 546 ThrmlRefCompSpd 250;
BA_REL_ "GenSigSuprvResp" BU_SG_REL_ VICM_HS SG_ 546 ThrmlRefCompElecPwr 1;
BA_REL_ "GenSigTimeoutMsg" BU_SG_REL_ VICM_HS SG_ 546 ThrmlRefCompElecPwr 546;
BA_REL_ "GenSigTimeoutTime" BU_SG_REL_ VICM_HS SG_ 546 ThrmlRefCompElecPwr 250;
BA_REL_ "GenSigSuprvResp" BU_SG_REL_ AHL_AFL_HS SG_ 1027 FCO4D_ObjVertVar 1;
BA_REL_ "GenSigTimeoutMsg" BU_SG_REL_ AHL_AFL_HS SG_ 1027 FCO4D_ObjVertVar 1027;
BA_REL_ "GenSigTimeoutTime" BU_SG_REL_ AHL_AFL_HS SG_ 1027 FCO4D_ObjVertVar 250;
BA_REL_ "GenSigSuprvResp" BU_SG_REL_ AHL_AFL_HS SG_ 1027 FCO4D_ObjVertPos 1;
BA_REL_ "GenSigTimeoutMsg" BU_SG_REL_ AHL_AFL_HS SG_ 1027 FCO4D_ObjVertPos 1027;
BA_REL_ "GenSigTimeoutTime" BU_SG_REL_ AHL_AFL_HS SG_ 1027 FCO4D_ObjVertPos 250;
BA_REL_ "GenSigSuprvResp" BU_SG_REL_ AHL_AFL_HS SG_ 1027 FCO4D_ObjTyp 1;
BA_REL_ "GenSigTimeoutMsg" BU_SG_REL_ AHL_AFL_HS SG_ 1027 FCO4D_ObjTyp 1027;
BA_REL_ "GenSigTimeoutTime" BU_SG_REL_ AHL_AFL_HS SG_ 1027 FCO4D_ObjTyp 250;
BA_REL_ "GenSigSuprvResp" BU_SG_REL_ AHL_AFL_HS SG_ 1027 FCO4D_ObjQlty 1;
BA_REL_ "GenSigTimeoutMsg" BU_SG_REL_ AHL_AFL_HS SG_ 1027 FCO4D_ObjQlty 1027;
BA_REL_ "GenSigTimeoutTime" BU_SG_REL_ AHL_AFL_HS SG_ 1027 FCO4D_ObjQlty 250;
BA_REL_ "GenSigSuprvResp" BU_SG_REL_ AHL_AFL_HS SG_ 1027 FCO4D_ObjId 1;
BA_REL_ "GenSigTimeoutMsg" BU_SG_REL_ AHL_AFL_HS SG_ 1027 FCO4D_ObjId 1027;
BA_REL_ "GenSigTimeoutTime" BU_SG_REL_ AHL_AFL_HS SG_ 1027 FCO4D_ObjId 250;
BA_REL_ "GenSigSuprvResp" BU_SG_REL_ AHL_AFL_HS SG_ 1027 FCO4D_ObjHorzPos 1;
BA_REL_ "GenSigTimeoutMsg" BU_SG_REL_ AHL_AFL_HS SG_ 1027 FCO4D_ObjHorzPos 1027;
BA_REL_ "GenSigTimeoutTime" BU_SG_REL_ AHL_AFL_HS SG_ 1027 FCO4D_ObjHorzPos 250;
BA_REL_ "GenSigSuprvResp" BU_SG_REL_ AHL_AFL_HS SG_ 1027 FCO4D_ObjHorzDim 1;
BA_REL_ "GenSigTimeoutMsg" BU_SG_REL_ AHL_AFL_HS SG_ 1027 FCO4D_ObjHorzDim 1027;
BA_REL_ "GenSigTimeoutTime" BU_SG_REL_ AHL_AFL_HS SG_ 1027 FCO4D_ObjHorzDim 250;
BA_REL_ "GenSigSuprvResp" BU_SG_REL_ AHL_AFL_HS SG_ 1027 FCO4D_ObjDist 1;
BA_REL_ "GenSigTimeoutMsg" BU_SG_REL_ AHL_AFL_HS SG_ 1027 FCO4D_ObjDist 1027;
BA_REL_ "GenSigTimeoutTime" BU_SG_REL_ AHL_AFL_HS SG_ 1027 FCO4D_ObjDist 250;
BA_REL_ "GenSigSuprvResp" BU_SG_REL_ AHL_AFL_HS SG_ 1027 FCO4D_DetMthd 1;
BA_REL_ "GenSigTimeoutMsg" BU_SG_REL_ AHL_AFL_HS SG_ 1027 FCO4D_DetMthd 1027;
BA_REL_ "GenSigTimeoutTime" BU_SG_REL_ AHL_AFL_HS SG_ 1027 FCO4D_DetMthd 250;
BA_REL_ "GenSigSuprvResp" BU_SG_REL_ AHL_AFL_HS SG_ 1026 FCO3D_ObjVertVar 1;
BA_REL_ "GenSigTimeoutMsg" BU_SG_REL_ AHL_AFL_HS SG_ 1026 FCO3D_ObjVertVar 1026;
BA_REL_ "GenSigTimeoutTime" BU_SG_REL_ AHL_AFL_HS SG_ 1026 FCO3D_ObjVertVar 250;
BA_REL_ "GenSigSuprvResp" BU_SG_REL_ AHL_AFL_HS SG_ 1026 FCO3D_ObjVertPos 1;
BA_REL_ "GenSigTimeoutMsg" BU_SG_REL_ AHL_AFL_HS SG_ 1026 FCO3D_ObjVertPos 1026;
BA_REL_ "GenSigTimeoutTime" BU_SG_REL_ AHL_AFL_HS SG_ 1026 FCO3D_ObjVertPos 250;
BA_REL_ "GenSigSuprvResp" BU_SG_REL_ AHL_AFL_HS SG_ 1026 FCO3D_ObjQlty 1;
BA_REL_ "GenSigTimeoutMsg" BU_SG_REL_ AHL_AFL_HS SG_ 1026 FCO3D_ObjQlty 1026;
BA_REL_ "GenSigTimeoutTime" BU_SG_REL_ AHL_AFL_HS SG_ 1026 FCO3D_ObjQlty 250;
BA_REL_ "GenSigSuprvResp" BU_SG_REL_ AHL_AFL_HS SG_ 1026 FCO3D_ObjDist 1;
BA_REL_ "GenSigTimeoutMsg" BU_SG_REL_ AHL_AFL_HS SG_ 1026 FCO3D_ObjDist 1026;
BA_REL_ "GenSigTimeoutTime" BU_SG_REL_ AHL_AFL_HS SG_ 1026 FCO3D_ObjDist 250;
BA_REL_ "GenSigSuprvResp" BU_SG_REL_ AHL_AFL_HS SG_ 1026 FCO3D_DetMthd 1;
BA_REL_ "GenSigTimeoutMsg" BU_SG_REL_ AHL_AFL_HS SG_ 1026 FCO3D_DetMthd 1026;
BA_REL_ "GenSigTimeoutTime" BU_SG_REL_ AHL_AFL_HS SG_ 1026 FCO3D_DetMthd 250;
BA_REL_ "GenSigSuprvResp" BU_SG_REL_ AHL_AFL_HS SG_ 1026 FCO3D_ObjHorzPos 1;
BA_REL_ "GenSigTimeoutMsg" BU_SG_REL_ AHL_AFL_HS SG_ 1026 FCO3D_ObjHorzPos 1026;
BA_REL_ "GenSigTimeoutTime" BU_SG_REL_ AHL_AFL_HS SG_ 1026 FCO3D_ObjHorzPos 250;
BA_REL_ "GenSigSuprvResp" BU_SG_REL_ AHL_AFL_HS SG_ 1026 FCO3D_ObjHorzDim 1;
BA_REL_ "GenSigTimeoutMsg" BU_SG_REL_ AHL_AFL_HS SG_ 1026 FCO3D_ObjHorzDim 1026;
BA_REL_ "GenSigTimeoutTime" BU_SG_REL_ AHL_AFL_HS SG_ 1026 FCO3D_ObjHorzDim 250;
BA_REL_ "GenSigSuprvResp" BU_SG_REL_ AHL_AFL_HS SG_ 1026 FCO3D_ObjTyp 1;
BA_REL_ "GenSigTimeoutMsg" BU_SG_REL_ AHL_AFL_HS SG_ 1026 FCO3D_ObjTyp 1026;
BA_REL_ "GenSigTimeoutTime" BU_SG_REL_ AHL_AFL_HS SG_ 1026 FCO3D_ObjTyp 250;
BA_REL_ "GenSigSuprvResp" BU_SG_REL_ AHL_AFL_HS SG_ 1026 FCO3D_ObjId 1;
BA_REL_ "GenSigTimeoutMsg" BU_SG_REL_ AHL_AFL_HS SG_ 1026 FCO3D_ObjId 1026;
BA_REL_ "GenSigTimeoutTime" BU_SG_REL_ AHL_AFL_HS SG_ 1026 FCO3D_ObjId 250;
BA_REL_ "GenSigSuprvResp" BU_SG_REL_ AHL_AFL_HS SG_ 1025 FCO2D_ObjQlty 1;
BA_REL_ "GenSigTimeoutMsg" BU_SG_REL_ AHL_AFL_HS SG_ 1025 FCO2D_ObjQlty 1025;
BA_REL_ "GenSigTimeoutTime" BU_SG_REL_ AHL_AFL_HS SG_ 1025 FCO2D_ObjQlty 250;
BA_REL_ "GenSigSuprvResp" BU_SG_REL_ AHL_AFL_HS SG_ 1025 FCO2D_ObjDist 1;
BA_REL_ "GenSigTimeoutMsg" BU_SG_REL_ AHL_AFL_HS SG_ 1025 FCO2D_ObjDist 1025;
BA_REL_ "GenSigTimeoutTime" BU_SG_REL_ AHL_AFL_HS SG_ 1025 FCO2D_ObjDist 250;
BA_REL_ "GenSigSuprvResp" BU_SG_REL_ AHL_AFL_HS SG_ 1025 FCO2D_ObjVertVar 1;
BA_REL_ "GenSigTimeoutMsg" BU_SG_REL_ AHL_AFL_HS SG_ 1025 FCO2D_ObjVertVar 1025;
BA_REL_ "GenSigTimeoutTime" BU_SG_REL_ AHL_AFL_HS SG_ 1025 FCO2D_ObjVertVar 250;
BA_REL_ "GenSigSuprvResp" BU_SG_REL_ AHL_AFL_HS SG_ 1025 FCO2D_ObjVertPos 1;
BA_REL_ "GenSigTimeoutMsg" BU_SG_REL_ AHL_AFL_HS SG_ 1025 FCO2D_ObjVertPos 1025;
BA_REL_ "GenSigTimeoutTime" BU_SG_REL_ AHL_AFL_HS SG_ 1025 FCO2D_ObjVertPos 250;
BA_REL_ "GenSigSuprvResp" BU_SG_REL_ AHL_AFL_HS SG_ 1025 FCO2D_ObjHorzDim 1;
BA_REL_ "GenSigTimeoutMsg" BU_SG_REL_ AHL_AFL_HS SG_ 1025 FCO2D_ObjHorzDim 1025;
BA_REL_ "GenSigTimeoutTime" BU_SG_REL_ AHL_AFL_HS SG_ 1025 FCO2D_ObjHorzDim 250;
BA_REL_ "GenSigSuprvResp" BU_SG_REL_ AHL_AFL_HS SG_ 1025 FCO2D_DetMthd 1;
BA_REL_ "GenSigTimeoutMsg" BU_SG_REL_ AHL_AFL_HS SG_ 1025 FCO2D_DetMthd 1025;
BA_REL_ "GenSigTimeoutTime" BU_SG_REL_ AHL_AFL_HS SG_ 1025 FCO2D_DetMthd 250;
BA_REL_ "GenSigSuprvResp" BU_SG_REL_ AHL_AFL_HS SG_ 1025 FCO2D_ObjHorzPos 1;
BA_REL_ "GenSigTimeoutMsg" BU_SG_REL_ AHL_AFL_HS SG_ 1025 FCO2D_ObjHorzPos 1025;
BA_REL_ "GenSigTimeoutTime" BU_SG_REL_ AHL_AFL_HS SG_ 1025 FCO2D_ObjHorzPos 250;
BA_REL_ "GenSigSuprvResp" BU_SG_REL_ AHL_AFL_HS SG_ 1025 FCO2D_ObjTyp 1;
BA_REL_ "GenSigTimeoutMsg" BU_SG_REL_ AHL_AFL_HS SG_ 1025 FCO2D_ObjTyp 1025;
BA_REL_ "GenSigTimeoutTime" BU_SG_REL_ AHL_AFL_HS SG_ 1025 FCO2D_ObjTyp 250;
BA_REL_ "GenSigSuprvResp" BU_SG_REL_ AHL_AFL_HS SG_ 1025 FCO2D_ObjId 1;
BA_REL_ "GenSigTimeoutMsg" BU_SG_REL_ AHL_AFL_HS SG_ 1025 FCO2D_ObjId 1025;
BA_REL_ "GenSigTimeoutTime" BU_SG_REL_ AHL_AFL_HS SG_ 1025 FCO2D_ObjId 250;
BA_REL_ "GenSigSuprvResp" BU_SG_REL_ AHL_AFL_HS SG_ 1024 FCO1D_ObjQlty 1;
BA_REL_ "GenSigTimeoutMsg" BU_SG_REL_ AHL_AFL_HS SG_ 1024 FCO1D_ObjQlty 1024;
BA_REL_ "GenSigTimeoutTime" BU_SG_REL_ AHL_AFL_HS SG_ 1024 FCO1D_ObjQlty 250;
BA_REL_ "GenSigSuprvResp" BU_SG_REL_ AHL_AFL_HS SG_ 1024 FCO1D_ObjDist 1;
BA_REL_ "GenSigTimeoutMsg" BU_SG_REL_ AHL_AFL_HS SG_ 1024 FCO1D_ObjDist 1024;
BA_REL_ "GenSigTimeoutTime" BU_SG_REL_ AHL_AFL_HS SG_ 1024 FCO1D_ObjDist 250;
BA_REL_ "GenSigSuprvResp" BU_SG_REL_ AHL_AFL_HS SG_ 1024 FCO1D_ObjVertVar 1;
BA_REL_ "GenSigTimeoutMsg" BU_SG_REL_ AHL_AFL_HS SG_ 1024 FCO1D_ObjVertVar 1024;
BA_REL_ "GenSigTimeoutTime" BU_SG_REL_ AHL_AFL_HS SG_ 1024 FCO1D_ObjVertVar 250;
BA_REL_ "GenSigSuprvResp" BU_SG_REL_ AHL_AFL_HS SG_ 1024 FCO1D_ObjVertPos 1;
BA_REL_ "GenSigTimeoutMsg" BU_SG_REL_ AHL_AFL_HS SG_ 1024 FCO1D_ObjVertPos 1024;
BA_REL_ "GenSigTimeoutTime" BU_SG_REL_ AHL_AFL_HS SG_ 1024 FCO1D_ObjVertPos 250;
BA_REL_ "GenSigSuprvResp" BU_SG_REL_ AHL_AFL_HS SG_ 1024 FCO1D_ObjHorzDim 1;
BA_REL_ "GenSigTimeoutMsg" BU_SG_REL_ AHL_AFL_HS SG_ 1024 FCO1D_ObjHorzDim 1024;
BA_REL_ "GenSigTimeoutTime" BU_SG_REL_ AHL_AFL_HS SG_ 1024 FCO1D_ObjHorzDim 250;
BA_REL_ "GenSigSuprvResp" BU_SG_REL_ AHL_AFL_HS SG_ 1024 FCO1D_DetMthd 1;
BA_REL_ "GenSigTimeoutMsg" BU_SG_REL_ AHL_AFL_HS SG_ 1024 FCO1D_DetMthd 1024;
BA_REL_ "GenSigTimeoutTime" BU_SG_REL_ AHL_AFL_HS SG_ 1024 FCO1D_DetMthd 250;
BA_REL_ "GenSigSuprvResp" BU_SG_REL_ AHL_AFL_HS SG_ 1024 FCO1D_ObjHorzPos 1;
BA_REL_ "GenSigTimeoutMsg" BU_SG_REL_ AHL_AFL_HS SG_ 1024 FCO1D_ObjHorzPos 1024;
BA_REL_ "GenSigTimeoutTime" BU_SG_REL_ AHL_AFL_HS SG_ 1024 FCO1D_ObjHorzPos 250;
BA_REL_ "GenSigSuprvResp" BU_SG_REL_ AHL_AFL_HS SG_ 1024 FCO1D_ObjTyp 1;
BA_REL_ "GenSigTimeoutMsg" BU_SG_REL_ AHL_AFL_HS SG_ 1024 FCO1D_ObjTyp 1024;
BA_REL_ "GenSigTimeoutTime" BU_SG_REL_ AHL_AFL_HS SG_ 1024 FCO1D_ObjTyp 250;
BA_REL_ "GenSigSuprvResp" BU_SG_REL_ AHL_AFL_HS SG_ 1024 FCO1D_ObjId 1;
BA_REL_ "GenSigTimeoutMsg" BU_SG_REL_ AHL_AFL_HS SG_ 1024 FCO1D_ObjId 1024;
BA_REL_ "GenSigTimeoutTime" BU_SG_REL_ AHL_AFL_HS SG_ 1024 FCO1D_ObjId 250;
BA_REL_ "GenSigSuprvResp" BU_SG_REL_ ICCM_OBD_HS SG_ 508 LonLatAccSnsChk 1;
BA_REL_ "GenSigTimeoutMsg" BU_SG_REL_ ICCM_OBD_HS SG_ 508 LonLatAccSnsChk 508;
BA_REL_ "GenSigTimeoutTime" BU_SG_REL_ ICCM_OBD_HS SG_ 508 LonLatAccSnsChk 250;
BA_REL_ "GenSigSuprvResp" BU_SG_REL_ ICCM_HS SG_ 508 LonLatAccSnsChk 1;
BA_REL_ "GenSigTimeoutMsg" BU_SG_REL_ ICCM_HS SG_ 508 LonLatAccSnsChk 508;
BA_REL_ "GenSigTimeoutTime" BU_SG_REL_ ICCM_HS SG_ 508 LonLatAccSnsChk 250;
BA_REL_ "GenSigSuprvResp" BU_SG_REL_ TCM_HS SG_ 508 LonLatAccSnsChk 1;
BA_REL_ "GenSigTimeoutMsg" BU_SG_REL_ TCM_HS SG_ 508 LonLatAccSnsChk 508;
BA_REL_ "GenSigTimeoutTime" BU_SG_REL_ TCM_HS SG_ 508 LonLatAccSnsChk 125;
BA_REL_ "GenSigSuprvResp" BU_SG_REL_ ICCM_OBD_HS SG_ 508 LonLatAccSnsValARC 1;
BA_REL_ "GenSigTimeoutMsg" BU_SG_REL_ ICCM_OBD_HS SG_ 508 LonLatAccSnsValARC 508;
BA_REL_ "GenSigTimeoutTime" BU_SG_REL_ ICCM_OBD_HS SG_ 508 LonLatAccSnsValARC 250;
BA_REL_ "GenSigSuprvResp" BU_SG_REL_ ICCM_HS SG_ 508 LonLatAccSnsValARC 1;
BA_REL_ "GenSigTimeoutMsg" BU_SG_REL_ ICCM_HS SG_ 508 LonLatAccSnsValARC 508;
BA_REL_ "GenSigTimeoutTime" BU_SG_REL_ ICCM_HS SG_ 508 LonLatAccSnsValARC 250;
BA_REL_ "GenSigSuprvResp" BU_SG_REL_ TCM_HS SG_ 508 LonLatAccSnsValARC 1;
BA_REL_ "GenSigTimeoutMsg" BU_SG_REL_ TCM_HS SG_ 508 LonLatAccSnsValARC 508;
BA_REL_ "GenSigTimeoutTime" BU_SG_REL_ TCM_HS SG_ 508 LonLatAccSnsValARC 125;
BA_REL_ "GenSigSuprvResp" BU_SG_REL_ ICCM_OBD_HS SG_ 508 LatAccSnsVal 1;
BA_REL_ "GenSigTimeoutMsg" BU_SG_REL_ ICCM_OBD_HS SG_ 508 LatAccSnsVal 508;
BA_REL_ "GenSigTimeoutTime" BU_SG_REL_ ICCM_OBD_HS SG_ 508 LatAccSnsVal 250;
BA_REL_ "GenSigSuprvResp" BU_SG_REL_ ICCM_HS SG_ 508 LatAccSnsVal 1;
BA_REL_ "GenSigTimeoutMsg" BU_SG_REL_ ICCM_HS SG_ 508 LatAccSnsVal 508;
BA_REL_ "GenSigTimeoutTime" BU_SG_REL_ ICCM_HS SG_ 508 LatAccSnsVal 250;
BA_REL_ "GenSigSuprvResp" BU_SG_REL_ TCM_HS SG_ 508 LatAccSnsVal 1;
BA_REL_ "GenSigTimeoutMsg" BU_SG_REL_ TCM_HS SG_ 508 LatAccSnsVal 508;
BA_REL_ "GenSigTimeoutTime" BU_SG_REL_ TCM_HS SG_ 508 LatAccSnsVal 125;
BA_REL_ "GenSigSuprvResp" BU_SG_REL_ ICCM_OBD_HS SG_ 508 LonAccSnsVal 1;
BA_REL_ "GenSigTimeoutMsg" BU_SG_REL_ ICCM_OBD_HS SG_ 508 LonAccSnsVal 508;
BA_REL_ "GenSigTimeoutTime" BU_SG_REL_ ICCM_OBD_HS SG_ 508 LonAccSnsVal 250;
BA_REL_ "GenSigSuprvResp" BU_SG_REL_ ICCM_HS SG_ 508 LonAccSnsVal 1;
BA_REL_ "GenSigTimeoutMsg" BU_SG_REL_ ICCM_HS SG_ 508 LonAccSnsVal 508;
BA_REL_ "GenSigTimeoutTime" BU_SG_REL_ ICCM_HS SG_ 508 LonAccSnsVal 250;
BA_REL_ "GenSigSuprvResp" BU_SG_REL_ TCM_HS SG_ 508 LonAccSnsVal 1;
BA_REL_ "GenSigTimeoutMsg" BU_SG_REL_ TCM_HS SG_ 508 LonAccSnsVal 508;
BA_REL_ "GenSigTimeoutTime" BU_SG_REL_ TCM_HS SG_ 508 LonAccSnsVal 125;
BA_REL_ "GenSigSuprvResp" BU_SG_REL_ ICCM_OBD_HS SG_ 508 CSTBATS_TrqVl 1;
BA_REL_ "GenSigTimeoutMsg" BU_SG_REL_ ICCM_OBD_HS SG_ 508 CSTBATS_TrqVl 508;
BA_REL_ "GenSigTimeoutTime" BU_SG_REL_ ICCM_OBD_HS SG_ 508 CSTBATS_TrqVl 250;
BA_REL_ "GenSigSuprvResp" BU_SG_REL_ ICCM_HS SG_ 508 CSTBATS_TrqVl 1;
BA_REL_ "GenSigTimeoutMsg" BU_SG_REL_ ICCM_HS SG_ 508 CSTBATS_TrqVl 508;
BA_REL_ "GenSigTimeoutTime" BU_SG_REL_ ICCM_HS SG_ 508 CSTBATS_TrqVl 250;
BA_REL_ "GenSigSuprvResp" BU_SG_REL_ TCM_HS SG_ 508 CSTBATS_TrqVl 1;
BA_REL_ "GenSigTimeoutMsg" BU_SG_REL_ TCM_HS SG_ 508 CSTBATS_TrqVl 508;
BA_REL_ "GenSigTimeoutTime" BU_SG_REL_ TCM_HS SG_ 508 CSTBATS_TrqVl 125;
BA_REL_ "GenSigSuprvResp" BU_SG_REL_ ICCM_OBD_HS SG_ 508 CSTBATS_TrqVlV 1;
BA_REL_ "GenSigTimeoutMsg" BU_SG_REL_ ICCM_OBD_HS SG_ 508 CSTBATS_TrqVlV 508;
BA_REL_ "GenSigTimeoutTime" BU_SG_REL_ ICCM_OBD_HS SG_ 508 CSTBATS_TrqVlV 250;
BA_REL_ "GenSigSuprvResp" BU_SG_REL_ ICCM_HS SG_ 508 CSTBATS_TrqVlV 1;
BA_REL_ "GenSigTimeoutMsg" BU_SG_REL_ ICCM_HS SG_ 508 CSTBATS_TrqVlV 508;
BA_REL_ "GenSigTimeoutTime" BU_SG_REL_ ICCM_HS SG_ 508 CSTBATS_TrqVlV 250;
BA_REL_ "GenSigSuprvResp" BU_SG_REL_ TCM_HS SG_ 508 CSTBATS_TrqVlV 1;
BA_REL_ "GenSigTimeoutMsg" BU_SG_REL_ TCM_HS SG_ 508 CSTBATS_TrqVlV 508;
BA_REL_ "GenSigTimeoutTime" BU_SG_REL_ TCM_HS SG_ 508 CSTBATS_TrqVlV 125;
BA_REL_ "GenSigSuprvResp" BU_SG_REL_ PCM_HS SG_ 422 TrStPTGrdBrkDsMdOvr 1;
BA_REL_ "GenSigTimeoutMsg" BU_SG_REL_ PCM_HS SG_ 422 TrStPTGrdBrkDsMdOvr 422;
BA_REL_ "GenSigTimeoutTime" BU_SG_REL_ PCM_HS SG_ 422 TrStPTGrdBrkDsMdOvr 62;
BA_REL_ "GenSigSuprvResp" BU_SG_REL_ ECM_HS SG_ 422 TrStPTGrdBrkDsMdOvr 1;
BA_REL_ "GenSigTimeoutMsg" BU_SG_REL_ ECM_HS SG_ 422 TrStPTGrdBrkDsMdOvr 422;
BA_REL_ "GenSigTimeoutTime" BU_SG_REL_ ECM_HS SG_ 422 TrStPTGrdBrkDsMdOvr 62;
VAL_ 1032 RdTyp 0 "Town" 1 "Country Road" 2 "Motorway" 3 "Unused and Reserved 1" 4 "Unused and Reserved 2" 5 "Unused and Reserved 3" 6 "Unused and Reserved 4" 7 "Undefined" ;
VAL_ 1032 FwdCamSysOpStat 0 "Unknown" 1 "Initializing" 2 "Inactive" 3 "Active" 4 "Unused and Reserved 1" 5 "Unused and Reserved 2" 6 "Unused and Reserved 3" 7 "Failed" ;
VAL_ 1032 EnvIllum 0 "Unknown" 1 "Lit Environment During Night" 2 "Unlit Environment During Night" 3 "Daylight" ;
VAL_ 1032 AutoHgBmSts 0 "Not Available" 1 "Inactive" 2 "Active" ;
VAL_ 1031 FCO8D_ObjTyp 0 "No Object" 1 "Headlamp" 2 "Rearlamp" 3 "Pair Headlamps" 4 "Pair Rearlamps" ;
VAL_ 1031 FCO8D_ObjQlty 0 "Less than 70%" 1 "70-85%" 2 "85-95%" 3 "95-100%" ;
VAL_ 1031 FCO8D_DetMthd 0 "Measured Object" 1 "Tracked Object" 2 "Initializing" 3 "Unavailable" ;
VAL_ 1030 FCO7D_ObjTyp 0 "No Object" 1 "Headlamp" 2 "Rearlamp" 3 "Pair Headlamps" 4 "Pair Rearlamps" ;
VAL_ 1030 FCO7D_ObjQlty 0 "Less than 70%" 1 "70-85%" 2 "85-95%" 3 "95-100%" ;
VAL_ 1030 FCO7D_DetMthd 0 "Measured Object" 1 "Tracked Object" 2 "Initializing" 3 "Unavailable" ;
VAL_ 479 ASIRI_Indication16 1 "true" 0 "false" ;
VAL_ 479 ASIRI_Indication15 1 "true" 0 "false" ;
VAL_ 479 ASIRI_Indication14 1 "true" 0 "false" ;
VAL_ 479 ASIRI_Indication13 1 "true" 0 "false" ;
VAL_ 479 ASIRI_Indication12 1 "true" 0 "false" ;
VAL_ 479 ASIRI_Indication11 1 "true" 0 "false" ;
VAL_ 479 ASIRI_Indication10 1 "true" 0 "false" ;
VAL_ 479 ASIRI_Indication09 1 "true" 0 "false" ;
VAL_ 479 ASIRI_Indication08 1 "true" 0 "false" ;
VAL_ 479 ASIRI_Indication07 1 "true" 0 "false" ;
VAL_ 479 ASIRI_Indication06 1 "true" 0 "false" ;
VAL_ 479 ASIRI_Indication05 1 "true" 0 "false" ;
VAL_ 479 ASIRI_Indication04 1 "true" 0 "false" ;
VAL_ 479 ASIRI_Indication03 1 "true" 0 "false" ;
VAL_ 479 ASIRI_Indication02 1 "true" 0 "false" ;
VAL_ 479 ASIRI_Indication01 1 "true" 0 "false" ;
VAL_ 479 PTWrmgWtToShftIO 1 "true" 0 "false" ;
VAL_ 479 PrplsnSysAtv 1 "true" 0 "false" ;
VAL_ 479 PTShftLvrLckRqd 1 "true" 0 "false" ;
VAL_ 211 ActAxleTrqV 1 "Invalid" 0 "Valid" ;
VAL_ 1020 OtsAirTmpEmsnsRelV 1 "Invalid" 0 "Valid" ;
VAL_ 1020 OATEmsnsRelCrValV 1 "Invalid" 0 "Valid" ;
VAL_ 1020 OATEmsnsRelCrValM 0 "Don't Use Data" 1 "Use Data" ;
VAL_ 1020 CatlystOutGasTempEstV 1 "Invalid" 0 "Valid" ;
VAL_ 1020 OtsAirTmpCrValMsk 0 "Don't Use Data" 1 "Use Data" ;
VAL_ 1020 OtsAirTmpV 1 "Invalid" 0 "Valid" ;
VAL_ 1020 OtsAirTmpCrValV 1 "Invalid" 0 "Valid" ;
VAL_ 1020 EngInltSpcfcHmdtyV 1 "Invalid" 0 "Valid" ;
VAL_ 1020 EngInltSpcfcHmdtyM 0 "Don't Use Data" 1 "Use Data" ;
VAL_ 1219 DslExhFldDiagWrnIdRq 0 "No Indication" 1 "Warning Level 1" 2 "Warning Level 2" 3 "Warning Level 3" 4 "Warning Level 4" 5 "Warning Level 5" 6 "Warning Level 6" 7 "Warning Level 7" ;
VAL_ 1219 DslEmnsOBDMrkt 0 "USEPA TIER 2 / CALIFORNIA LEV II" 1 "EURO5/6" ;
VAL_ 1219 DslExNxEmWrngIndRq 15 "Warning Level 15" 14 "Warning Level 14" 13 "Warning Level 13" 12 "Warning Level 12" 11 "Warning Level 11" 10 "Warning Level 10" 9 "Warning Level 9" 8 "Warning Level 8" 7 "Warning Level 7" 6 "Warning Level 6" 5 "Warning Level 5" 4 "Warning Level 4" 3 "Warning Level 3" 2 "Warning Level 2" 1 "Warning Level 1" 0 "No Indication" ;
VAL_ 1219 DslExFldTpWrngIndRq 15 "Warning Level 15" 14 "Warning Level 14" 13 "Warning Level 13" 12 "Warning Level 12" 11 "Warning Level 11" 10 "Warning Level 10" 9 "Warning Level 9" 8 "Warning Level 8" 7 "Warning Level 7" 6 "Warning Level 6" 5 "Warning Level 5" 4 "Warning Level 4" 3 "Warning Level 3" 2 "Warning Level 2" 1 "Warning Level 1" 0 "No Indication" ;
VAL_ 1219 DslExhFldQlyWrngIReq 15 "Warning Level 15" 14 "Warning Level 14" 13 "Warning Level 13" 12 "Warning Level 12" 11 "Warning Level 11" 10 "Warning Level 10" 9 "Warning Level 9" 8 "Warning Level 8" 7 "Warning Level 7" 6 "Warning Level 6" 5 "Warning Level 5" 4 "Warning Level 4" 3 "Warning Level 3" 2 "Warning Level 2" 1 "Warning Level 1" 0 "No Indication" ;
VAL_ 1219 DslExhFldWrngIdRqER 15 "Warning Level 15" 14 "Warning Level 14" 13 "Warning Level 13" 12 "Warning Level 12" 11 "Warning Level 11" 10 "Warning Level 10" 9 "Warning Level 9" 8 "Warning Level 8" 7 "Warning Level 7" 6 "Warning Level 6" 5 "Warning Level 5" 4 "Warning Level 4" 3 "Warning Level 3" 2 "Warning Level 2" 1 "Warning Level 1" 0 "No Indication" ;
VAL_ 1219 DslExFldCnWrngIndRq 15 "Warning Level 15" 14 "Warning Level 14" 13 "Warning Level 13" 12 "Warning Level 12" 11 "Warning Level 11" 10 "Warning Level 10" 9 "Warning Level 9" 8 "Warning Level 8" 7 "Warning Level 7" 6 "Warning Level 6" 5 "Warning Level 5" 4 "Warning Level 4" 3 "Warning Level 3" 2 "Warning Level 2" 1 "Warning Level 1" 0 "No Indication" ;
VAL_ 372 ARSFlrIO 1 "true" 0 "false" ;
VAL_ 528 BSABR_TrlBrkCntlIntRq 1 "true" 0 "false" ;
VAL_ 552 ThrmlRefCmpIGBTTmpV 0 "Valid" 1 "Invalid" ;
VAL_ 552 ThrmlRefCmpHiVltgInptV 0 "Valid" 1 "Invalid" ;
VAL_ 552 ThrmlRefCmpCPUHtSkTmpV 0 "Valid" 1 "Invalid" ;
VAL_ 442 CrksftTqMinImCapV 1 "Invalid" 0 "Valid" ;
VAL_ 442 CrksftMaxTrqLmtV 1 "Invalid" 0 "Valid" ;
VAL_ 753 EBCMDS5_DTCStatus 0 "Not Supported" 1 "Critically Disabled" 2 "No Status to Report" 3 "Diagnostic Passed" 4 "Diagnostic Failed" ;
VAL_ 753 EBCMDS4_DTCStatus 0 "Not Supported" 1 "Critically Disabled" 2 "No Status to Report" 3 "Diagnostic Passed" 4 "Diagnostic Failed" ;
VAL_ 753 EBCMDS3_DTCStatus 0 "Not Supported" 1 "Critically Disabled" 2 "No Status to Report" 3 "Diagnostic Passed" 4 "Diagnostic Failed" ;
VAL_ 753 EBCMDS2_DTCStatus 0 "Not Supported" 1 "Critically Disabled" 2 "No Status to Report" 3 "Diagnostic Passed" 4 "Diagnostic Failed" ;
VAL_ 753 EBCMDS1_DTCStatus 0 "Not Supported" 1 "Critically Disabled" 2 "No Status to Report" 3 "Diagnostic Passed" 4 "Diagnostic Failed" ;
VAL_ 989 RdHVCntctrShdwnReq 0 "None" 1 "Emergency Shutdown" 2 "Controlled Shutdown" 3 "Emergency Crash Shutdown" ;
VAL_ 989 AuxClntHtrVlvStat 7 "Unused and Reserved 2" 6 "De-Aeration Routine Active" 5 "Diagnostic Override" 4 "Re-Calibration" 3 "Fault Active" 2 "Engine Link" 1 "Transition" 0 "Engine Bypass" ;
VAL_ 989 EngCoolFanOpEnbl 1 "true" 0 "false" ;
VAL_ 989 DiagFreeRunCntrV 1 "Invalid" 0 "Valid" ;
VAL_ 989 MntnceMdStEngRq 1 "true" 0 "false" ;
VAL_ 989 RdHVCntctrCmdStat 0 "Open" 1 "Precharge" 2 "Close" ;
VAL_ 550 ACCMCII_DatStat 0 "Cal ID Index Not Used" 1 "Cal Verification Number Uncalculated" 2 "Cal Verification Number Calculated" ;
VAL_ 548 ACCMDSO_DTCStat 0 "Not Supported" 1 "Critically Disabled" 2 "No Status to Report" 3 "Diagnostic Passed" 4 "Diagnostic Failed" ;
VAL_ 548 ACCMDSI_DTCStat 0 "Not Supported" 1 "Critically Disabled" 2 "No Status to Report" 3 "Diagnostic Passed" 4 "Diagnostic Failed" ;
VAL_ 548 ACCMDSG_DTCStat 0 "Not Supported" 1 "Critically Disabled" 2 "No Status to Report" 3 "Diagnostic Passed" 4 "Diagnostic Failed" ;
VAL_ 988 AccPwrModMinCoolRq 0 "None" 1 "Minimum" 2 "Low" 3 "Medium" 4 "High" ;
VAL_ 988 A6ERRAlrmReq 2 "Cancel Alarm" 1 "Set Alarm" 0 "No Action" ;
VAL_ 988 MntnceMdDsplyRq 15 "Unused and Reserved" 14 "Continue FM" 13 "Force FM" 12 "FM 1 Day Warning" 11 "FM 2 Day Warning" 10 "FM 3 Day Warning" 9 "FM 4 Day Warning" 8 "FM 5 Day Warning" 7 "Continue EM" 6 "Force EM" 5 "EM 1 Day Warning" 4 "EM 2 Day Warning" 3 "EM 3 Day Warning" 2 "EM 4 Day Warning" 1 "EM 5 Day Warning" 0 "No Request" ;
VAL_ 988 EngMntnceMdAct 1 "true" 0 "false" ;
VAL_ 988 HVPropChgrUnbl 1 "true" 0 "false" ;
VAL_ 988 EngHtrValvBpasCmd 0 "Bypass Commanded" 1 "Normal Operation Allowed" ;
VAL_ 1029 FCO6D_ObjTyp 0 "No Object" 1 "Headlamp" 2 "Rearlamp" 3 "Pair Headlamps" 4 "Pair Rearlamps" ;
VAL_ 1029 FCO6D_ObjQlty 0 "Less than 70%" 1 "70-85%" 2 "85-95%" 3 "95-100%" ;
VAL_ 1029 FCO6D_DetMthd 0 "Measured Object" 1 "Tracked Object" 2 "Initializing" 3 "Unavailable" ;
VAL_ 1028 FCO5D_ObjTyp 0 "No Object" 1 "Headlamp" 2 "Rearlamp" 3 "Pair Headlamps" 4 "Pair Rearlamps" ;
VAL_ 1028 FCO5D_ObjQlty 0 "Less than 70%" 1 "70-85%" 2 "85-95%" 3 "95-100%" ;
VAL_ 1028 FCO5D_DetMthd 0 "Measured Object" 1 "Tracked Object" 2 "Initializing" 3 "Unavailable" ;
VAL_ 500 EnhDrvMdSwChUseAct 1 "true" 0 "false" ;
VAL_ 500 EnhDrvSelMdSwStat 0 "No Activation" 1 "Increment" 2 "Decrement" 3 "Faulted" ;
VAL_ 500 DrvSelMd8Stat 1 "Active" 0 "Inactive" ;
VAL_ 500 DrvSelMd8ReqDnd 1 "true" 0 "false" ;
VAL_ 500 DrvSelMd7Stat 1 "Active" 0 "Inactive" ;
VAL_ 500 DrvSelMd7ReqDnd 1 "true" 0 "false" ;
VAL_ 500 DrvSelMd6Stat 1 "Active" 0 "Inactive" ;
VAL_ 500 DrvSelMd6ReqDnd 1 "true" 0 "false" ;
VAL_ 500 DrvSelMd5Stat 1 "Active" 0 "Inactive" ;
VAL_ 500 DrvSelMd5ReqDnd 1 "true" 0 "false" ;
VAL_ 500 DrvSelMd4Stat 1 "Active" 0 "Inactive" ;
VAL_ 500 DrvSelMd4ReqDnd 1 "true" 0 "false" ;
VAL_ 500 DrvSelMd3Stat 1 "Active" 0 "Inactive" ;
VAL_ 500 DrvSelMd3ReqDnd 1 "true" 0 "false" ;
VAL_ 500 DrvSelMd2Stat 1 "Active" 0 "Inactive" ;
VAL_ 500 DrvSelMd2ReqDnd 1 "true" 0 "false" ;
VAL_ 500 DSMSS_DrvSelMd0Pn 1 "true" 0 "false" ;
VAL_ 500 DSMSS_DrvSelMd8Pn 1 "true" 0 "false" ;
VAL_ 500 DSMSS_DrvSelMd7Pn 1 "true" 0 "false" ;
VAL_ 500 DSMSS_DrvSelMd6Pn 1 "true" 0 "false" ;
VAL_ 500 DSMSS_DrvSelMd5Pn 1 "true" 0 "false" ;
VAL_ 500 DSMSS_DrvSelMd4Pn 1 "true" 0 "false" ;
VAL_ 500 DSMSS_DrvSelMd3Pn 1 "true" 0 "false" ;
VAL_ 500 DSMSS_DrvSelMd2Pn 1 "true" 0 "false" ;
VAL_ 500 DSMSS_DrvSelMd1Pn 1 "true" 0 "false" ;
VAL_ 500 DSMSS_DrvSelMd8Un 1 "true" 0 "false" ;
VAL_ 500 DSMSS_DrvSelMd7Un 1 "true" 0 "false" ;
VAL_ 500 DSMSS_DrvSelMd6Un 1 "true" 0 "false" ;
VAL_ 500 DSMSS_DrvSelMd5Un 1 "true" 0 "false" ;
VAL_ 500 DSMSS_DrvSelMd4Un 1 "true" 0 "false" ;
VAL_ 500 DSMSS_DrvSelMd3Un 1 "true" 0 "false" ;
VAL_ 500 DSMSS_DrvSelMd2Un 1 "true" 0 "false" ;
VAL_ 500 DSMSS_DrvSelMd1Un 1 "true" 0 "false" ;
VAL_ 500 DrvSelMd1ReqDnd 1 "true" 0 "false" ;
VAL_ 500 DrvSelMd1Stat 1 "Active" 0 "Inactive" ;
VAL_ 1417 ETC_EngOpMd 1 "Half Cylinders" 0 "All cylinders" ;
VAL_ 407 TrnsOvrallActTorqRatioV 1 "Invalid" 0 "Valid" ;
VAL_ 189 TrnsRtoCntlSysFlt 1 "true" 0 "false" ;
VAL_ 189 TrnsInpMinSpdRq 0 "Unused and Reserved" 1 "Speed Point 1" 2 "Speed Point 2" 3 "Speed Point 3" 4 "Speed Point 4" 5 "Speed Point 5" 6 "Speed Point 6" 7 "Speed Point 7" 8 "Speed Point 8" 9 "Speed Point 9" 10 "Speed Point 10" 11 "Speed Point 11" 12 "Speed Point 12" 13 "Speed Point 13" 14 "Speed Point 14" 15 "Speed Point 15" ;
VAL_ 187 TransCltch5FillCmd 0 "Exhaust Clutch" 1 "Fill Clutch" 2 "Lock Clutch" 3 "Prefill Clutch" ;
VAL_ 187 TransCltch4FillCmd 0 "Exhaust Clutch" 1 "Fill Clutch" 2 "Lock Clutch" 3 "Prefill Clutch" ;
VAL_ 185 TransCltch1FillCmd 0 "Exhaust Clutch" 1 "Fill Clutch" 2 "Lock Clutch" 3 "Prefill Clutch" ;
VAL_ 185 TransCltch1CntlRq 0 "No Control" 1 "Active Control" 2 "Passive Control" 3 "Unused and Reserved" ;
VAL_ 185 TransCltch5CntlRq 0 "No Control" 1 "Active Control" 2 "Passive Control" 3 "Unused and Reserved" ;
VAL_ 185 TransCltch4CntlRq 0 "No Control" 1 "Active Control" 2 "Passive Control" 3 "Unused and Reserved" ;
VAL_ 185 TransCltch3CntlRq 0 "No Control" 1 "Active Control" 2 "Passive Control" 3 "Unused and Reserved" ;
VAL_ 185 TransCltch2CntlRq 0 "No Control" 1 "Active Control" 2 "Passive Control" 3 "Unused and Reserved" ;
VAL_ 186 TransCltch3FillCmd 0 "Exhaust Clutch" 1 "Fill Clutch" 2 "Lock Clutch" 3 "Prefill Clutch" ;
VAL_ 186 TransCltch2FillCmd 0 "Exhaust Clutch" 1 "Fill Clutch" 2 "Lock Clutch" 3 "Prefill Clutch" ;
VAL_ 152 TransClch5FlAch 1 "true" 0 "false" ;
VAL_ 152 TransClch5_Avail 1 "true" 0 "false" ;
VAL_ 152 TransClch4FlAch 1 "true" 0 "false" ;
VAL_ 152 TransClch4_Avail 1 "true" 0 "false" ;
VAL_ 151 TransClch3FlAch 1 "true" 0 "false" ;
VAL_ 151 TransClch3_Avail 1 "true" 0 "false" ;
VAL_ 151 TransClch2FlAch 1 "true" 0 "false" ;
VAL_ 151 TransClch2_Avail 1 "true" 0 "false" ;
VAL_ 150 TrnsInpDvcStat 7 "Unused and Reserved 5" 6 "Unused and Reserved 4" 5 "Unused and Reserved 3" 4 "Unused and Reserved 2" 3 "Unused and Reserved 1" 2 "Permanent Isolation" 1 "Temporary Isolation" 0 "Normal Control" ;
VAL_ 150 TransInhibitNeut 1 "true" 0 "false" ;
VAL_ 150 TransInhibitMode2 1 "true" 0 "false" ;
VAL_ 150 TransInhibitMode1 1 "true" 0 "false" ;
VAL_ 150 TransInhibitGear4 1 "true" 0 "false" ;
VAL_ 150 TransInhibitGear3 1 "true" 0 "false" ;
VAL_ 150 TransInhibitGear2 1 "true" 0 "false" ;
VAL_ 150 TransInhibitGear1 1 "true" 0 "false" ;
VAL_ 150 TrnsPTSysShtdwnRq 1 "true" 0 "false" ;
VAL_ 150 TransClch1FlAch 1 "true" 0 "false" ;
VAL_ 150 TransClch1_Avail 1 "true" 0 "false" ;
VAL_ 188 HybTransStCmmnd 0 "Neutral" 1 "Mode 1" 2 "Mode 2" 3 "Mode 3" 4 "Mode 4" 5 "Gear 1" 6 "Gear 2" 7 "Gear 3" 8 "Gear 4" 9 "Unused and Reserved 1" 10 "Unused and Reserved 2" 11 "Unused and Reserved 3" 12 "Unused and Reserved 4" 13 "Unused and Reserved 5" 14 "Unused and Reserved 6" 15 "Unused and Reserved 7" ;
VAL_ 188 HybTransStAchvd 0 "Neutral Stable State" 1 "EVT Mode 1 Stable State" 2 "EVT Mode 2 Stable State" 3 "EVT Mode 3 Stable State" 4 "EVT Mode 4 Stable State" 5 "Gear 1 Stable State" 6 "Gear 2 Stable State" 7 "Gear 3 Stable State" 8 "Gear 4 Stable State" 9 "Unused and Reserved 1" 10 "Unused and Reserved 2" 11 "Unused and Reserved 3" 12 "Unused and Reserved 4" 13 "Unused and Reserved 5" 14 "Unused and Reserved 6" 15 "Unused and Reserved 7" ;
VAL_ 188 TransFldPmpCmd 0 "Normal" 1 "Prime On" 2 "Off" 3 "On" ;
VAL_ 188 TransDirctnStV 1 "Invalid" 0 "Valid" ;
VAL_ 188 TransDirctnSt 0 "Between Positions" 1 "Park" 2 "Reverse" 3 "Neutral" 4 "Drive" 5 "Unknown" ;
VAL_ 188 TnsClchFlLnePrsBstRq 1 "true" 0 "false" ;
VAL_ 188 TransAuxPumpAvail 1 "true" 0 "false" ;
VAL_ 188 MtrBSpdV 0 "Valid" 1 "Invalid" ;
VAL_ 188 MtrASpdV 0 "Valid" 1 "Invalid" ;
VAL_ 170 EngCommFlrRedPwrCm 1 "true" 0 "false" ;
VAL_ 170 CmndAxlTrqRespTyp 0 "Inactive" 1 "Pleasability Limit" 2 "Maximum Range" 3 "Automatic Actuator Selection" ;
VAL_ 1221 SpdLmtVsnFsdSpdUnt 0 "km/h" 1 "mph" ;
VAL_ 1221 SpdLmtVnFsSpdNwDet 1 "true" 0 "false" ;
VAL_ 1221 SpdLmtVsnFsdSpdM 0 "Don't Use Data" 1 "Use Data" ;
VAL_ 1243 CSERDTC_SysDes 0 "P0-Powertrain Codes SAE Controlled" 1 "P1-Powertrain Codes MFG Controlled" 2 "P2-Powertrain Codes Reserved" 3 "P3-Powertrain Codes Reserved" 4 "C0-Chassis Codes SAE Controlled" 5 "C1-Chassis Codes MFG Controlled" 6 "C2-Chassis Codes Reserved" 7 "C3-Chassis Codes Reserved" 8 "B0-Body Codes SAE Controlled" 9 "B1-Body Codes MFG Controlled" 10 "B2-Body Codes Reserved" 11 "B3-Body Codes Reserved" 12 "U0-Network Codes SAE Controlled" 13 "U1-Network Codes MFG Controlled" 14 "U2- Network Codes Reserved" 15 "U3-Network Codes Reserved" ;
VAL_ 1243 ChsSysEmmRelMalfAct 1 "true" 0 "false" ;
VAL_ 979 PTABR_PTBrkRqAct 1 "true" 0 "false" ;
VAL_ 979 BrkBstVacV 1 "Invalid" 0 "Valid" ;
VAL_ 979 EngManfldAirTmpV 1 "Invalid" 0 "Valid" ;
VAL_ 546 ThrmlRfCmprElctrCrntV 0 "Valid" 1 "Invalid" ;
VAL_ 546 ThrmlRefCompStat 0 "Normal Operation" 1 "Degraded Operation" 2 "Inoperative" 3 "Invalid" ;
VAL_ 546 ThrmlRefCompSpdV 1 "Invalid" 0 "Valid" ;
VAL_ 546 ThrmlRfCmpOvTmpFltPr 1 "true" 0 "false" ;
VAL_ 546 ThrmlRefCompElecPwrV 1 "Invalid" 0 "Valid" ;
VAL_ 530 RstVTDTmprDtctd 1 "Reset" 0 "No Action" ;
VAL_ 530 RstIllDrIdDevDtctd 1 "Reset" 0 "No Action" ;
VAL_ 530 RstDrIdDevLrnd 1 "Reset" 0 "No Action" ;
VAL_ 1239 BattSOXStat 1 "Use SOC,SOH, & SOF" 0 "Don't Use SOC,SOH, & SOF" ;
VAL_ 1239 BattTempV 1 "Invalid" 0 "Valid" ;
VAL_ 1027 FCO4D_ObjTyp 0 "No Object" 1 "Headlamp" 2 "Rearlamp" 3 "Pair Headlamps" 4 "Pair Rearlamps" ;
VAL_ 1027 FCO4D_ObjQlty 0 "Less than 70%" 1 "70-85%" 2 "85-95%" 3 "95-100%" ;
VAL_ 1027 FCO4D_DetMthd 0 "Measured Object" 1 "Tracked Object" 2 "Initializing" 3 "Unavailable" ;
VAL_ 1026 FCO3D_ObjQlty 0 "Less than 70%" 1 "70-85%" 2 "85-95%" 3 "95-100%" ;
VAL_ 1026 FCO3D_DetMthd 0 "Measured Object" 1 "Tracked Object" 2 "Initializing" 3 "Unavailable" ;
VAL_ 1026 FCO3D_ObjTyp 0 "No Object" 1 "Headlamp" 2 "Rearlamp" 3 "Pair Headlamps" 4 "Pair Rearlamps" ;
VAL_ 1025 FCO2D_ObjQlty 0 "Less than 70%" 1 "70-85%" 2 "85-95%" 3 "95-100%" ;
VAL_ 1025 FCO2D_DetMthd 0 "Measured Object" 1 "Tracked Object" 2 "Initializing" 3 "Unavailable" ;
VAL_ 1025 FCO2D_ObjTyp 0 "No Object" 1 "Headlamp" 2 "Rearlamp" 3 "Pair Headlamps" 4 "Pair Rearlamps" ;
VAL_ 1024 FCO1D_ObjQlty 0 "Less than 70%" 1 "70-85%" 2 "85-95%" 3 "95-100%" ;
VAL_ 1024 FCO1D_DetMthd 0 "Measured Object" 1 "Tracked Object" 2 "Initializing" 3 "Unavailable" ;
VAL_ 1024 FCO1D_ObjTyp 0 "No Object" 1 "Headlamp" 2 "Rearlamp" 3 "Pair Headlamps" 4 "Pair Rearlamps" ;
VAL_ 508 CSTBATS_TrqVlV 1 "Invalid" 0 "Valid" ;
VAL_ 422 TrStPTGrdBrkDsMdOvr 3 "Unused and Reserved" 2 "To Grade Braking Disable" 1 "To Not Grade Braking Disable" 0 "No Override" ;
VAL_ 422 TrnsHybEngSrtStpOvrd 2 "Engine Off" 1 "Engine On" 0 "No Override" ;
SIG_GROUP_ 1031 FwdCamObj8Det 1 : FCO8D_ObjVertVar FCO8D_ObjVertPos FCO8D_ObjTyp FCO8D_ObjQlty FCO8D_ObjId FCO8D_ObjHorzPos FCO8D_ObjHorzDim FCO8D_ObjDist FCO8D_DetMthd;
SIG_GROUP_ 1030 FwdCamObj7Det 1 : FCO7D_ObjVertVar FCO7D_ObjVertPos FCO7D_ObjTyp FCO7D_ObjQlty FCO7D_ObjId FCO7D_ObjHorzPos FCO7D_ObjHorzDim FCO7D_ObjDist FCO7D_DetMthd;
SIG_GROUP_ 479 AutoStpInhbtRsnInd 1 : ASIRI_Indication16 ASIRI_Indication15 ASIRI_Indication14 ASIRI_Indication13 ASIRI_Indication12 ASIRI_Indication11 ASIRI_Indication10 ASIRI_Indication09 ASIRI_Indication08 ASIRI_Indication07 ASIRI_Indication06 ASIRI_Indication05 ASIRI_Indication04 ASIRI_Indication03 ASIRI_Indication02 ASIRI_Indication01;
SIG_GROUP_ 1219 DslExFldWrngVSpdLmt 1 : DEFWVSL_S3SpdLmt DEFWVSL_S2SpdLmt DEFWVSL_S1SpdLmt;
SIG_GROUP_ 528 BrkSysAutBrkReq 1 : BSABR_TrlBrkRq BSABR_TrlBrkCntlIntRq;
SIG_GROUP_ 753 ElecBrkCntlMdlDiagSt5 1 : EBCMDS5_DTCStatus EBCMDS5_DTCIndex;
SIG_GROUP_ 753 ElecBrkCntlMdlDiagSt4 1 : EBCMDS4_DTCStatus EBCMDS4_DTCIndex;
SIG_GROUP_ 753 ElecBrkCntlMdlDiagSt3 1 : EBCMDS3_DTCStatus EBCMDS3_DTCIndex;
SIG_GROUP_ 753 ElecBrkCntlMdlDiagSt2 1 : EBCMDS2_DTCStatus EBCMDS2_DTCIndex;
SIG_GROUP_ 753 ElecBrkCntlMdlDiagSt1 1 : EBCMDS1_DTCStatus EBCMDS1_DTCIndex;
SIG_GROUP_ 550 ACCModCalIdInf 1 : ACCMCII_DtBtG ACCMCII_DtBtF ACCMCII_DtBtE ACCMCII_DtBtD ACCMCII_DtBtC ACCMCII_DtBtB ACCMCII_DtBtA ACCMCII_SeqNum ACCMCII_Index ACCMCII_DatStat;
SIG_GROUP_ 548 ACCMDiagStatOut 1 : ACCMDSO_DTCStat ACCMDSO_DTCIndx;
SIG_GROUP_ 548 ACCMDiagStatInp 1 : ACCMDSI_DTCStat ACCMDSI_DTCIndx;
SIG_GROUP_ 548 ACCMDiagStatGnrl 1 : ACCMDSG_DTCStat ACCMDSG_DTCIndx;
SIG_GROUP_ 988 Alrm6ExtRngReq 1 : A6ERRAlrmTime A6ERRAlrmReq;
SIG_GROUP_ 1029 FwdCamObj6Det 1 : FCO6D_ObjVertVar FCO6D_ObjVertPos FCO6D_ObjTyp FCO6D_ObjQlty FCO6D_ObjId FCO6D_ObjHorzPos FCO6D_ObjHorzDim FCO6D_ObjDist FCO6D_DetMthd;
SIG_GROUP_ 1028 FwdCamObj5Det 1 : FCO5D_ObjVertVar FCO5D_ObjVertPos FCO5D_ObjTyp FCO5D_ObjQlty FCO5D_ObjId FCO5D_ObjHorzPos FCO5D_ObjHorzDim FCO5D_ObjDist FCO5D_DetMthd;
SIG_GROUP_ 500 DrvSelMdSelnStat 1 : DSMSS_DrvSelMd0Pn DSMSS_DrvSelMd8Pn DSMSS_DrvSelMd7Pn DSMSS_DrvSelMd6Pn DSMSS_DrvSelMd5Pn DSMSS_DrvSelMd4Pn DSMSS_DrvSelMd3Pn DSMSS_DrvSelMd2Pn DSMSS_DrvSelMd1Pn DSMSS_DrvSelMd8Un DSMSS_DrvSelMd7Un DSMSS_DrvSelMd6Un DSMSS_DrvSelMd5Un DSMSS_DrvSelMd4Un DSMSS_DrvSelMd3Un DSMSS_DrvSelMd2Un DSMSS_DrvSelMd1Un;
SIG_GROUP_ 1417 EngTorqCapblty 1 : ETC_MinTorq ETC_MinRunTorq ETC_MaxTorq ETC_RefEngSpd ETC_UnsdRsrvd ETC_FrmCntr ETC_EngOpMd;
SIG_GROUP_ 1243 ChsSysEmmRelDTC 1 : CSERDTC_CdNum CSERDTC_SysDes;
SIG_GROUP_ 979 PTAutoBrkReq 1 : PTABR_AccReq PTABR_PTBrkRqAct;
SIG_GROUP_ 1027 FwdCamObj4Det 1 : FCO4D_ObjVertVar FCO4D_ObjVertPos FCO4D_ObjTyp FCO4D_ObjQlty FCO4D_ObjId FCO4D_ObjHorzPos FCO4D_ObjHorzDim FCO4D_ObjDist FCO4D_DetMthd;
SIG_GROUP_ 1026 FwdCamObj3Det 1 : FCO3D_ObjVertVar FCO3D_ObjVertPos FCO3D_ObjQlty FCO3D_ObjDist FCO3D_DetMthd FCO3D_ObjHorzPos FCO3D_ObjHorzDim FCO3D_ObjTyp FCO3D_ObjId;
SIG_GROUP_ 1025 FwdCamObj2Det 1 : FCO2D_ObjQlty FCO2D_ObjDist FCO2D_ObjVertVar FCO2D_ObjVertPos FCO2D_ObjHorzDim FCO2D_DetMthd FCO2D_ObjHorzPos FCO2D_ObjTyp FCO2D_ObjId;
SIG_GROUP_ 1024 FwdCamObj1Det 1 : FCO1D_ObjQlty FCO1D_ObjDist FCO1D_ObjVertVar FCO1D_ObjVertPos FCO1D_ObjHorzDim FCO1D_DetMthd FCO1D_ObjHorzPos FCO1D_ObjTyp FCO1D_ObjId;
SIG_GROUP_ 508 ChsSysTtlBrkAxleTrqSt 1 : CSTBATS_TrqVl CSTBATS_TrqVlV;
